VERSION ""

NS_ :

BS_:

BU_: NBICU SBICU NBCMU SBCMU DAPP Vector_XXX

BO_ 2564357898 NBICU10_CellVotlage08: 8 NBICU
 SG_ NBICU10_Cell29Volt : 7|16@0+ (1,0) [0|65535] "mV"  NBCMU
 SG_ NBICU10_Cell30Volt : 23|16@0+ (1,0) [0|65535] "mV"  NBCMU
 SG_ NBICU10_Cell31Volt : 39|16@0+ (1,0) [0|65535] "mV"  NBCMU
 SG_ NBICU10_Cell32Volt : 55|16@0+ (1,0) [0|65535] "mV"  NBCMU

BO_ 2564423434 NBICU10_CellVotlage09: 8 NBICU
 SG_ NBICU10_Cell33Volt : 7|16@0+ (1,0) [0|65535] "mV"  NBCMU
 SG_ NBICU10_Cell34Volt : 23|16@0+ (1,0) [0|65535] "mV"  NBCMU
 SG_ NBICU10_Cell35Volt : 39|16@0+ (1,0) [0|65535] "mV"  NBCMU
 SG_ NBICU10_Cell36Volt : 55|16@0+ (1,0) [0|65535] "mV"  NBCMU

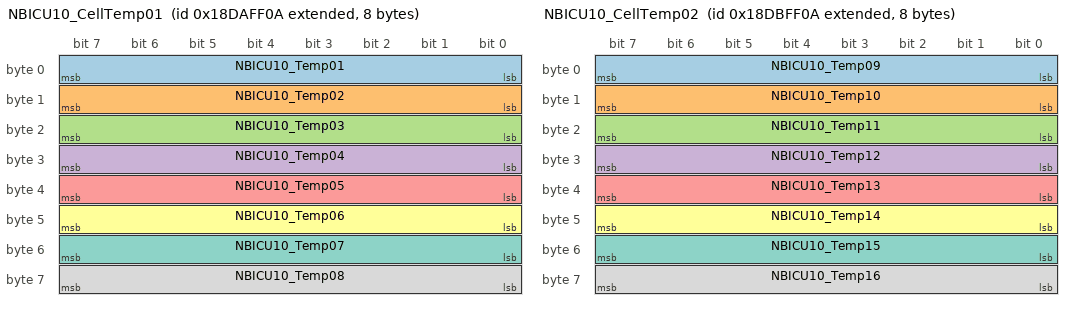
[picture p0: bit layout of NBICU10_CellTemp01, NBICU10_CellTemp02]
BO_ 2564488970 NBICU10_CellTemp01: 8 NBICU
 SG_ NBICU10_Temp01 : 7|8@0+ (1,-40) [-40|215] "℃"  NBCMU
 SG_ NBICU10_Temp02 : 15|8@0+ (1,-40) [-40|215] "℃"  NBCMU
 SG_ NBICU10_Temp03 : 23|8@0+ (1,-40) [-40|215] "℃"  NBCMU
 SG_ NBICU10_Temp04 : 31|8@0+ (1,-40) [-40|215] "℃"  NBCMU
 SG_ NBICU10_Temp05 : 39|8@0+ (1,-40) [-40|215] "℃"  NBCMU
 SG_ NBICU10_Temp06 : 47|8@0+ (1,-40) [-40|215] "℃"  NBCMU
 SG_ NBICU10_Temp07 : 55|8@0+ (1,-40) [-40|215] "℃"  NBCMU
 SG_ NBICU10_Temp08 : 63|8@0+ (1,-40) [-40|215] "℃"  NBCMU

BO_ 2564554506 NBICU10_CellTemp02: 8 NBICU
 SG_ NBICU10_Temp09 : 7|8@0+ (1,-40) [-40|215] "℃"  NBCMU
 SG_ NBICU10_Temp10 : 15|8@0+ (1,-40) [-40|215] "℃"  NBCMU
 SG_ NBICU10_Temp11 : 23|8@0+ (1,-40) [-40|215] "℃"  NBCMU
 SG_ NBICU10_Temp12 : 31|8@0+ (1,-40) [-40|215] "℃"  NBCMU
 SG_ NBICU10_Temp13 : 39|8@0+ (1,-40) [-40|215] "℃"  NBCMU
 SG_ NBICU10_Temp14 : 47|8@0+ (1,-40) [-40|215] "℃"  NBCMU
 SG_ NBICU10_Temp15 : 55|8@0+ (1,-40) [-40|215] "℃"  NBCMU
 SG_ NBICU10_Temp16 : 63|8@0+ (1,-40) [-40|215] "℃"  NBCMU

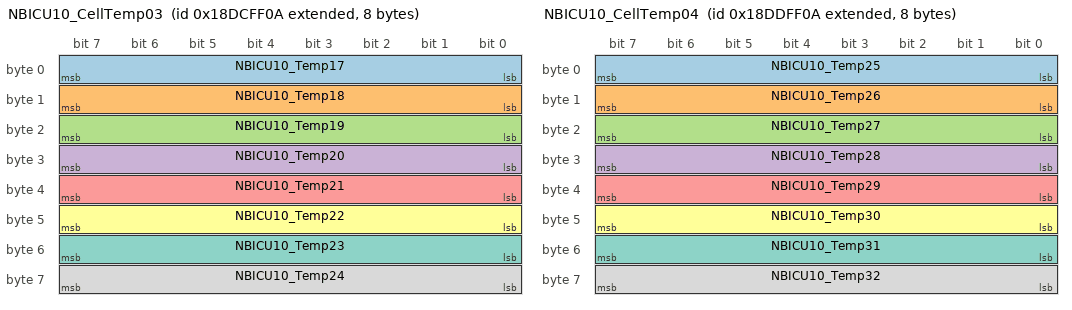
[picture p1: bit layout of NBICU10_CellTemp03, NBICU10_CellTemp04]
BO_ 2564620042 NBICU10_CellTemp03: 8 NBICU
 SG_ NBICU10_Temp17 : 7|8@0+ (1,-40) [-40|215] "℃"  NBCMU
 SG_ NBICU10_Temp18 : 15|8@0+ (1,-40) [-40|215] "℃"  NBCMU
 SG_ NBICU10_Temp19 : 23|8@0+ (1,-40) [-40|215] "℃"  NBCMU
 SG_ NBICU10_Temp20 : 31|8@0+ (1,-40) [-40|215] "℃"  NBCMU
 SG_ NBICU10_Temp21 : 39|8@0+ (1,-40) [-40|215] "℃"  NBCMU
 SG_ NBICU10_Temp22 : 47|8@0+ (1,-40) [-40|215] "℃"  NBCMU
 SG_ NBICU10_Temp23 : 55|8@0+ (1,-40) [-40|215] "℃"  NBCMU
 SG_ NBICU10_Temp24 : 63|8@0+ (1,-40) [-40|215] "℃"  NBCMU

BO_ 2564685578 NBICU10_CellTemp04: 8 NBICU
 SG_ NBICU10_Temp25 : 7|8@0+ (1,-40) [-40|215] "℃"  NBCMU
 SG_ NBICU10_Temp26 : 15|8@0+ (1,-40) [-40|215] "℃"  NBCMU
 SG_ NBICU10_Temp27 : 23|8@0+ (1,-40) [-40|215] "℃"  NBCMU
 SG_ NBICU10_Temp28 : 31|8@0+ (1,-40) [-40|215] "℃"  NBCMU
 SG_ NBICU10_Temp29 : 39|8@0+ (1,-40) [-40|215] "℃"  NBCMU
 SG_ NBICU10_Temp30 : 47|8@0+ (1,-40) [-40|215] "℃"  NBCMU
 SG_ NBICU10_Temp31 : 55|8@0+ (1,-40) [-40|215] "℃"  NBCMU
 SG_ NBICU10_Temp32 : 63|8@0+ (1,-40) [-40|215] "℃"  NBCMU

BO_ 2564751114 NBICU10_CellTemp05: 8 NBICU
 SG_ NBICU10_Temp33 : 7|8@0+ (1,-40) [-40|215] "℃"  NBCMU
 SG_ NBICU10_Temp34 : 15|8@0+ (1,-40) [-40|215] "℃"  NBCMU
 SG_ NBICU10_Temp35 : 23|8@0+ (1,-40) [-40|215] "℃"  NBCMU
 SG_ NBICU10_Temp36 : 31|8@0+ (1,-40) [-40|215] "℃"  NBCMU

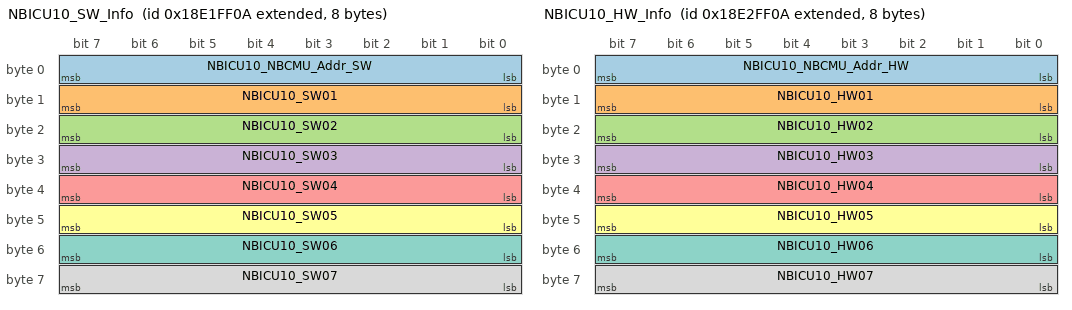
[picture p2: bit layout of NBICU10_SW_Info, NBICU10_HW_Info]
BO_ 2564947722 NBICU10_SW_Info: 8 NBICU
 SG_ NBICU10_NBCMU_Addr_SW : 7|8@0+ (1,0) [0|255] ""  NBCMU
 SG_ NBICU10_SW01 : 15|8@0+ (1,0) [0|255] ""  NBCMU
 SG_ NBICU10_SW02 : 23|8@0+ (1,0) [0|255] ""  NBCMU
 SG_ NBICU10_SW03 : 31|8@0+ (1,0) [0|255] ""  NBCMU
 SG_ NBICU10_SW04 : 39|8@0+ (1,0) [0|255] ""  NBCMU
 SG_ NBICU10_SW05 : 47|8@0+ (1,0) [0|255] ""  NBCMU
 SG_ NBICU10_SW06 : 55|8@0+ (1,0) [0|255] ""  NBCMU
 SG_ NBICU10_SW07 : 63|8@0+ (1,0) [0|255] ""  NBCMU

BO_ 2565013258 NBICU10_HW_Info: 8 NBICU
 SG_ NBICU10_NBCMU_Addr_HW : 7|8@0+ (1,0) [0|255] ""  NBCMU
 SG_ NBICU10_HW01 : 15|8@0+ (1,0) [0|255] ""  NBCMU
 SG_ NBICU10_HW02 : 23|8@0+ (1,0) [0|255] ""  NBCMU
 SG_ NBICU10_HW03 : 31|8@0+ (1,0) [0|255] ""  NBCMU
 SG_ NBICU10_HW04 : 39|8@0+ (1,0) [0|255] ""  NBCMU
 SG_ NBICU10_HW05 : 47|8@0+ (1,0) [0|255] ""  NBCMU
 SG_ NBICU10_HW06 : 55|8@0+ (1,0) [0|255] ""  NBCMU
 SG_ NBICU10_HW07 : 63|8@0+ (1,0) [0|255] ""  NBCMU

BO_ 2564677386 NBICU10_DiaResponse: 8 NBICU
 SG_ NBICU10_RespData : 7|64@0+ (1,0) [0|1.84467440737096E+019] ""  Vector_XXX

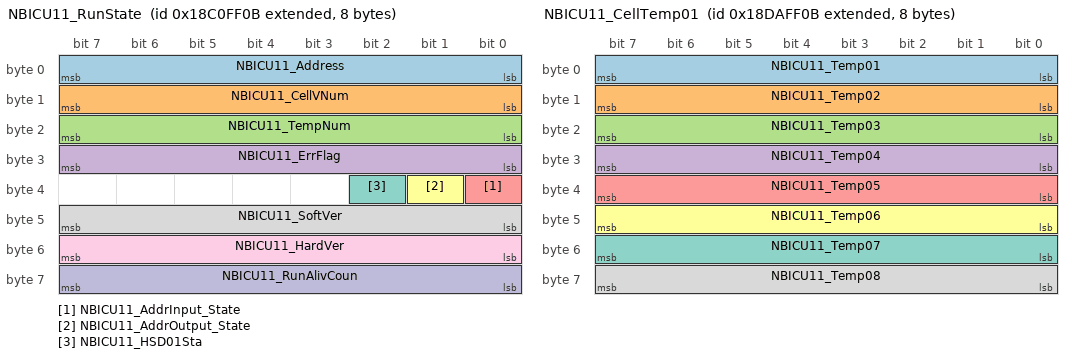
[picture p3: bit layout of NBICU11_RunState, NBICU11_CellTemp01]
BO_ 2562785035 NBICU11_RunState: 8 NBICU
 SG_ NBICU11_Address : 7|8@0+ (1,0) [0|255] ""  NBCMU
 SG_ NBICU11_CellVNum : 15|8@0+ (1,0) [0|255] ""  NBCMU
 SG_ NBICU11_TempNum : 23|8@0+ (1,0) [0|255] ""  NBCMU
 SG_ NBICU11_ErrFlag : 31|8@0+ (1,0) [0|255] ""  NBCMU
 SG_ NBICU11_AddrInput_State : 32|1@0+ (1,0) [0|1] ""  NBCMU
 SG_ NBICU11_AddrOutput_State : 33|1@0+ (1,0) [0|1] ""  NBCMU
 SG_ NBICU11_HSD01Sta : 34|1@0+ (1,0) [0|1] ""  NBCMU
 SG_ NBICU11_SoftVer : 47|8@0+ (1,0) [0|255] ""  NBCMU
 SG_ NBICU11_HardVer : 55|8@0+ (1,0) [0|255] ""  NBCMU
 SG_ NBICU11_RunAlivCoun : 63|8@0+ (1,0) [0|255] ""  NBCMU

BO_ 2562850571 NBICU11_VoltExtremeInfo: 8 NBICU
 SG_ NBICU11_CellVoltMax : 7|16@0+ (1,0) [0|65535] "mV"  NBCMU
 SG_ NBICU11_CellVoltMin : 23|16@0+ (1,0) [0|65535] "mV"  NBCMU
 SG_ NBICU11_CellVoltMaxCode : 39|8@0+ (1,0) [0|255] ""  NBCMU
 SG_ NBICU11_CellVoltMinCode : 47|8@0+ (1,0) [0|255] ""  NBCMU
 SG_ NBICU11_CellSumVolt : 55|16@0+ (0.1,0) [0|6553.5] "V"  NBCMU

BO_ 2562916107 NBICU11_TempExtremeInfo: 8 NBICU
 SG_ NBICU11_CellTempMax : 7|8@0+ (1,-40) [-40|215] "℃"  NBCMU
 SG_ NBICU11_CellTempMin : 15|8@0+ (1,-40) [-40|215] "℃"  NBCMU
 SG_ NBICU11_CellTempAvg : 23|8@0+ (1,-40) [-40|215] "℃"  NBCMU
 SG_ NBICU11_CellTempMaxCode : 31|8@0+ (1,0) [0|255] ""  NBCMU
 SG_ NBICU11_CellTempMinCode : 39|8@0+ (1,0) [0|255] ""  NBCMU
 SG_ NBICU11_SupplyVolt : 40|9@0+ (0.1,0) [0|51.1] "V"  NBCMU
 SG_ NBICU11_PCB_Temp : 63|8@0+ (1,-40) [-40|215] "℃"  NBCMU

BO_ 2562981643 NBICU11_BalState: 8 NBICU
 SG_ NBICU11_Cell0108BalaSta : 7|8@0+ (1,0) [0|255] ""  NBCMU
 SG_ NBICU11_Cell0916BalaSta : 15|8@0+ (1,0) [0|255] ""  NBCMU
 SG_ NBICU11_Cell1724BalaSta : 23|8@0+ (1,0) [0|255] ""  NBCMU
 SG_ NBICU11_Cell2532BalaSta : 31|8@0+ (1,0) [0|255] ""  NBCMU
 SG_ NBICU11_Cell3336BalaSta : 35|4@0+ (1,0) [0|15] ""  NBCMU
 SG_ NBICU11_SysSOH : 47|8@0+ (1,0) [0|100] "%"  NBCMU
 SG_ NBICU11_CycleTime : 55|16@0+ (1,0) [0|65535] ""  NBCMU

BO_ 2563899147 NBICU11_CellVotlage01: 8 NBICU
 SG_ NBICU11_Cell01Volt : 7|16@0+ (1,0) [0|65535] "mV"  NBCMU
 SG_ NBICU11_Cell02Volt : 23|16@0+ (1,0) [0|65535] "mV"  NBCMU
 SG_ NBICU11_Cell03Volt : 39|16@0+ (1,0) [0|65535] "mV"  NBCMU
 SG_ NBICU11_Cell04Volt : 55|16@0+ (1,0) [0|65535] "mV"  NBCMU

BO_ 2563964683 NBICU11_CellVotlage02: 8 NBICU
 SG_ NBICU11_Cell05Volt : 7|16@0+ (1,0) [0|65535] "mV"  NBCMU
 SG_ NBICU11_Cell06Volt : 23|16@0+ (1,0) [0|65535] "mV"  NBCMU
 SG_ NBICU11_Cell07Volt : 39|16@0+ (1,0) [0|65535] "mV"  NBCMU
 SG_ NBICU11_Cell08Volt : 55|16@0+ (1,0) [0|65535] "mV"  NBCMU

BO_ 2564030219 NBICU11_CellVotlage03: 8 NBICU
 SG_ NBICU11_Cell09Volt : 7|16@0+ (1,0) [0|65535] "mV"  NBCMU
 SG_ NBICU11_Cell10Volt : 23|16@0+ (1,0) [0|65535] "mV"  NBCMU
 SG_ NBICU11_Cell11Volt : 39|16@0+ (1,0) [0|65535] "mV"  NBCMU
 SG_ NBICU11_Cell12Volt : 55|16@0+ (1,0) [0|65535] "mV"  NBCMU

BO_ 2564095755 NBICU11_CellVotlage04: 8 NBICU
 SG_ NBICU11_Cell13Volt : 7|16@0+ (1,0) [0|65535] "mV"  NBCMU
 SG_ NBICU11_Cell14Volt : 23|16@0+ (1,0) [0|65535] "mV"  NBCMU
 SG_ NBICU11_Cell15Volt : 39|16@0+ (1,0) [0|65535] "mV"  NBCMU
 SG_ NBICU11_Cell16Volt : 55|16@0+ (1,0) [0|65535] "mV"  NBCMU

BO_ 2564161291 NBICU11_CellVotlage05: 8 NBICU
 SG_ NBICU11_Cell17Volt : 7|16@0+ (1,0) [0|65535] "mV"  NBCMU
 SG_ NBICU11_Cell18Volt : 23|16@0+ (1,0) [0|65535] "mV"  NBCMU
 SG_ NBICU11_Cell19Volt : 39|16@0+ (1,0) [0|65535] "mV"  NBCMU
 SG_ NBICU11_Cell20Volt : 55|16@0+ (1,0) [0|65535] "mV"  NBCMU

BO_ 2564226827 NBICU11_CellVotlage06: 8 NBICU
 SG_ NBICU11_Cell21Volt : 7|16@0+ (1,0) [0|65535] "mV"  NBCMU
 SG_ NBICU11_Cell22Volt : 23|16@0+ (1,0) [0|65535] "mV"  NBCMU
 SG_ NBICU11_Cell23Volt : 39|16@0+ (1,0) [0|65535] "mV"  NBCMU
 SG_ NBICU11_Cell24Volt : 55|16@0+ (1,0) [0|65535] "mV"  NBCMU

BO_ 2564292363 NBICU11_CellVotlage07: 8 NBICU
 SG_ NBICU11_Cell25Volt : 7|16@0+ (1,0) [0|65535] "mV"  NBCMU
 SG_ NBICU11_Cell26Volt : 23|16@0+ (1,0) [0|65535] "mV"  NBCMU
 SG_ NBICU11_Cell27Volt : 39|16@0+ (1,0) [0|65535] "mV"  NBCMU
 SG_ NBICU11_Cell28Volt : 55|16@0+ (1,0) [0|65535] "mV"  NBCMU

BO_ 2564357899 NBICU11_CellVotlage08: 8 NBICU
 SG_ NBICU11_Cell29Volt : 7|16@0+ (1,0) [0|65535] "mV"  NBCMU
 SG_ NBICU11_Cell30Volt : 23|16@0+ (1,0) [0|65535] "mV"  NBCMU
 SG_ NBICU11_Cell31Volt : 39|16@0+ (1,0) [0|65535] "mV"  NBCMU
 SG_ NBICU11_Cell32Volt : 55|16@0+ (1,0) [0|65535] "mV"  NBCMU

BO_ 2564423435 NBICU11_CellVotlage09: 8 NBICU
 SG_ NBICU11_Cell33Volt : 7|16@0+ (1,0) [0|65535] "mV"  NBCMU
 SG_ NBICU11_Cell34Volt : 23|16@0+ (1,0) [0|65535] "mV"  NBCMU
 SG_ NBICU11_Cell35Volt : 39|16@0+ (1,0) [0|65535] "mV"  NBCMU
 SG_ NBICU11_Cell36Volt : 55|16@0+ (1,0) [0|65535] "mV"  NBCMU

BO_ 2564488971 NBICU11_CellTemp01: 8 NBICU
 SG_ NBICU11_Temp01 : 7|8@0+ (1,-40) [-40|215] "℃"  NBCMU
 SG_ NBICU11_Temp02 : 15|8@0+ (1,-40) [-40|215] "℃"  NBCMU
 SG_ NBICU11_Temp03 : 23|8@0+ (1,-40) [-40|215] "℃"  NBCMU
 SG_ NBICU11_Temp04 : 31|8@0+ (1,-40) [-40|215] "℃"  NBCMU
 SG_ NBICU11_Temp05 : 39|8@0+ (1,-40) [-40|215] "℃"  NBCMU
 SG_ NBICU11_Temp06 : 47|8@0+ (1,-40) [-40|215] "℃"  NBCMU
 SG_ NBICU11_Temp07 : 55|8@0+ (1,-40) [-40|215] "℃"  NBCMU
 SG_ NBICU11_Temp08 : 63|8@0+ (1,-40) [-40|215] "℃"  NBCMU

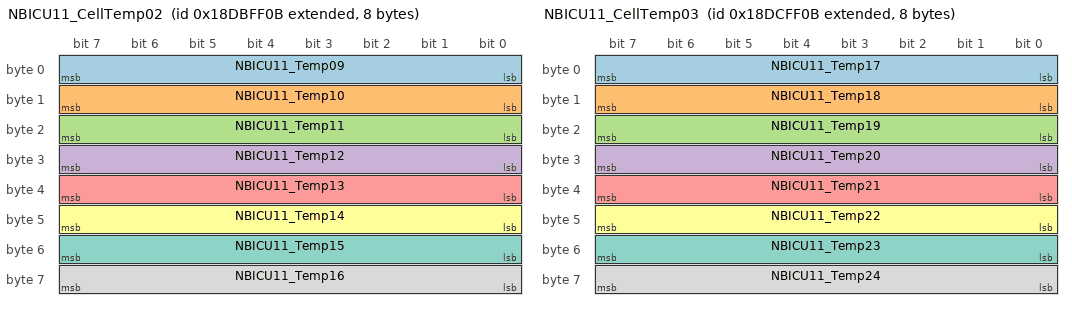
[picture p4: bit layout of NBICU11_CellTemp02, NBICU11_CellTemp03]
BO_ 2564554507 NBICU11_CellTemp02: 8 NBICU
 SG_ NBICU11_Temp09 : 7|8@0+ (1,-40) [-40|215] "℃"  NBCMU
 SG_ NBICU11_Temp10 : 15|8@0+ (1,-40) [-40|215] "℃"  NBCMU
 SG_ NBICU11_Temp11 : 23|8@0+ (1,-40) [-40|215] "℃"  NBCMU
 SG_ NBICU11_Temp12 : 31|8@0+ (1,-40) [-40|215] "℃"  NBCMU
 SG_ NBICU11_Temp13 : 39|8@0+ (1,-40) [-40|215] "℃"  NBCMU
 SG_ NBICU11_Temp14 : 47|8@0+ (1,-40) [-40|215] "℃"  NBCMU
 SG_ NBICU11_Temp15 : 55|8@0+ (1,-40) [-40|215] "℃"  NBCMU
 SG_ NBICU11_Temp16 : 63|8@0+ (1,-40) [-40|215] "℃"  NBCMU

BO_ 2564620043 NBICU11_CellTemp03: 8 NBICU
 SG_ NBICU11_Temp17 : 7|8@0+ (1,-40) [-40|215] "℃"  NBCMU
 SG_ NBICU11_Temp18 : 15|8@0+ (1,-40) [-40|215] "℃"  NBCMU
 SG_ NBICU11_Temp19 : 23|8@0+ (1,-40) [-40|215] "℃"  NBCMU
 SG_ NBICU11_Temp20 : 31|8@0+ (1,-40) [-40|215] "℃"  NBCMU
 SG_ NBICU11_Temp21 : 39|8@0+ (1,-40) [-40|215] "℃"  NBCMU
 SG_ NBICU11_Temp22 : 47|8@0+ (1,-40) [-40|215] "℃"  NBCMU
 SG_ NBICU11_Temp23 : 55|8@0+ (1,-40) [-40|215] "℃"  NBCMU
 SG_ NBICU11_Temp24 : 63|8@0+ (1,-40) [-40|215] "℃"  NBCMU

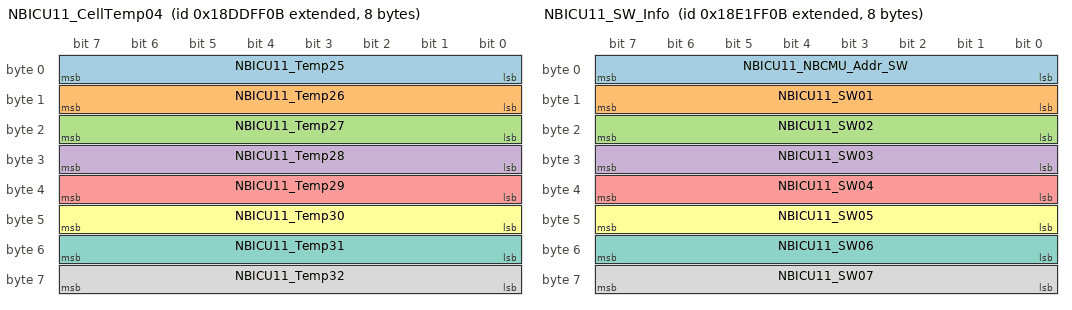
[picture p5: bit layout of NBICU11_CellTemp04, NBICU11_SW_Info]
BO_ 2564685579 NBICU11_CellTemp04: 8 NBICU
 SG_ NBICU11_Temp25 : 7|8@0+ (1,-40) [-40|215] "℃"  NBCMU
 SG_ NBICU11_Temp26 : 15|8@0+ (1,-40) [-40|215] "℃"  NBCMU
 SG_ NBICU11_Temp27 : 23|8@0+ (1,-40) [-40|215] "℃"  NBCMU
 SG_ NBICU11_Temp28 : 31|8@0+ (1,-40) [-40|215] "℃"  NBCMU
 SG_ NBICU11_Temp29 : 39|8@0+ (1,-40) [-40|215] "℃"  NBCMU
 SG_ NBICU11_Temp30 : 47|8@0+ (1,-40) [-40|215] "℃"  NBCMU
 SG_ NBICU11_Temp31 : 55|8@0+ (1,-40) [-40|215] "℃"  NBCMU
 SG_ NBICU11_Temp32 : 63|8@0+ (1,-40) [-40|215] "℃"  NBCMU

BO_ 2564751115 NBICU11_CellTemp05: 8 NBICU
 SG_ NBICU11_Temp33 : 7|8@0+ (1,-40) [-40|215] "℃"  NBCMU
 SG_ NBICU11_Temp34 : 15|8@0+ (1,-40) [-40|215] "℃"  NBCMU
 SG_ NBICU11_Temp35 : 23|8@0+ (1,-40) [-40|215] "℃"  NBCMU
 SG_ NBICU11_Temp36 : 31|8@0+ (1,-40) [-40|215] "℃"  NBCMU

BO_ 2564947723 NBICU11_SW_Info: 8 NBICU
 SG_ NBICU11_NBCMU_Addr_SW : 7|8@0+ (1,0) [0|255] ""  NBCMU
 SG_ NBICU11_SW01 : 15|8@0+ (1,0) [0|255] ""  NBCMU
 SG_ NBICU11_SW02 : 23|8@0+ (1,0) [0|255] ""  NBCMU
 SG_ NBICU11_SW03 : 31|8@0+ (1,0) [0|255] ""  NBCMU
 SG_ NBICU11_SW04 : 39|8@0+ (1,0) [0|255] ""  NBCMU
 SG_ NBICU11_SW05 : 47|8@0+ (1,0) [0|255] ""  NBCMU
 SG_ NBICU11_SW06 : 55|8@0+ (1,0) [0|255] ""  NBCMU
 SG_ NBICU11_SW07 : 63|8@0+ (1,0) [0|255] ""  NBCMU

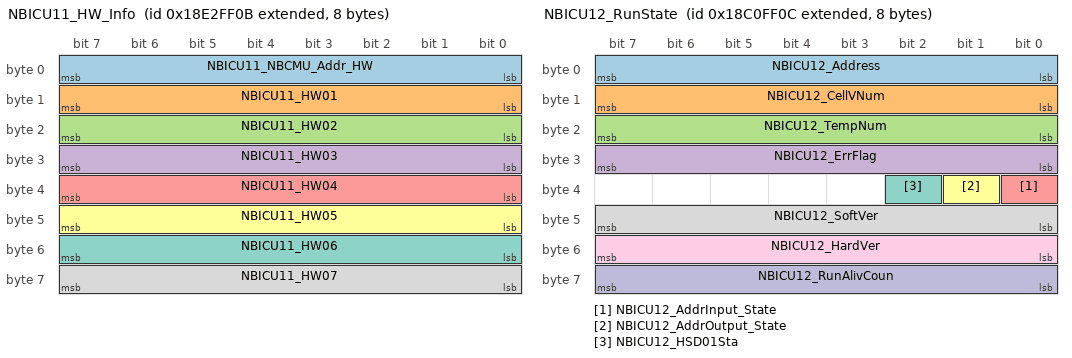
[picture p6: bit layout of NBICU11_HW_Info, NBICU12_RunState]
BO_ 2565013259 NBICU11_HW_Info: 8 NBICU
 SG_ NBICU11_NBCMU_Addr_HW : 7|8@0+ (1,0) [0|255] ""  NBCMU
 SG_ NBICU11_HW01 : 15|8@0+ (1,0) [0|255] ""  NBCMU
 SG_ NBICU11_HW02 : 23|8@0+ (1,0) [0|255] ""  NBCMU
 SG_ NBICU11_HW03 : 31|8@0+ (1,0) [0|255] ""  NBCMU
 SG_ NBICU11_HW04 : 39|8@0+ (1,0) [0|255] ""  NBCMU
 SG_ NBICU11_HW05 : 47|8@0+ (1,0) [0|255] ""  NBCMU
 SG_ NBICU11_HW06 : 55|8@0+ (1,0) [0|255] ""  NBCMU
 SG_ NBICU11_HW07 : 63|8@0+ (1,0) [0|255] ""  NBCMU

BO_ 2564677387 NBICU11_DiaResponse: 8 NBICU
 SG_ NBICU11_RespData : 7|64@0+ (1,0) [0|1.84467440737096E+019] ""  Vector_XXX

BO_ 2562785036 NBICU12_RunState: 8 NBICU
 SG_ NBICU12_Address : 7|8@0+ (1,0) [0|255] ""  NBCMU
 SG_ NBICU12_CellVNum : 15|8@0+ (1,0) [0|255] ""  NBCMU
 SG_ NBICU12_TempNum : 23|8@0+ (1,0) [0|255] ""  NBCMU
 SG_ NBICU12_ErrFlag : 31|8@0+ (1,0) [0|255] ""  NBCMU
 SG_ NBICU12_AddrInput_State : 32|1@0+ (1,0) [0|1] ""  NBCMU
 SG_ NBICU12_AddrOutput_State : 33|1@0+ (1,0) [0|1] ""  NBCMU
 SG_ NBICU12_HSD01Sta : 34|1@0+ (1,0) [0|1] ""  NBCMU
 SG_ NBICU12_SoftVer : 47|8@0+ (1,0) [0|255] ""  NBCMU
 SG_ NBICU12_HardVer : 55|8@0+ (1,0) [0|255] ""  NBCMU
 SG_ NBICU12_RunAlivCoun : 63|8@0+ (1,0) [0|255] ""  NBCMU

BO_ 2562850572 NBICU12_VoltExtremeInfo: 8 NBICU
 SG_ NBICU12_CellVoltMax : 7|16@0+ (1,0) [0|65535] "mV"  NBCMU
 SG_ NBICU12_CellVoltMin : 23|16@0+ (1,0) [0|65535] "mV"  NBCMU
 SG_ NBICU12_CellVoltMaxCode : 39|8@0+ (1,0) [0|255] ""  NBCMU
 SG_ NBICU12_CellVoltMinCode : 47|8@0+ (1,0) [0|255] ""  NBCMU
 SG_ NBICU12_CellSumVolt : 55|16@0+ (0.1,0) [0|6553.5] "V"  NBCMU

BO_ 2562916108 NBICU12_TempExtremeInfo: 8 NBICU
 SG_ NBICU12_CellTempMax : 7|8@0+ (1,-40) [-40|215] "℃"  NBCMU
 SG_ NBICU12_CellTempMin : 15|8@0+ (1,-40) [-40|215] "℃"  NBCMU
 SG_ NBICU12_CellTempAvg : 23|8@0+ (1,-40) [-40|215] "℃"  NBCMU
 SG_ NBICU12_CellTempMaxCode : 31|8@0+ (1,0) [0|255] ""  NBCMU
 SG_ NBICU12_CellTempMinCode : 39|8@0+ (1,0) [0|255] ""  NBCMU
 SG_ NBICU12_SupplyVolt : 40|9@0+ (0.1,0) [0|51.1] "V"  NBCMU
 SG_ NBICU12_PCB_Temp : 63|8@0+ (1,-40) [-40|215] "℃"  NBCMU

BO_ 2562981644 NBICU12_BalState: 8 NBICU
 SG_ NBICU12_Cell0108BalaSta : 7|8@0+ (1,0) [0|255] ""  NBCMU
 SG_ NBICU12_Cell0916BalaSta : 15|8@0+ (1,0) [0|255] ""  NBCMU
 SG_ NBICU12_Cell1724BalaSta : 23|8@0+ (1,0) [0|255] ""  NBCMU
 SG_ NBICU12_Cell2532BalaSta : 31|8@0+ (1,0) [0|255] ""  NBCMU
 SG_ NBICU12_Cell3336BalaSta : 35|4@0+ (1,0) [0|15] ""  NBCMU
 SG_ NBICU12_SysSOH : 47|8@0+ (1,0) [0|100] "%"  NBCMU
 SG_ NBICU12_CycleTime : 55|16@0+ (1,0) [0|65535] ""  NBCMU

BO_ 2563899148 NBICU12_CellVotlage01: 8 NBICU
 SG_ NBICU12_Cell01Volt : 7|16@0+ (1,0) [0|65535] "mV"  NBCMU
 SG_ NBICU12_Cell02Volt : 23|16@0+ (1,0) [0|65535] "mV"  NBCMU
 SG_ NBICU12_Cell03Volt : 39|16@0+ (1,0) [0|65535] "mV"  NBCMU
 SG_ NBICU12_Cell04Volt : 55|16@0+ (1,0) [0|65535] "mV"  NBCMU

BO_ 2563964684 NBICU12_CellVotlage02: 8 NBICU
 SG_ NBICU12_Cell05Volt : 7|16@0+ (1,0) [0|65535] "mV"  NBCMU
 SG_ NBICU12_Cell06Volt : 23|16@0+ (1,0) [0|65535] "mV"  NBCMU
 SG_ NBICU12_Cell07Volt : 39|16@0+ (1,0) [0|65535] "mV"  NBCMU
 SG_ NBICU12_Cell08Volt : 55|16@0+ (1,0) [0|65535] "mV"  NBCMU

BO_ 2564030220 NBICU12_CellVotlage03: 8 NBICU
 SG_ NBICU12_Cell09Volt : 7|16@0+ (1,0) [0|65535] "mV"  NBCMU
 SG_ NBICU12_Cell10Volt : 23|16@0+ (1,0) [0|65535] "mV"  NBCMU
 SG_ NBICU12_Cell11Volt : 39|16@0+ (1,0) [0|65535] "mV"  NBCMU
 SG_ NBICU12_Cell12Volt : 55|16@0+ (1,0) [0|65535] "mV"  NBCMU

BO_ 2564095756 NBICU12_CellVotlage04: 8 NBICU
 SG_ NBICU12_Cell13Volt : 7|16@0+ (1,0) [0|65535] "mV"  NBCMU
 SG_ NBICU12_Cell14Volt : 23|16@0+ (1,0) [0|65535] "mV"  NBCMU
 SG_ NBICU12_Cell15Volt : 39|16@0+ (1,0) [0|65535] "mV"  NBCMU
 SG_ NBICU12_Cell16Volt : 55|16@0+ (1,0) [0|65535] "mV"  NBCMU

BO_ 2564161292 NBICU12_CellVotlage05: 8 NBICU
 SG_ NBICU12_Cell17Volt : 7|16@0+ (1,0) [0|65535] "mV"  NBCMU
 SG_ NBICU12_Cell18Volt : 23|16@0+ (1,0) [0|65535] "mV"  NBCMU
 SG_ NBICU12_Cell19Volt : 39|16@0+ (1,0) [0|65535] "mV"  NBCMU
 SG_ NBICU12_Cell20Volt : 55|16@0+ (1,0) [0|65535] "mV"  NBCMU

BO_ 2564226828 NBICU12_CellVotlage06: 8 NBICU
 SG_ NBICU12_Cell21Volt : 7|16@0+ (1,0) [0|65535] "mV"  NBCMU
 SG_ NBICU12_Cell22Volt : 23|16@0+ (1,0) [0|65535] "mV"  NBCMU
 SG_ NBICU12_Cell23Volt : 39|16@0+ (1,0) [0|65535] "mV"  NBCMU
 SG_ NBICU12_Cell24Volt : 55|16@0+ (1,0) [0|65535] "mV"  NBCMU

BO_ 2564292364 NBICU12_CellVotlage07: 8 NBICU
 SG_ NBICU12_Cell25Volt : 7|16@0+ (1,0) [0|65535] "mV"  NBCMU
 SG_ NBICU12_Cell26Volt : 23|16@0+ (1,0) [0|65535] "mV"  NBCMU
 SG_ NBICU12_Cell27Volt : 39|16@0+ (1,0) [0|65535] "mV"  NBCMU
 SG_ NBICU12_Cell28Volt : 55|16@0+ (1,0) [0|65535] "mV"  NBCMU

BO_ 2564357900 NBICU12_CellVotlage08: 8 NBICU
 SG_ NBICU12_Cell29Volt : 7|16@0+ (1,0) [0|65535] "mV"  NBCMU
 SG_ NBICU12_Cell30Volt : 23|16@0+ (1,0) [0|65535] "mV"  NBCMU
 SG_ NBICU12_Cell31Volt : 39|16@0+ (1,0) [0|65535] "mV"  NBCMU
 SG_ NBICU12_Cell32Volt : 55|16@0+ (1,0) [0|65535] "mV"  NBCMU

BO_ 2564423436 NBICU12_CellVotlage09: 8 NBICU
 SG_ NBICU12_Cell33Volt : 7|16@0+ (1,0) [0|65535] "mV"  NBCMU
 SG_ NBICU12_Cell34Volt : 23|16@0+ (1,0) [0|65535] "mV"  NBCMU
 SG_ NBICU12_Cell35Volt : 39|16@0+ (1,0) [0|65535] "mV"  NBCMU
 SG_ NBICU12_Cell36Volt : 55|16@0+ (1,0) [0|65535] "mV"  NBCMU

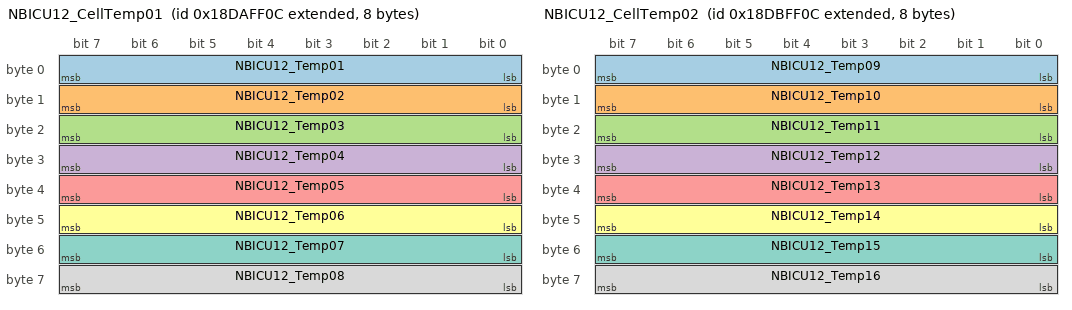
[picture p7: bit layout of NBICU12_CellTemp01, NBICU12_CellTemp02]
BO_ 2564488972 NBICU12_CellTemp01: 8 NBICU
 SG_ NBICU12_Temp01 : 7|8@0+ (1,-40) [-40|215] "℃"  NBCMU
 SG_ NBICU12_Temp02 : 15|8@0+ (1,-40) [-40|215] "℃"  NBCMU
 SG_ NBICU12_Temp03 : 23|8@0+ (1,-40) [-40|215] "℃"  NBCMU
 SG_ NBICU12_Temp04 : 31|8@0+ (1,-40) [-40|215] "℃"  NBCMU
 SG_ NBICU12_Temp05 : 39|8@0+ (1,-40) [-40|215] "℃"  NBCMU
 SG_ NBICU12_Temp06 : 47|8@0+ (1,-40) [-40|215] "℃"  NBCMU
 SG_ NBICU12_Temp07 : 55|8@0+ (1,-40) [-40|215] "℃"  NBCMU
 SG_ NBICU12_Temp08 : 63|8@0+ (1,-40) [-40|215] "℃"  NBCMU

BO_ 2564554508 NBICU12_CellTemp02: 8 NBICU
 SG_ NBICU12_Temp09 : 7|8@0+ (1,-40) [-40|215] "℃"  NBCMU
 SG_ NBICU12_Temp10 : 15|8@0+ (1,-40) [-40|215] "℃"  NBCMU
 SG_ NBICU12_Temp11 : 23|8@0+ (1,-40) [-40|215] "℃"  NBCMU
 SG_ NBICU12_Temp12 : 31|8@0+ (1,-40) [-40|215] "℃"  NBCMU
 SG_ NBICU12_Temp13 : 39|8@0+ (1,-40) [-40|215] "℃"  NBCMU
 SG_ NBICU12_Temp14 : 47|8@0+ (1,-40) [-40|215] "℃"  NBCMU
 SG_ NBICU12_Temp15 : 55|8@0+ (1,-40) [-40|215] "℃"  NBCMU
 SG_ NBICU12_Temp16 : 63|8@0+ (1,-40) [-40|215] "℃"  NBCMU

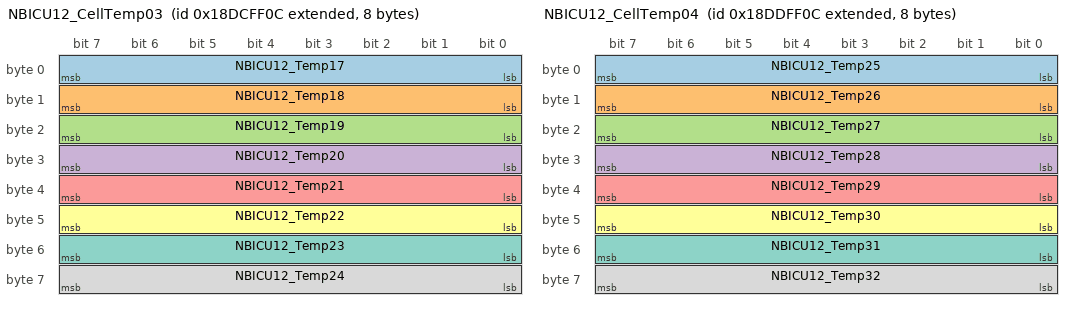
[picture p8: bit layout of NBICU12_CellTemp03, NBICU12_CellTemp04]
BO_ 2564620044 NBICU12_CellTemp03: 8 NBICU
 SG_ NBICU12_Temp17 : 7|8@0+ (1,-40) [-40|215] "℃"  NBCMU
 SG_ NBICU12_Temp18 : 15|8@0+ (1,-40) [-40|215] "℃"  NBCMU
 SG_ NBICU12_Temp19 : 23|8@0+ (1,-40) [-40|215] "℃"  NBCMU
 SG_ NBICU12_Temp20 : 31|8@0+ (1,-40) [-40|215] "℃"  NBCMU
 SG_ NBICU12_Temp21 : 39|8@0+ (1,-40) [-40|215] "℃"  NBCMU
 SG_ NBICU12_Temp22 : 47|8@0+ (1,-40) [-40|215] "℃"  NBCMU
 SG_ NBICU12_Temp23 : 55|8@0+ (1,-40) [-40|215] "℃"  NBCMU
 SG_ NBICU12_Temp24 : 63|8@0+ (1,-40) [-40|215] "℃"  NBCMU

BO_ 2564685580 NBICU12_CellTemp04: 8 NBICU
 SG_ NBICU12_Temp25 : 7|8@0+ (1,-40) [-40|215] "℃"  NBCMU
 SG_ NBICU12_Temp26 : 15|8@0+ (1,-40) [-40|215] "℃"  NBCMU
 SG_ NBICU12_Temp27 : 23|8@0+ (1,-40) [-40|215] "℃"  NBCMU
 SG_ NBICU12_Temp28 : 31|8@0+ (1,-40) [-40|215] "℃"  NBCMU
 SG_ NBICU12_Temp29 : 39|8@0+ (1,-40) [-40|215] "℃"  NBCMU
 SG_ NBICU12_Temp30 : 47|8@0+ (1,-40) [-40|215] "℃"  NBCMU
 SG_ NBICU12_Temp31 : 55|8@0+ (1,-40) [-40|215] "℃"  NBCMU
 SG_ NBICU12_Temp32 : 63|8@0+ (1,-40) [-40|215] "℃"  NBCMU

BO_ 2564751116 NBICU12_CellTemp05: 8 NBICU
 SG_ NBICU12_Temp33 : 7|8@0+ (1,-40) [-40|215] "℃"  NBCMU
 SG_ NBICU12_Temp34 : 15|8@0+ (1,-40) [-40|215] "℃"  NBCMU
 SG_ NBICU12_Temp35 : 23|8@0+ (1,-40) [-40|215] "℃"  NBCMU
 SG_ NBICU12_Temp36 : 31|8@0+ (1,-40) [-40|215] "℃"  NBCMU

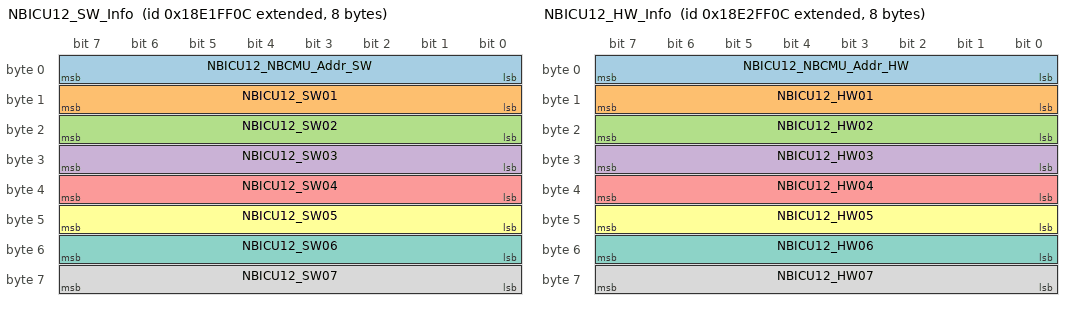
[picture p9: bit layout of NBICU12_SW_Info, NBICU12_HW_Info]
BO_ 2564947724 NBICU12_SW_Info: 8 NBICU
 SG_ NBICU12_NBCMU_Addr_SW : 7|8@0+ (1,0) [0|255] ""  NBCMU
 SG_ NBICU12_SW01 : 15|8@0+ (1,0) [0|255] ""  NBCMU
 SG_ NBICU12_SW02 : 23|8@0+ (1,0) [0|255] ""  NBCMU
 SG_ NBICU12_SW03 : 31|8@0+ (1,0) [0|255] ""  NBCMU
 SG_ NBICU12_SW04 : 39|8@0+ (1,0) [0|255] ""  NBCMU
 SG_ NBICU12_SW05 : 47|8@0+ (1,0) [0|255] ""  NBCMU
 SG_ NBICU12_SW06 : 55|8@0+ (1,0) [0|255] ""  NBCMU
 SG_ NBICU12_SW07 : 63|8@0+ (1,0) [0|255] ""  NBCMU

BO_ 2565013260 NBICU12_HW_Info: 8 NBICU
 SG_ NBICU12_NBCMU_Addr_HW : 7|8@0+ (1,0) [0|255] ""  NBCMU
 SG_ NBICU12_HW01 : 15|8@0+ (1,0) [0|255] ""  NBCMU
 SG_ NBICU12_HW02 : 23|8@0+ (1,0) [0|255] ""  NBCMU
 SG_ NBICU12_HW03 : 31|8@0+ (1,0) [0|255] ""  NBCMU
 SG_ NBICU12_HW04 : 39|8@0+ (1,0) [0|255] ""  NBCMU
 SG_ NBICU12_HW05 : 47|8@0+ (1,0) [0|255] ""  NBCMU
 SG_ NBICU12_HW06 : 55|8@0+ (1,0) [0|255] ""  NBCMU
 SG_ NBICU12_HW07 : 63|8@0+ (1,0) [0|255] ""  NBCMU

BO_ 2564677388 NBICU12_DiaResponse: 8 NBICU
 SG_ NBICU12_RespData : 7|64@0+ (1,0) [0|1.84467440737096E+019] ""  Vector_XXX

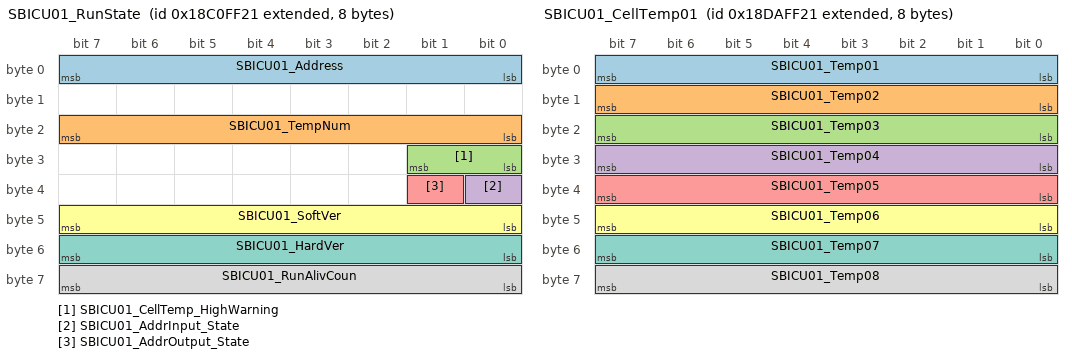
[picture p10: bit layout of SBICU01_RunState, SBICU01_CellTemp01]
BO_ 2562785057 SBICU01_RunState: 8 SBICU
 SG_ SBICU01_Address : 7|8@0+ (1,0) [0|255] ""  NBCMU,SBCMU
 SG_ SBICU01_TempNum : 23|8@0+ (1,0) [0|255] ""  NBCMU,SBCMU
 SG_ SBICU01_CellTemp_HighWarning : 25|2@0+ (1,0) [0|3] ""  NBCMU,SBCMU
 SG_ SBICU01_AddrInput_State : 32|1@0+ (1,0) [0|1] ""  NBCMU,SBCMU
 SG_ SBICU01_AddrOutput_State : 33|1@0+ (1,0) [0|1] ""  NBCMU,SBCMU
 SG_ SBICU01_SoftVer : 47|8@0+ (1,0) [0|255] ""  NBCMU,SBCMU
 SG_ SBICU01_HardVer : 55|8@0+ (1,0) [0|255] ""  NBCMU,SBCMU
 SG_ SBICU01_RunAlivCoun : 63|8@0+ (1,0) [0|255] ""  NBCMU,SBCMU

BO_ 2562916129 SBICU01_TempExtremeInfo: 8 SBICU
 SG_ SBICU01_CellTempMax : 7|8@0+ (1,-40) [-40|215] "℃"  NBCMU,SBCMU
 SG_ SBICU01_CellTempMin : 15|8@0+ (1,-40) [-40|215] "℃"  NBCMU,SBCMU
 SG_ SBICU01_CellTempAvg : 23|8@0+ (1,-40) [-40|215] "℃"  NBCMU,SBCMU
 SG_ SBICU01_CellTempMaxCode : 31|8@0+ (1,0) [0|255] ""  NBCMU,SBCMU
 SG_ SBICU01_CellTempMinCode : 39|8@0+ (1,0) [0|255] ""  NBCMU,SBCMU
 SG_ SBICU01_SupplyVolt : 40|9@0+ (0.1,0) [0|51.1] "V"  NBCMU,SBCMU

BO_ 2564488993 SBICU01_CellTemp01: 8 SBICU
 SG_ SBICU01_Temp01 : 7|8@0+ (1,-40) [-40|215] "℃"  SBCMU
 SG_ SBICU01_Temp02 : 15|8@0+ (1,-40) [-40|215] "℃"  SBCMU
 SG_ SBICU01_Temp03 : 23|8@0+ (1,-40) [-40|215] "℃"  SBCMU
 SG_ SBICU01_Temp04 : 31|8@0+ (1,-40) [-40|215] "℃"  SBCMU
 SG_ SBICU01_Temp05 : 39|8@0+ (1,-40) [-40|215] "℃"  SBCMU
 SG_ SBICU01_Temp06 : 47|8@0+ (1,-40) [-40|215] "℃"  SBCMU
 SG_ SBICU01_Temp07 : 55|8@0+ (1,-40) [-40|215] "℃"  SBCMU
 SG_ SBICU01_Temp08 : 63|8@0+ (1,-40) [-40|215] "℃"  SBCMU

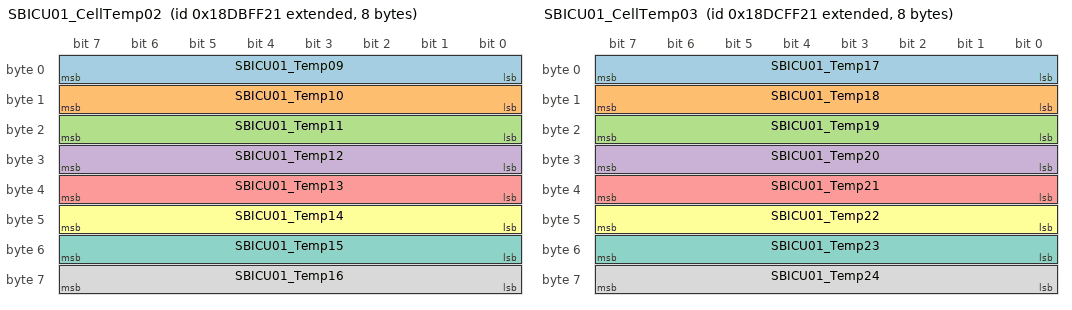
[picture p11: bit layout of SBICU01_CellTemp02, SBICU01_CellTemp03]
BO_ 2564554529 SBICU01_CellTemp02: 8 SBICU
 SG_ SBICU01_Temp09 : 7|8@0+ (1,-40) [-40|215] "℃"  SBCMU
 SG_ SBICU01_Temp10 : 15|8@0+ (1,-40) [-40|215] "℃"  SBCMU
 SG_ SBICU01_Temp11 : 23|8@0+ (1,-40) [-40|215] "℃"  SBCMU
 SG_ SBICU01_Temp12 : 31|8@0+ (1,-40) [-40|215] "℃"  SBCMU
 SG_ SBICU01_Temp13 : 39|8@0+ (1,-40) [-40|215] "℃"  SBCMU
 SG_ SBICU01_Temp14 : 47|8@0+ (1,-40) [-40|215] "℃"  SBCMU
 SG_ SBICU01_Temp15 : 55|8@0+ (1,-40) [-40|215] "℃"  SBCMU
 SG_ SBICU01_Temp16 : 63|8@0+ (1,-40) [-40|215] "℃"  SBCMU

BO_ 2564620065 SBICU01_CellTemp03: 8 SBICU
 SG_ SBICU01_Temp17 : 7|8@0+ (1,-40) [-40|215] "℃"  SBCMU
 SG_ SBICU01_Temp18 : 15|8@0+ (1,-40) [-40|215] "℃"  SBCMU
 SG_ SBICU01_Temp19 : 23|8@0+ (1,-40) [-40|215] "℃"  SBCMU
 SG_ SBICU01_Temp20 : 31|8@0+ (1,-40) [-40|215] "℃"  SBCMU
 SG_ SBICU01_Temp21 : 39|8@0+ (1,-40) [-40|215] "℃"  SBCMU
 SG_ SBICU01_Temp22 : 47|8@0+ (1,-40) [-40|215] "℃"  SBCMU
 SG_ SBICU01_Temp23 : 55|8@0+ (1,-40) [-40|215] "℃"  SBCMU
 SG_ SBICU01_Temp24 : 63|8@0+ (1,-40) [-40|215] "℃"  SBCMU

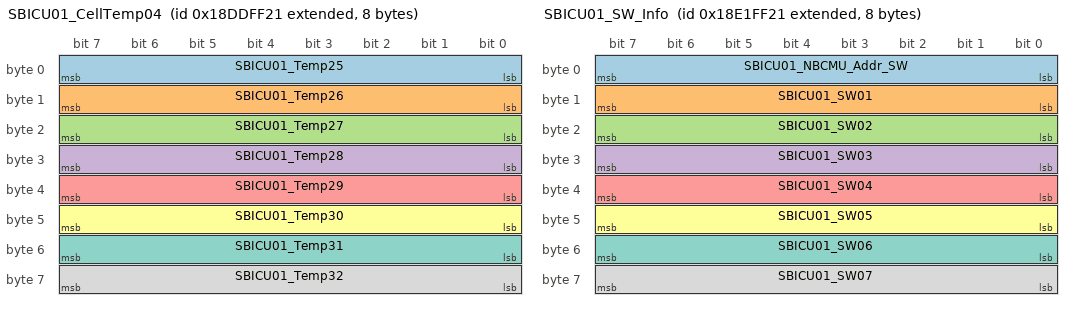
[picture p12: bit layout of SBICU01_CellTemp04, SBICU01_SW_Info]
BO_ 2564685601 SBICU01_CellTemp04: 8 SBICU
 SG_ SBICU01_Temp25 : 7|8@0+ (1,-40) [-40|215] "℃"  SBCMU
 SG_ SBICU01_Temp26 : 15|8@0+ (1,-40) [-40|215] "℃"  SBCMU
 SG_ SBICU01_Temp27 : 23|8@0+ (1,-40) [-40|215] "℃"  SBCMU
 SG_ SBICU01_Temp28 : 31|8@0+ (1,-40) [-40|215] "℃"  SBCMU
 SG_ SBICU01_Temp29 : 39|8@0+ (1,-40) [-40|215] "℃"  SBCMU
 SG_ SBICU01_Temp30 : 47|8@0+ (1,-40) [-40|215] "℃"  SBCMU
 SG_ SBICU01_Temp31 : 55|8@0+ (1,-40) [-40|215] "℃"  SBCMU
 SG_ SBICU01_Temp32 : 63|8@0+ (1,-40) [-40|215] "℃"  SBCMU

BO_ 2564751137 SBICU01_CellTemp05: 8 SBICU
 SG_ SBICU01_Temp33 : 7|8@0+ (1,-40) [-40|215] "℃"  SBCMU
 SG_ SBICU01_Temp34 : 15|8@0+ (1,-40) [-40|215] "℃"  SBCMU
 SG_ SBICU01_Temp35 : 23|8@0+ (1,-40) [-40|215] "℃"  SBCMU
 SG_ SBICU01_Temp36 : 31|8@0+ (1,-40) [-40|215] "℃"  SBCMU

BO_ 2564947745 SBICU01_SW_Info: 8 SBICU
 SG_ SBICU01_NBCMU_Addr_SW : 7|8@0+ (1,0) [0|255] ""  SBCMU
 SG_ SBICU01_SW01 : 15|8@0+ (1,0) [0|255] ""  SBCMU
 SG_ SBICU01_SW02 : 23|8@0+ (1,0) [0|255] ""  SBCMU
 SG_ SBICU01_SW03 : 31|8@0+ (1,0) [0|255] ""  SBCMU
 SG_ SBICU01_SW04 : 39|8@0+ (1,0) [0|255] ""  SBCMU
 SG_ SBICU01_SW05 : 47|8@0+ (1,0) [0|255] ""  SBCMU
 SG_ SBICU01_SW06 : 55|8@0+ (1,0) [0|255] ""  SBCMU
 SG_ SBICU01_SW07 : 63|8@0+ (1,0) [0|255] ""  SBCMU

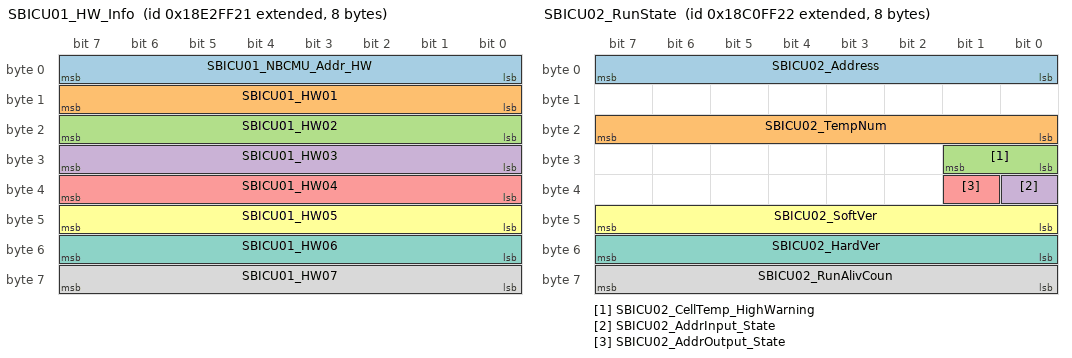
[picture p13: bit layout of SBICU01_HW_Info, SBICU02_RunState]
BO_ 2565013281 SBICU01_HW_Info: 8 SBICU
 SG_ SBICU01_NBCMU_Addr_HW : 7|8@0+ (1,0) [0|255] ""  SBCMU
 SG_ SBICU01_HW01 : 15|8@0+ (1,0) [0|255] ""  SBCMU
 SG_ SBICU01_HW02 : 23|8@0+ (1,0) [0|255] ""  SBCMU
 SG_ SBICU01_HW03 : 31|8@0+ (1,0) [0|255] ""  SBCMU
 SG_ SBICU01_HW04 : 39|8@0+ (1,0) [0|255] ""  SBCMU
 SG_ SBICU01_HW05 : 47|8@0+ (1,0) [0|255] ""  SBCMU
 SG_ SBICU01_HW06 : 55|8@0+ (1,0) [0|255] ""  SBCMU
 SG_ SBICU01_HW07 : 63|8@0+ (1,0) [0|255] ""  SBCMU

BO_ 2564677409 SBICU01_DiaResponse: 8 SBICU
 SG_ SBICU01_RespData : 7|64@0+ (1,0) [0|1.84467440737096E+019] ""  DAPP

BO_ 2562785058 SBICU02_RunState: 8 SBICU
 SG_ SBICU02_Address : 7|8@0+ (1,0) [0|255] ""  NBCMU,SBCMU
 SG_ SBICU02_TempNum : 23|8@0+ (1,0) [0|255] ""  NBCMU,SBCMU
 SG_ SBICU02_CellTemp_HighWarning : 25|2@0+ (1,0) [0|3] ""  NBCMU,SBCMU
 SG_ SBICU02_AddrInput_State : 32|1@0+ (1,0) [0|1] ""  NBCMU,SBCMU
 SG_ SBICU02_AddrOutput_State : 33|1@0+ (1,0) [0|1] ""  NBCMU,SBCMU
 SG_ SBICU02_SoftVer : 47|8@0+ (1,0) [0|255] ""  NBCMU,SBCMU
 SG_ SBICU02_HardVer : 55|8@0+ (1,0) [0|255] ""  NBCMU,SBCMU
 SG_ SBICU02_RunAlivCoun : 63|8@0+ (1,0) [0|255] ""  NBCMU,SBCMU

BO_ 2562916130 SBICU02_TempExtremeInfo: 8 SBICU
 SG_ SBICU02_CellTempMax : 7|8@0+ (1,-40) [-40|215] "℃"  NBCMU,SBCMU
 SG_ SBICU02_CellTempMin : 15|8@0+ (1,-40) [-40|215] "℃"  NBCMU,SBCMU
 SG_ SBICU02_CellTempAvg : 23|8@0+ (1,-40) [-40|215] "℃"  NBCMU,SBCMU
 SG_ SBICU02_CellTempMaxCode : 31|8@0+ (1,0) [0|255] ""  NBCMU,SBCMU
 SG_ SBICU02_CellTempMinCode : 39|8@0+ (1,0) [0|255] ""  NBCMU,SBCMU
 SG_ SBICU02_SupplyVolt : 40|9@0+ (0.1,0) [0|51.1] "V"  NBCMU,SBCMU

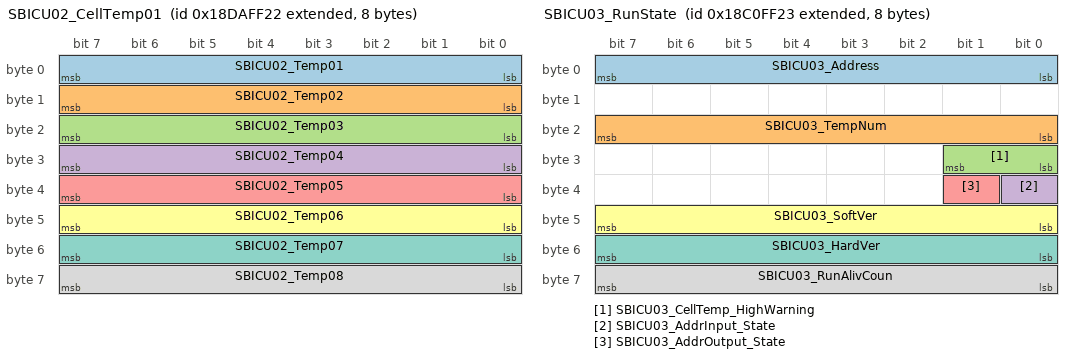
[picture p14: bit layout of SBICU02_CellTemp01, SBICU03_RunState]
BO_ 2564488994 SBICU02_CellTemp01: 8 SBICU
 SG_ SBICU02_Temp01 : 7|8@0+ (1,-40) [-40|215] "℃"  SBCMU
 SG_ SBICU02_Temp02 : 15|8@0+ (1,-40) [-40|215] "℃"  SBCMU
 SG_ SBICU02_Temp03 : 23|8@0+ (1,-40) [-40|215] "℃"  SBCMU
 SG_ SBICU02_Temp04 : 31|8@0+ (1,-40) [-40|215] "℃"  SBCMU
 SG_ SBICU02_Temp05 : 39|8@0+ (1,-40) [-40|215] "℃"  SBCMU
 SG_ SBICU02_Temp06 : 47|8@0+ (1,-40) [-40|215] "℃"  SBCMU
 SG_ SBICU02_Temp07 : 55|8@0+ (1,-40) [-40|215] "℃"  SBCMU
 SG_ SBICU02_Temp08 : 63|8@0+ (1,-40) [-40|215] "℃"  SBCMU

BO_ 2564554530 SBICU02_CellTemp02: 8 SBICU
 SG_ SBICU02_Temp09 : 7|8@0+ (1,-40) [-40|215] "℃"  SBCMU
 SG_ SBICU02_Temp10 : 15|8@0+ (1,-40) [-40|215] "℃"  SBCMU
 SG_ SBICU02_Temp11 : 23|8@0+ (1,-40) [-40|215] "℃"  SBCMU
 SG_ SBICU02_Temp12 : 31|8@0+ (1,-40) [-40|215] "℃"  SBCMU
 SG_ SBICU02_Temp13 : 39|8@0+ (1,-40) [-40|215] "℃"  SBCMU
 SG_ SBICU02_Temp14 : 47|8@0+ (1,-40) [-40|215] "℃"  SBCMU
 SG_ SBICU02_Temp15 : 55|8@0+ (1,-40) [-40|215] "℃"  SBCMU
 SG_ SBICU02_Temp16 : 63|8@0+ (1,-40) [-40|215] "℃"  SBCMU

BO_ 2564620066 SBICU02_CellTemp03: 8 SBICU
 SG_ SBICU02_Temp17 : 7|8@0+ (1,-40) [-40|215] "℃"  SBCMU
 SG_ SBICU02_Temp18 : 15|8@0+ (1,-40) [-40|215] "℃"  SBCMU
 SG_ SBICU02_Temp19 : 23|8@0+ (1,-40) [-40|215] "℃"  SBCMU
 SG_ SBICU02_Temp20 : 31|8@0+ (1,-40) [-40|215] "℃"  SBCMU
 SG_ SBICU02_Temp21 : 39|8@0+ (1,-40) [-40|215] "℃"  SBCMU
 SG_ SBICU02_Temp22 : 47|8@0+ (1,-40) [-40|215] "℃"  SBCMU
 SG_ SBICU02_Temp23 : 55|8@0+ (1,-40) [-40|215] "℃"  SBCMU
 SG_ SBICU02_Temp24 : 63|8@0+ (1,-40) [-40|215] "℃"  SBCMU

BO_ 2564685602 SBICU02_CellTemp04: 8 SBICU
 SG_ SBICU02_Temp25 : 7|8@0+ (1,-40) [-40|215] "℃"  SBCMU
 SG_ SBICU02_Temp26 : 15|8@0+ (1,-40) [-40|215] "℃"  SBCMU
 SG_ SBICU02_Temp27 : 23|8@0+ (1,-40) [-40|215] "℃"  SBCMU
 SG_ SBICU02_Temp28 : 31|8@0+ (1,-40) [-40|215] "℃"  SBCMU
 SG_ SBICU02_Temp29 : 39|8@0+ (1,-40) [-40|215] "℃"  SBCMU
 SG_ SBICU02_Temp30 : 47|8@0+ (1,-40) [-40|215] "℃"  SBCMU
 SG_ SBICU02_Temp31 : 55|8@0+ (1,-40) [-40|215] "℃"  SBCMU
 SG_ SBICU02_Temp32 : 63|8@0+ (1,-40) [-40|215] "℃"  SBCMU

BO_ 2564751138 SBICU02_CellTemp05: 8 SBICU
 SG_ SBICU02_Temp33 : 7|8@0+ (1,-40) [-40|215] "℃"  SBCMU
 SG_ SBICU02_Temp34 : 15|8@0+ (1,-40) [-40|215] "℃"  SBCMU
 SG_ SBICU02_Temp35 : 23|8@0+ (1,-40) [-40|215] "℃"  SBCMU
 SG_ SBICU02_Temp36 : 31|8@0+ (1,-40) [-40|215] "℃"  SBCMU

BO_ 2564947746 SBICU02_SW_Info: 8 SBICU
 SG_ SBICU02_NBCMU_Addr_SW : 7|8@0+ (1,0) [0|255] ""  SBCMU
 SG_ SBICU02_SW01 : 15|8@0+ (1,0) [0|255] ""  SBCMU
 SG_ SBICU02_SW02 : 23|8@0+ (1,0) [0|255] ""  SBCMU
 SG_ SBICU02_SW03 : 31|8@0+ (1,0) [0|255] ""  SBCMU
 SG_ SBICU02_SW04 : 39|8@0+ (1,0) [0|255] ""  SBCMU
 SG_ SBICU02_SW05 : 47|8@0+ (1,0) [0|255] ""  SBCMU
 SG_ SBICU02_SW06 : 55|8@0+ (1,0) [0|255] ""  SBCMU
 SG_ SBICU02_SW07 : 63|8@0+ (1,0) [0|255] ""  SBCMU

BO_ 2565013282 SBICU02_HW_Info: 8 SBICU
 SG_ SBICU02_NBCMU_Addr_HW : 7|8@0+ (1,0) [0|255] ""  SBCMU
 SG_ SBICU02_HW01 : 15|8@0+ (1,0) [0|255] ""  SBCMU
 SG_ SBICU02_HW02 : 23|8@0+ (1,0) [0|255] ""  SBCMU
 SG_ SBICU02_HW03 : 31|8@0+ (1,0) [0|255] ""  SBCMU
 SG_ SBICU02_HW04 : 39|8@0+ (1,0) [0|255] ""  SBCMU
 SG_ SBICU02_HW05 : 47|8@0+ (1,0) [0|255] ""  SBCMU
 SG_ SBICU02_HW06 : 55|8@0+ (1,0) [0|255] ""  SBCMU
 SG_ SBICU02_HW07 : 63|8@0+ (1,0) [0|255] ""  SBCMU

BO_ 2564677410 SBICU02_DiaResponse: 8 SBICU
 SG_ SBICU02_RespData : 7|64@0+ (1,0) [0|1.84467440737096E+019] ""  DAPP

BO_ 2562785059 SBICU03_RunState: 8 SBICU
 SG_ SBICU03_Address : 7|8@0+ (1,0) [0|255] ""  NBCMU,SBCMU
 SG_ SBICU03_TempNum : 23|8@0+ (1,0) [0|255] ""  NBCMU,SBCMU
 SG_ SBICU03_CellTemp_HighWarning : 25|2@0+ (1,0) [0|3] ""  NBCMU,SBCMU
 SG_ SBICU03_AddrInput_State : 32|1@0+ (1,0) [0|1] ""  NBCMU,SBCMU
 SG_ SBICU03_AddrOutput_State : 33|1@0+ (1,0) [0|1] ""  NBCMU,SBCMU
 SG_ SBICU03_SoftVer : 47|8@0+ (1,0) [0|255] ""  NBCMU,SBCMU
 SG_ SBICU03_HardVer : 55|8@0+ (1,0) [0|255] ""  NBCMU,SBCMU
 SG_ SBICU03_RunAlivCoun : 63|8@0+ (1,0) [0|255] ""  NBCMU,SBCMU

BO_ 2562916131 SBICU03_TempExtremeInfo: 8 SBICU
 SG_ SBICU03_CellTempMax : 7|8@0+ (1,-40) [-40|215] "℃"  NBCMU,SBCMU
 SG_ SBICU03_CellTempMin : 15|8@0+ (1,-40) [-40|215] "℃"  NBCMU,SBCMU
 SG_ SBICU03_CellTempAvg : 23|8@0+ (1,-40) [-40|215] "℃"  NBCMU,SBCMU
 SG_ SBICU03_CellTempMaxCode : 31|8@0+ (1,0) [0|255] ""  NBCMU,SBCMU
 SG_ SBICU03_CellTempMinCode : 39|8@0+ (1,0) [0|255] ""  NBCMU,SBCMU
 SG_ SBICU03_SupplyVolt : 40|9@0+ (0.1,0) [0|51.1] "V"  NBCMU,SBCMU

BO_ 2564488995 SBICU03_CellTemp01: 8 SBICU
 SG_ SBICU03_Temp01 : 7|8@0+ (1,-40) [-40|215] "℃"  SBCMU
 SG_ SBICU03_Temp02 : 15|8@0+ (1,-40) [-40|215] "℃"  SBCMU
 SG_ SBICU03_Temp03 : 23|8@0+ (1,-40) [-40|215] "℃"  SBCMU
 SG_ SBICU03_Temp04 : 31|8@0+ (1,-40) [-40|215] "℃"  SBCMU
 SG_ SBICU03_Temp05 : 39|8@0+ (1,-40) [-40|215] "℃"  SBCMU
 SG_ SBICU03_Temp06 : 47|8@0+ (1,-40) [-40|215] "℃"  SBCMU
 SG_ SBICU03_Temp07 : 55|8@0+ (1,-40) [-40|215] "℃"  SBCMU
 SG_ SBICU03_Temp08 : 63|8@0+ (1,-40) [-40|215] "℃"  SBCMU

BO_ 2564554531 SBICU03_CellTemp02: 8 SBICU
 SG_ SBICU03_Temp09 : 7|8@0+ (1,-40) [-40|215] "℃"  SBCMU
 SG_ SBICU03_Temp10 : 15|8@0+ (1,-40) [-40|215] "℃"  SBCMU
 SG_ SBICU03_Temp11 : 23|8@0+ (1,-40) [-40|215] "℃"  SBCMU
 SG_ SBICU03_Temp12 : 31|8@0+ (1,-40) [-40|215] "℃"  SBCMU
 SG_ SBICU03_Temp13 : 39|8@0+ (1,-40) [-40|215] "℃"  SBCMU
 SG_ SBICU03_Temp14 : 47|8@0+ (1,-40) [-40|215] "℃"  SBCMU
 SG_ SBICU03_Temp15 : 55|8@0+ (1,-40) [-40|215] "℃"  SBCMU
 SG_ SBICU03_Temp16 : 63|8@0+ (1,-40) [-40|215] "℃"  SBCMU

BO_ 2564620067 SBICU03_CellTemp03: 8 SBICU
 SG_ SBICU03_Temp17 : 7|8@0+ (1,-40) [-40|215] "℃"  SBCMU
 SG_ SBICU03_Temp18 : 15|8@0+ (1,-40) [-40|215] "℃"  SBCMU
 SG_ SBICU03_Temp19 : 23|8@0+ (1,-40) [-40|215] "℃"  SBCMU
 SG_ SBICU03_Temp20 : 31|8@0+ (1,-40) [-40|215] "℃"  SBCMU
 SG_ SBICU03_Temp21 : 39|8@0+ (1,-40) [-40|215] "℃"  SBCMU
 SG_ SBICU03_Temp22 : 47|8@0+ (1,-40) [-40|215] "℃"  SBCMU
 SG_ SBICU03_Temp23 : 55|8@0+ (1,-40) [-40|215] "℃"  SBCMU
 SG_ SBICU03_Temp24 : 63|8@0+ (1,-40) [-40|215] "℃"  SBCMU

BO_ 2564685603 SBICU03_CellTemp04: 8 SBICU
 SG_ SBICU03_Temp25 : 7|8@0+ (1,-40) [-40|215] "℃"  SBCMU
 SG_ SBICU03_Temp26 : 15|8@0+ (1,-40) [-40|215] "℃"  SBCMU
 SG_ SBICU03_Temp27 : 23|8@0+ (1,-40) [-40|215] "℃"  SBCMU
 SG_ SBICU03_Temp28 : 31|8@0+ (1,-40) [-40|215] "℃"  SBCMU
 SG_ SBICU03_Temp29 : 39|8@0+ (1,-40) [-40|215] "℃"  SBCMU
 SG_ SBICU03_Temp30 : 47|8@0+ (1,-40) [-40|215] "℃"  SBCMU
 SG_ SBICU03_Temp31 : 55|8@0+ (1,-40) [-40|215] "℃"  SBCMU
 SG_ SBICU03_Temp32 : 63|8@0+ (1,-40) [-40|215] "℃"  SBCMU

BO_ 2564751139 SBICU03_CellTemp05: 8 SBICU
 SG_ SBICU03_Temp33 : 7|8@0+ (1,-40) [-40|215] "℃"  SBCMU
 SG_ SBICU03_Temp34 : 15|8@0+ (1,-40) [-40|215] "℃"  SBCMU
 SG_ SBICU03_Temp35 : 23|8@0+ (1,-40) [-40|215] "℃"  SBCMU
 SG_ SBICU03_Temp36 : 31|8@0+ (1,-40) [-40|215] "℃"  SBCMU

BO_ 2564947747 SBICU03_SW_Info: 8 SBICU
 SG_ SBICU03_NBCMU_Addr_SW : 7|8@0+ (1,0) [0|255] ""  SBCMU
 SG_ SBICU03_SW01 : 15|8@0+ (1,0) [0|255] ""  SBCMU
 SG_ SBICU03_SW02 : 23|8@0+ (1,0) [0|255] ""  SBCMU
 SG_ SBICU03_SW03 : 31|8@0+ (1,0) [0|255] ""  SBCMU
 SG_ SBICU03_SW04 : 39|8@0+ (1,0) [0|255] ""  SBCMU
 SG_ SBICU03_SW05 : 47|8@0+ (1,0) [0|255] ""  SBCMU
 SG_ SBICU03_SW06 : 55|8@0+ (1,0) [0|255] ""  SBCMU
 SG_ SBICU03_SW07 : 63|8@0+ (1,0) [0|255] ""  SBCMU

BO_ 2565013283 SBICU03_HW_Info: 8 SBICU
 SG_ SBICU03_NBCMU_Addr_HW : 7|8@0+ (1,0) [0|255] ""  SBCMU
 SG_ SBICU03_HW01 : 15|8@0+ (1,0) [0|255] ""  SBCMU
 SG_ SBICU03_HW02 : 23|8@0+ (1,0) [0|255] ""  SBCMU
 SG_ SBICU03_HW03 : 31|8@0+ (1,0) [0|255] ""  SBCMU
 SG_ SBICU03_HW04 : 39|8@0+ (1,0) [0|255] ""  SBCMU
 SG_ SBICU03_HW05 : 47|8@0+ (1,0) [0|255] ""  SBCMU
 SG_ SBICU03_HW06 : 55|8@0+ (1,0) [0|255] ""  SBCMU
 SG_ SBICU03_HW07 : 63|8@0+ (1,0) [0|255] ""  SBCMU

BO_ 2564677411 SBICU03_DiaResponse: 8 SBICU
 SG_ SBICU03_RespData : 7|64@0+ (1,0) [0|1.84467440737096E+019] ""  DAPP

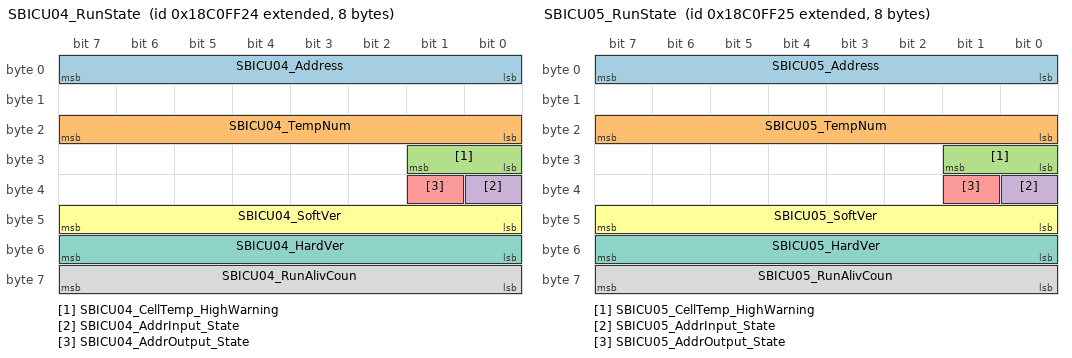
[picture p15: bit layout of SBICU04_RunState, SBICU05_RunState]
BO_ 2562785060 SBICU04_RunState: 8 SBICU
 SG_ SBICU04_Address : 7|8@0+ (1,0) [0|255] ""  NBCMU,SBCMU
 SG_ SBICU04_TempNum : 23|8@0+ (1,0) [0|255] ""  NBCMU,SBCMU
 SG_ SBICU04_CellTemp_HighWarning : 25|2@0+ (1,0) [0|3] ""  NBCMU,SBCMU
 SG_ SBICU04_AddrInput_State : 32|1@0+ (1,0) [0|1] ""  NBCMU,SBCMU
 SG_ SBICU04_AddrOutput_State : 33|1@0+ (1,0) [0|1] ""  NBCMU,SBCMU
 SG_ SBICU04_SoftVer : 47|8@0+ (1,0) [0|255] ""  NBCMU,SBCMU
 SG_ SBICU04_HardVer : 55|8@0+ (1,0) [0|255] ""  NBCMU,SBCMU
 SG_ SBICU04_RunAlivCoun : 63|8@0+ (1,0) [0|255] ""  NBCMU,SBCMU

BO_ 2562916132 SBICU04_TempExtremeInfo: 8 SBICU
 SG_ SBICU04_CellTempMax : 7|8@0+ (1,-40) [-40|215] "℃"  NBCMU,SBCMU
 SG_ SBICU04_CellTempMin : 15|8@0+ (1,-40) [-40|215] "℃"  NBCMU,SBCMU
 SG_ SBICU04_CellTempAvg : 23|8@0+ (1,-40) [-40|215] "℃"  NBCMU,SBCMU
 SG_ SBICU04_CellTempMaxCode : 31|8@0+ (1,0) [0|255] ""  NBCMU,SBCMU
 SG_ SBICU04_CellTempMinCode : 39|8@0+ (1,0) [0|255] ""  NBCMU,SBCMU
 SG_ SBICU04_SupplyVolt : 40|9@0+ (0.1,0) [0|51.1] "V"  NBCMU,SBCMU

BO_ 2564488996 SBICU04_CellTemp01: 8 SBICU
 SG_ SBICU04_Temp01 : 7|8@0+ (1,-40) [-40|215] "℃"  SBCMU
 SG_ SBICU04_Temp02 : 15|8@0+ (1,-40) [-40|215] "℃"  SBCMU
 SG_ SBICU04_Temp03 : 23|8@0+ (1,-40) [-40|215] "℃"  SBCMU
 SG_ SBICU04_Temp04 : 31|8@0+ (1,-40) [-40|215] "℃"  SBCMU
 SG_ SBICU04_Temp05 : 39|8@0+ (1,-40) [-40|215] "℃"  SBCMU
 SG_ SBICU04_Temp06 : 47|8@0+ (1,-40) [-40|215] "℃"  SBCMU
 SG_ SBICU04_Temp07 : 55|8@0+ (1,-40) [-40|215] "℃"  SBCMU
 SG_ SBICU04_Temp08 : 63|8@0+ (1,-40) [-40|215] "℃"  SBCMU

BO_ 2564554532 SBICU04_CellTemp02: 8 SBICU
 SG_ SBICU04_Temp09 : 7|8@0+ (1,-40) [-40|215] "℃"  SBCMU
 SG_ SBICU04_Temp10 : 15|8@0+ (1,-40) [-40|215] "℃"  SBCMU
 SG_ SBICU04_Temp11 : 23|8@0+ (1,-40) [-40|215] "℃"  SBCMU
 SG_ SBICU04_Temp12 : 31|8@0+ (1,-40) [-40|215] "℃"  SBCMU
 SG_ SBICU04_Temp13 : 39|8@0+ (1,-40) [-40|215] "℃"  SBCMU
 SG_ SBICU04_Temp14 : 47|8@0+ (1,-40) [-40|215] "℃"  SBCMU
 SG_ SBICU04_Temp15 : 55|8@0+ (1,-40) [-40|215] "℃"  SBCMU
 SG_ SBICU04_Temp16 : 63|8@0+ (1,-40) [-40|215] "℃"  SBCMU

BO_ 2564620068 SBICU04_CellTemp03: 8 SBICU
 SG_ SBICU04_Temp17 : 7|8@0+ (1,-40) [-40|215] "℃"  SBCMU
 SG_ SBICU04_Temp18 : 15|8@0+ (1,-40) [-40|215] "℃"  SBCMU
 SG_ SBICU04_Temp19 : 23|8@0+ (1,-40) [-40|215] "℃"  SBCMU
 SG_ SBICU04_Temp20 : 31|8@0+ (1,-40) [-40|215] "℃"  SBCMU
 SG_ SBICU04_Temp21 : 39|8@0+ (1,-40) [-40|215] "℃"  SBCMU
 SG_ SBICU04_Temp22 : 47|8@0+ (1,-40) [-40|215] "℃"  SBCMU
 SG_ SBICU04_Temp23 : 55|8@0+ (1,-40) [-40|215] "℃"  SBCMU
 SG_ SBICU04_Temp24 : 63|8@0+ (1,-40) [-40|215] "℃"  SBCMU

BO_ 2564685604 SBICU04_CellTemp04: 8 SBICU
 SG_ SBICU04_Temp25 : 7|8@0+ (1,-40) [-40|215] "℃"  SBCMU
 SG_ SBICU04_Temp26 : 15|8@0+ (1,-40) [-40|215] "℃"  SBCMU
 SG_ SBICU04_Temp27 : 23|8@0+ (1,-40) [-40|215] "℃"  SBCMU
 SG_ SBICU04_Temp28 : 31|8@0+ (1,-40) [-40|215] "℃"  SBCMU
 SG_ SBICU04_Temp29 : 39|8@0+ (1,-40) [-40|215] "℃"  SBCMU
 SG_ SBICU04_Temp30 : 47|8@0+ (1,-40) [-40|215] "℃"  SBCMU
 SG_ SBICU04_Temp31 : 55|8@0+ (1,-40) [-40|215] "℃"  SBCMU
 SG_ SBICU04_Temp32 : 63|8@0+ (1,-40) [-40|215] "℃"  SBCMU

BO_ 2564751140 SBICU04_CellTemp05: 8 SBICU
 SG_ SBICU04_Temp33 : 7|8@0+ (1,-40) [-40|215] "℃"  SBCMU
 SG_ SBICU04_Temp34 : 15|8@0+ (1,-40) [-40|215] "℃"  SBCMU
 SG_ SBICU04_Temp35 : 23|8@0+ (1,-40) [-40|215] "℃"  SBCMU
 SG_ SBICU04_Temp36 : 31|8@0+ (1,-40) [-40|215] "℃"  SBCMU

BO_ 2564947748 SBICU04_SW_Info: 8 SBICU
 SG_ SBICU04_NBCMU_Addr_SW : 7|8@0+ (1,0) [0|255] ""  SBCMU
 SG_ SBICU04_SW01 : 15|8@0+ (1,0) [0|255] ""  SBCMU
 SG_ SBICU04_SW02 : 23|8@0+ (1,0) [0|255] ""  SBCMU
 SG_ SBICU04_SW03 : 31|8@0+ (1,0) [0|255] ""  SBCMU
 SG_ SBICU04_SW04 : 39|8@0+ (1,0) [0|255] ""  SBCMU
 SG_ SBICU04_SW05 : 47|8@0+ (1,0) [0|255] ""  SBCMU
 SG_ SBICU04_SW06 : 55|8@0+ (1,0) [0|255] ""  SBCMU
 SG_ SBICU04_SW07 : 63|8@0+ (1,0) [0|255] ""  SBCMU

BO_ 2565013284 SBICU04_HW_Info: 8 SBICU
 SG_ SBICU04_NBCMU_Addr_HW : 7|8@0+ (1,0) [0|255] ""  SBCMU
 SG_ SBICU04_HW01 : 15|8@0+ (1,0) [0|255] ""  SBCMU
 SG_ SBICU04_HW02 : 23|8@0+ (1,0) [0|255] ""  SBCMU
 SG_ SBICU04_HW03 : 31|8@0+ (1,0) [0|255] ""  SBCMU
 SG_ SBICU04_HW04 : 39|8@0+ (1,0) [0|255] ""  SBCMU
 SG_ SBICU04_HW05 : 47|8@0+ (1,0) [0|255] ""  SBCMU
 SG_ SBICU04_HW06 : 55|8@0+ (1,0) [0|255] ""  SBCMU
 SG_ SBICU04_HW07 : 63|8@0+ (1,0) [0|255] ""  SBCMU

BO_ 2564677412 SBICU04_DiaResponse: 8 SBICU
 SG_ SBICU04_RespData : 7|64@0+ (1,0) [0|1.84467440737096E+019] ""  DAPP

BO_ 2562785061 SBICU05_RunState: 8 SBICU
 SG_ SBICU05_Address : 7|8@0+ (1,0) [0|255] ""  NBCMU,SBCMU
 SG_ SBICU05_TempNum : 23|8@0+ (1,0) [0|255] ""  NBCMU,SBCMU
 SG_ SBICU05_CellTemp_HighWarning : 25|2@0+ (1,0) [0|3] ""  NBCMU,SBCMU
 SG_ SBICU05_AddrInput_State : 32|1@0+ (1,0) [0|1] ""  NBCMU,SBCMU
 SG_ SBICU05_AddrOutput_State : 33|1@0+ (1,0) [0|1] ""  NBCMU,SBCMU
 SG_ SBICU05_SoftVer : 47|8@0+ (1,0) [0|255] ""  NBCMU,SBCMU
 SG_ SBICU05_HardVer : 55|8@0+ (1,0) [0|255] ""  NBCMU,SBCMU
 SG_ SBICU05_RunAlivCoun : 63|8@0+ (1,0) [0|255] ""  NBCMU,SBCMU

BO_ 2562916133 SBICU05_TempExtremeInfo: 8 SBICU
 SG_ SBICU05_CellTempMax : 7|8@0+ (1,-40) [-40|215] "℃"  NBCMU,SBCMU
 SG_ SBICU05_CellTempMin : 15|8@0+ (1,-40) [-40|215] "℃"  NBCMU,SBCMU
 SG_ SBICU05_CellTempAvg : 23|8@0+ (1,-40) [-40|215] "℃"  NBCMU,SBCMU
 SG_ SBICU05_CellTempMaxCode : 31|8@0+ (1,0) [0|255] ""  NBCMU,SBCMU
 SG_ SBICU05_CellTempMinCode : 39|8@0+ (1,0) [0|255] ""  NBCMU,SBCMU
 SG_ SBICU05_SupplyVolt : 40|9@0+ (0.1,0) [0|51.1] "V"  NBCMU,SBCMU

BO_ 2564488997 SBICU05_CellTemp01: 8 SBICU
 SG_ SBICU05_Temp01 : 7|8@0+ (1,-40) [-40|215] "℃"  SBCMU
 SG_ SBICU05_Temp02 : 15|8@0+ (1,-40) [-40|215] "℃"  SBCMU
 SG_ SBICU05_Temp03 : 23|8@0+ (1,-40) [-40|215] "℃"  SBCMU
 SG_ SBICU05_Temp04 : 31|8@0+ (1,-40) [-40|215] "℃"  SBCMU
 SG_ SBICU05_Temp05 : 39|8@0+ (1,-40) [-40|215] "℃"  SBCMU
 SG_ SBICU05_Temp06 : 47|8@0+ (1,-40) [-40|215] "℃"  SBCMU
 SG_ SBICU05_Temp07 : 55|8@0+ (1,-40) [-40|215] "℃"  SBCMU
 SG_ SBICU05_Temp08 : 63|8@0+ (1,-40) [-40|215] "℃"  SBCMU

BO_ 2564554533 SBICU05_CellTemp02: 8 SBICU
 SG_ SBICU05_Temp09 : 7|8@0+ (1,-40) [-40|215] "℃"  SBCMU
 SG_ SBICU05_Temp10 : 15|8@0+ (1,-40) [-40|215] "℃"  SBCMU
 SG_ SBICU05_Temp11 : 23|8@0+ (1,-40) [-40|215] "℃"  SBCMU
 SG_ SBICU05_Temp12 : 31|8@0+ (1,-40) [-40|215] "℃"  SBCMU
 SG_ SBICU05_Temp13 : 39|8@0+ (1,-40) [-40|215] "℃"  SBCMU
 SG_ SBICU05_Temp14 : 47|8@0+ (1,-40) [-40|215] "℃"  SBCMU
 SG_ SBICU05_Temp15 : 55|8@0+ (1,-40) [-40|215] "℃"  SBCMU
 SG_ SBICU05_Temp16 : 63|8@0+ (1,-40) [-40|215] "℃"  SBCMU

BO_ 2564620069 SBICU05_CellTemp03: 8 SBICU
 SG_ SBICU05_Temp17 : 7|8@0+ (1,-40) [-40|215] "℃"  SBCMU
 SG_ SBICU05_Temp18 : 15|8@0+ (1,-40) [-40|215] "℃"  SBCMU
 SG_ SBICU05_Temp19 : 23|8@0+ (1,-40) [-40|215] "℃"  SBCMU
 SG_ SBICU05_Temp20 : 31|8@0+ (1,-40) [-40|215] "℃"  SBCMU
 SG_ SBICU05_Temp21 : 39|8@0+ (1,-40) [-40|215] "℃"  SBCMU
 SG_ SBICU05_Temp22 : 47|8@0+ (1,-40) [-40|215] "℃"  SBCMU
 SG_ SBICU05_Temp23 : 55|8@0+ (1,-40) [-40|215] "℃"  SBCMU
 SG_ SBICU05_Temp24 : 63|8@0+ (1,-40) [-40|215] "℃"  SBCMU

BO_ 2564685605 SBICU05_CellTemp04: 8 SBICU
 SG_ SBICU05_Temp25 : 7|8@0+ (1,-40) [-40|215] "℃"  SBCMU
 SG_ SBICU05_Temp26 : 15|8@0+ (1,-40) [-40|215] "℃"  SBCMU
 SG_ SBICU05_Temp27 : 23|8@0+ (1,-40) [-40|215] "℃"  SBCMU
 SG_ SBICU05_Temp28 : 31|8@0+ (1,-40) [-40|215] "℃"  SBCMU
 SG_ SBICU05_Temp29 : 39|8@0+ (1,-40) [-40|215] "℃"  SBCMU
 SG_ SBICU05_Temp30 : 47|8@0+ (1,-40) [-40|215] "℃"  SBCMU
 SG_ SBICU05_Temp31 : 55|8@0+ (1,-40) [-40|215] "℃"  SBCMU
 SG_ SBICU05_Temp32 : 63|8@0+ (1,-40) [-40|215] "℃"  SBCMU

BO_ 2564751141 SBICU05_CellTemp05: 8 SBICU
 SG_ SBICU05_Temp33 : 7|8@0+ (1,-40) [-40|215] "℃"  SBCMU
 SG_ SBICU05_Temp34 : 15|8@0+ (1,-40) [-40|215] "℃"  SBCMU
 SG_ SBICU05_Temp35 : 23|8@0+ (1,-40) [-40|215] "℃"  SBCMU
 SG_ SBICU05_Temp36 : 31|8@0+ (1,-40) [-40|215] "℃"  SBCMU

BO_ 2564947749 SBICU05_SW_Info: 8 SBICU
 SG_ SBICU05_NBCMU_Addr_SW : 7|8@0+ (1,0) [0|255] ""  SBCMU
 SG_ SBICU05_SW01 : 15|8@0+ (1,0) [0|255] ""  SBCMU
 SG_ SBICU05_SW02 : 23|8@0+ (1,0) [0|255] ""  SBCMU
 SG_ SBICU05_SW03 : 31|8@0+ (1,0) [0|255] ""  SBCMU
 SG_ SBICU05_SW04 : 39|8@0+ (1,0) [0|255] ""  SBCMU
 SG_ SBICU05_SW05 : 47|8@0+ (1,0) [0|255] ""  SBCMU
 SG_ SBICU05_SW06 : 55|8@0+ (1,0) [0|255] ""  SBCMU
 SG_ SBICU05_SW07 : 63|8@0+ (1,0) [0|255] ""  SBCMU

BO_ 2565013285 SBICU05_HW_Info: 8 SBICU
 SG_ SBICU05_NBCMU_Addr_HW : 7|8@0+ (1,0) [0|255] ""  SBCMU
 SG_ SBICU05_HW01 : 15|8@0+ (1,0) [0|255] ""  SBCMU
 SG_ SBICU05_HW02 : 23|8@0+ (1,0) [0|255] ""  SBCMU
 SG_ SBICU05_HW03 : 31|8@0+ (1,0) [0|255] ""  SBCMU
 SG_ SBICU05_HW04 : 39|8@0+ (1,0) [0|255] ""  SBCMU
 SG_ SBICU05_HW05 : 47|8@0+ (1,0) [0|255] ""  SBCMU
 SG_ SBICU05_HW06 : 55|8@0+ (1,0) [0|255] ""  SBCMU
 SG_ SBICU05_HW07 : 63|8@0+ (1,0) [0|255] ""  SBCMU

BO_ 2564677413 SBICU05_DiaResponse: 8 SBICU
 SG_ SBICU05_RespData : 7|64@0+ (1,0) [0|1.84467440737096E+019] ""  DAPP

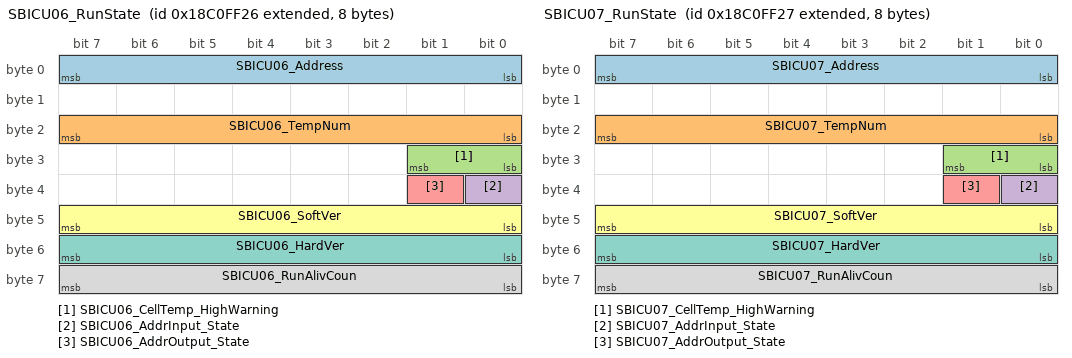
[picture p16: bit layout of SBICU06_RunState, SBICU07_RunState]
BO_ 2562785062 SBICU06_RunState: 8 SBICU
 SG_ SBICU06_Address : 7|8@0+ (1,0) [0|255] ""  NBCMU,SBCMU
 SG_ SBICU06_TempNum : 23|8@0+ (1,0) [0|255] ""  NBCMU,SBCMU
 SG_ SBICU06_CellTemp_HighWarning : 25|2@0+ (1,0) [0|3] ""  NBCMU,SBCMU
 SG_ SBICU06_AddrInput_State : 32|1@0+ (1,0) [0|1] ""  NBCMU,SBCMU
 SG_ SBICU06_AddrOutput_State : 33|1@0+ (1,0) [0|1] ""  NBCMU,SBCMU
 SG_ SBICU06_SoftVer : 47|8@0+ (1,0) [0|255] ""  NBCMU,SBCMU
 SG_ SBICU06_HardVer : 55|8@0+ (1,0) [0|255] ""  NBCMU,SBCMU
 SG_ SBICU06_RunAlivCoun : 63|8@0+ (1,0) [0|255] ""  NBCMU,SBCMU

BO_ 2562916134 SBICU06_TempExtremeInfo: 8 SBICU
 SG_ SBICU06_CellTempMax : 7|8@0+ (1,-40) [-40|215] "℃"  NBCMU,SBCMU
 SG_ SBICU06_CellTempMin : 15|8@0+ (1,-40) [-40|215] "℃"  NBCMU,SBCMU
 SG_ SBICU06_CellTempAvg : 23|8@0+ (1,-40) [-40|215] "℃"  NBCMU,SBCMU
 SG_ SBICU06_CellTempMaxCode : 31|8@0+ (1,0) [0|255] ""  NBCMU,SBCMU
 SG_ SBICU06_CellTempMinCode : 39|8@0+ (1,0) [0|255] ""  NBCMU,SBCMU
 SG_ SBICU06_SupplyVolt : 40|9@0+ (0.1,0) [0|51.1] "V"  NBCMU,SBCMU

BO_ 2564488998 SBICU06_CellTemp01: 8 SBICU
 SG_ SBICU06_Temp01 : 7|8@0+ (1,-40) [-40|215] "℃"  SBCMU
 SG_ SBICU06_Temp02 : 15|8@0+ (1,-40) [-40|215] "℃"  SBCMU
 SG_ SBICU06_Temp03 : 23|8@0+ (1,-40) [-40|215] "℃"  SBCMU
 SG_ SBICU06_Temp04 : 31|8@0+ (1,-40) [-40|215] "℃"  SBCMU
 SG_ SBICU06_Temp05 : 39|8@0+ (1,-40) [-40|215] "℃"  SBCMU
 SG_ SBICU06_Temp06 : 47|8@0+ (1,-40) [-40|215] "℃"  SBCMU
 SG_ SBICU06_Temp07 : 55|8@0+ (1,-40) [-40|215] "℃"  SBCMU
 SG_ SBICU06_Temp08 : 63|8@0+ (1,-40) [-40|215] "℃"  SBCMU

BO_ 2564554534 SBICU06_CellTemp02: 8 SBICU
 SG_ SBICU06_Temp09 : 7|8@0+ (1,-40) [-40|215] "℃"  SBCMU
 SG_ SBICU06_Temp10 : 15|8@0+ (1,-40) [-40|215] "℃"  SBCMU
 SG_ SBICU06_Temp11 : 23|8@0+ (1,-40) [-40|215] "℃"  SBCMU
 SG_ SBICU06_Temp12 : 31|8@0+ (1,-40) [-40|215] "℃"  SBCMU
 SG_ SBICU06_Temp13 : 39|8@0+ (1,-40) [-40|215] "℃"  SBCMU
 SG_ SBICU06_Temp14 : 47|8@0+ (1,-40) [-40|215] "℃"  SBCMU
 SG_ SBICU06_Temp15 : 55|8@0+ (1,-40) [-40|215] "℃"  SBCMU
 SG_ SBICU06_Temp16 : 63|8@0+ (1,-40) [-40|215] "℃"  SBCMU

BO_ 2564620070 SBICU06_CellTemp03: 8 SBICU
 SG_ SBICU06_Temp17 : 7|8@0+ (1,-40) [-40|215] "℃"  SBCMU
 SG_ SBICU06_Temp18 : 15|8@0+ (1,-40) [-40|215] "℃"  SBCMU
 SG_ SBICU06_Temp19 : 23|8@0+ (1,-40) [-40|215] "℃"  SBCMU
 SG_ SBICU06_Temp20 : 31|8@0+ (1,-40) [-40|215] "℃"  SBCMU
 SG_ SBICU06_Temp21 : 39|8@0+ (1,-40) [-40|215] "℃"  SBCMU
 SG_ SBICU06_Temp22 : 47|8@0+ (1,-40) [-40|215] "℃"  SBCMU
 SG_ SBICU06_Temp23 : 55|8@0+ (1,-40) [-40|215] "℃"  SBCMU
 SG_ SBICU06_Temp24 : 63|8@0+ (1,-40) [-40|215] "℃"  SBCMU

BO_ 2564685606 SBICU06_CellTemp04: 8 SBICU
 SG_ SBICU06_Temp25 : 7|8@0+ (1,-40) [-40|215] "℃"  SBCMU
 SG_ SBICU06_Temp26 : 15|8@0+ (1,-40) [-40|215] "℃"  SBCMU
 SG_ SBICU06_Temp27 : 23|8@0+ (1,-40) [-40|215] "℃"  SBCMU
 SG_ SBICU06_Temp28 : 31|8@0+ (1,-40) [-40|215] "℃"  SBCMU
 SG_ SBICU06_Temp29 : 39|8@0+ (1,-40) [-40|215] "℃"  SBCMU
 SG_ SBICU06_Temp30 : 47|8@0+ (1,-40) [-40|215] "℃"  SBCMU
 SG_ SBICU06_Temp31 : 55|8@0+ (1,-40) [-40|215] "℃"  SBCMU
 SG_ SBICU06_Temp32 : 63|8@0+ (1,-40) [-40|215] "℃"  SBCMU

BO_ 2564751142 SBICU06_CellTemp05: 8 SBICU
 SG_ SBICU06_Temp33 : 7|8@0+ (1,-40) [-40|215] "℃"  SBCMU
 SG_ SBICU06_Temp34 : 15|8@0+ (1,-40) [-40|215] "℃"  SBCMU
 SG_ SBICU06_Temp35 : 23|8@0+ (1,-40) [-40|215] "℃"  SBCMU
 SG_ SBICU06_Temp36 : 31|8@0+ (1,-40) [-40|215] "℃"  SBCMU

BO_ 2564947750 SBICU06_SW_Info: 8 SBICU
 SG_ SBICU06_NBCMU_Addr_SW : 7|8@0+ (1,0) [0|255] ""  SBCMU
 SG_ SBICU06_SW01 : 15|8@0+ (1,0) [0|255] ""  SBCMU
 SG_ SBICU06_SW02 : 23|8@0+ (1,0) [0|255] ""  SBCMU
 SG_ SBICU06_SW03 : 31|8@0+ (1,0) [0|255] ""  SBCMU
 SG_ SBICU06_SW04 : 39|8@0+ (1,0) [0|255] ""  SBCMU
 SG_ SBICU06_SW05 : 47|8@0+ (1,0) [0|255] ""  SBCMU
 SG_ SBICU06_SW06 : 55|8@0+ (1,0) [0|255] ""  SBCMU
 SG_ SBICU06_SW07 : 63|8@0+ (1,0) [0|255] ""  SBCMU

BO_ 2565013286 SBICU06_HW_Info: 8 SBICU
 SG_ SBICU06_NBCMU_Addr_HW : 7|8@0+ (1,0) [0|255] ""  SBCMU
 SG_ SBICU06_HW01 : 15|8@0+ (1,0) [0|255] ""  SBCMU
 SG_ SBICU06_HW02 : 23|8@0+ (1,0) [0|255] ""  SBCMU
 SG_ SBICU06_HW03 : 31|8@0+ (1,0) [0|255] ""  SBCMU
 SG_ SBICU06_HW04 : 39|8@0+ (1,0) [0|255] ""  SBCMU
 SG_ SBICU06_HW05 : 47|8@0+ (1,0) [0|255] ""  SBCMU
 SG_ SBICU06_HW06 : 55|8@0+ (1,0) [0|255] ""  SBCMU
 SG_ SBICU06_HW07 : 63|8@0+ (1,0) [0|255] ""  SBCMU

BO_ 2564677414 SBICU06_DiaResponse: 8 SBICU
 SG_ SBICU06_RespData : 7|64@0+ (1,0) [0|1.84467440737096E+019] ""  DAPP

BO_ 2562785063 SBICU07_RunState: 8 SBICU
 SG_ SBICU07_Address : 7|8@0+ (1,0) [0|255] ""  NBCMU,SBCMU
 SG_ SBICU07_TempNum : 23|8@0+ (1,0) [0|255] ""  NBCMU,SBCMU
 SG_ SBICU07_CellTemp_HighWarning : 25|2@0+ (1,0) [0|3] ""  NBCMU,SBCMU
 SG_ SBICU07_AddrInput_State : 32|1@0+ (1,0) [0|1] ""  NBCMU,SBCMU
 SG_ SBICU07_AddrOutput_State : 33|1@0+ (1,0) [0|1] ""  NBCMU,SBCMU
 SG_ SBICU07_SoftVer : 47|8@0+ (1,0) [0|255] ""  NBCMU,SBCMU
 SG_ SBICU07_HardVer : 55|8@0+ (1,0) [0|255] ""  NBCMU,SBCMU
 SG_ SBICU07_RunAlivCoun : 63|8@0+ (1,0) [0|255] ""  NBCMU,SBCMU

BO_ 2562916135 SBICU07_TempExtremeInfo: 8 SBICU
 SG_ SBICU07_CellTempMax : 7|8@0+ (1,-40) [-40|215] "℃"  NBCMU,SBCMU
 SG_ SBICU07_CellTempMin : 15|8@0+ (1,-40) [-40|215] "℃"  NBCMU,SBCMU
 SG_ SBICU07_CellTempAvg : 23|8@0+ (1,-40) [-40|215] "℃"  NBCMU,SBCMU
 SG_ SBICU07_CellTempMaxCode : 31|8@0+ (1,0) [0|255] ""  NBCMU,SBCMU
 SG_ SBICU07_CellTempMinCode : 39|8@0+ (1,0) [0|255] ""  NBCMU,SBCMU
 SG_ SBICU07_SupplyVolt : 40|9@0+ (0.1,0) [0|51.1] "V"  NBCMU,SBCMU

BO_ 2564488999 SBICU07_CellTemp01: 8 SBICU
 SG_ SBICU07_Temp01 : 7|8@0+ (1,-40) [-40|215] "℃"  SBCMU
 SG_ SBICU07_Temp02 : 15|8@0+ (1,-40) [-40|215] "℃"  SBCMU
 SG_ SBICU07_Temp03 : 23|8@0+ (1,-40) [-40|215] "℃"  SBCMU
 SG_ SBICU07_Temp04 : 31|8@0+ (1,-40) [-40|215] "℃"  SBCMU
 SG_ SBICU07_Temp05 : 39|8@0+ (1,-40) [-40|215] "℃"  SBCMU
 SG_ SBICU07_Temp06 : 47|8@0+ (1,-40) [-40|215] "℃"  SBCMU
 SG_ SBICU07_Temp07 : 55|8@0+ (1,-40) [-40|215] "℃"  SBCMU
 SG_ SBICU07_Temp08 : 63|8@0+ (1,-40) [-40|215] "℃"  SBCMU

BO_ 2564554535 SBICU07_CellTemp02: 8 SBICU
 SG_ SBICU07_Temp09 : 7|8@0+ (1,-40) [-40|215] "℃"  SBCMU
 SG_ SBICU07_Temp10 : 15|8@0+ (1,-40) [-40|215] "℃"  SBCMU
 SG_ SBICU07_Temp11 : 23|8@0+ (1,-40) [-40|215] "℃"  SBCMU
 SG_ SBICU07_Temp12 : 31|8@0+ (1,-40) [-40|215] "℃"  SBCMU
 SG_ SBICU07_Temp13 : 39|8@0+ (1,-40) [-40|215] "℃"  SBCMU
 SG_ SBICU07_Temp14 : 47|8@0+ (1,-40) [-40|215] "℃"  SBCMU
 SG_ SBICU07_Temp15 : 55|8@0+ (1,-40) [-40|215] "℃"  SBCMU
 SG_ SBICU07_Temp16 : 63|8@0+ (1,-40) [-40|215] "℃"  SBCMU

BO_ 2564620071 SBICU07_CellTemp03: 8 SBICU
 SG_ SBICU07_Temp17 : 7|8@0+ (1,-40) [-40|215] "℃"  SBCMU
 SG_ SBICU07_Temp18 : 15|8@0+ (1,-40) [-40|215] "℃"  SBCMU
 SG_ SBICU07_Temp19 : 23|8@0+ (1,-40) [-40|215] "℃"  SBCMU
 SG_ SBICU07_Temp20 : 31|8@0+ (1,-40) [-40|215] "℃"  SBCMU
 SG_ SBICU07_Temp21 : 39|8@0+ (1,-40) [-40|215] "℃"  SBCMU
 SG_ SBICU07_Temp22 : 47|8@0+ (1,-40) [-40|215] "℃"  SBCMU
 SG_ SBICU07_Temp23 : 55|8@0+ (1,-40) [-40|215] "℃"  SBCMU
 SG_ SBICU07_Temp24 : 63|8@0+ (1,-40) [-40|215] "℃"  SBCMU

BO_ 2564685607 SBICU07_CellTemp04: 8 SBICU
 SG_ SBICU07_Temp25 : 7|8@0+ (1,-40) [-40|215] "℃"  SBCMU
 SG_ SBICU07_Temp26 : 15|8@0+ (1,-40) [-40|215] "℃"  SBCMU
 SG_ SBICU07_Temp27 : 23|8@0+ (1,-40) [-40|215] "℃"  SBCMU
 SG_ SBICU07_Temp28 : 31|8@0+ (1,-40) [-40|215] "℃"  SBCMU
 SG_ SBICU07_Temp29 : 39|8@0+ (1,-40) [-40|215] "℃"  SBCMU
 SG_ SBICU07_Temp30 : 47|8@0+ (1,-40) [-40|215] "℃"  SBCMU
 SG_ SBICU07_Temp31 : 55|8@0+ (1,-40) [-40|215] "℃"  SBCMU
 SG_ SBICU07_Temp32 : 63|8@0+ (1,-40) [-40|215] "℃"  SBCMU

BO_ 2564751143 SBICU07_CellTemp05: 8 SBICU
 SG_ SBICU07_Temp33 : 7|8@0+ (1,-40) [-40|215] "℃"  SBCMU
 SG_ SBICU07_Temp34 : 15|8@0+ (1,-40) [-40|215] "℃"  SBCMU
 SG_ SBICU07_Temp35 : 23|8@0+ (1,-40) [-40|215] "℃"  SBCMU
 SG_ SBICU07_Temp36 : 31|8@0+ (1,-40) [-40|215] "℃"  SBCMU

BO_ 2564947751 SBICU07_SW_Info: 8 SBICU
 SG_ SBICU07_NBCMU_Addr_SW : 7|8@0+ (1,0) [0|255] ""  SBCMU
 SG_ SBICU07_SW01 : 15|8@0+ (1,0) [0|255] ""  SBCMU
 SG_ SBICU07_SW02 : 23|8@0+ (1,0) [0|255] ""  SBCMU
 SG_ SBICU07_SW03 : 31|8@0+ (1,0) [0|255] ""  SBCMU
 SG_ SBICU07_SW04 : 39|8@0+ (1,0) [0|255] ""  SBCMU
 SG_ SBICU07_SW05 : 47|8@0+ (1,0) [0|255] ""  SBCMU
 SG_ SBICU07_SW06 : 55|8@0+ (1,0) [0|255] ""  SBCMU
 SG_ SBICU07_SW07 : 63|8@0+ (1,0) [0|255] ""  SBCMU

BO_ 2565013287 SBICU07_HW_Info: 8 SBICU
 SG_ SBICU07_NBCMU_Addr_HW : 7|8@0+ (1,0) [0|255] ""  SBCMU
 SG_ SBICU07_HW01 : 15|8@0+ (1,0) [0|255] ""  SBCMU
 SG_ SBICU07_HW02 : 23|8@0+ (1,0) [0|255] ""  SBCMU
 SG_ SBICU07_HW03 : 31|8@0+ (1,0) [0|255] ""  SBCMU
 SG_ SBICU07_HW04 : 39|8@0+ (1,0) [0|255] ""  SBCMU
 SG_ SBICU07_HW05 : 47|8@0+ (1,0) [0|255] ""  SBCMU
 SG_ SBICU07_HW06 : 55|8@0+ (1,0) [0|255] ""  SBCMU
 SG_ SBICU07_HW07 : 63|8@0+ (1,0) [0|255] ""  SBCMU

BO_ 2564677415 SBICU07_DiaResponse: 8 SBICU
 SG_ SBICU07_RespData : 7|64@0+ (1,0) [0|1.84467440737096E+019] ""  DAPP

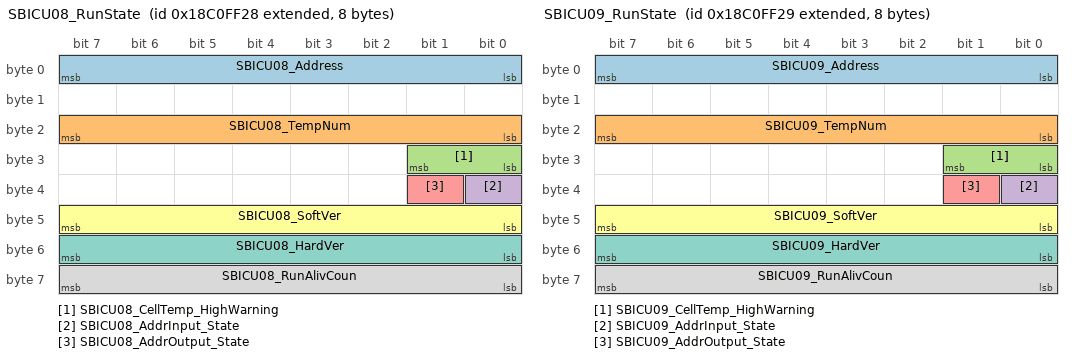
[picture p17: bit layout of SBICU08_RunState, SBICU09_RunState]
BO_ 2562785064 SBICU08_RunState: 8 SBICU
 SG_ SBICU08_Address : 7|8@0+ (1,0) [0|255] ""  NBCMU,SBCMU
 SG_ SBICU08_TempNum : 23|8@0+ (1,0) [0|255] ""  NBCMU,SBCMU
 SG_ SBICU08_CellTemp_HighWarning : 25|2@0+ (1,0) [0|3] ""  NBCMU,SBCMU
 SG_ SBICU08_AddrInput_State : 32|1@0+ (1,0) [0|1] ""  NBCMU,SBCMU
 SG_ SBICU08_AddrOutput_State : 33|1@0+ (1,0) [0|1] ""  NBCMU,SBCMU
 SG_ SBICU08_SoftVer : 47|8@0+ (1,0) [0|255] ""  NBCMU,SBCMU
 SG_ SBICU08_HardVer : 55|8@0+ (1,0) [0|255] ""  NBCMU,SBCMU
 SG_ SBICU08_RunAlivCoun : 63|8@0+ (1,0) [0|255] ""  NBCMU,SBCMU

BO_ 2562916136 SBICU08_TempExtremeInfo: 8 SBICU
 SG_ SBICU08_CellTempMax : 7|8@0+ (1,-40) [-40|215] "℃"  NBCMU,SBCMU
 SG_ SBICU08_CellTempMin : 15|8@0+ (1,-40) [-40|215] "℃"  NBCMU,SBCMU
 SG_ SBICU08_CellTempAvg : 23|8@0+ (1,-40) [-40|215] "℃"  NBCMU,SBCMU
 SG_ SBICU08_CellTempMaxCode : 31|8@0+ (1,0) [0|255] ""  NBCMU,SBCMU
 SG_ SBICU08_CellTempMinCode : 39|8@0+ (1,0) [0|255] ""  NBCMU,SBCMU
 SG_ SBICU08_SupplyVolt : 40|9@0+ (0.1,0) [0|51.1] "V"  NBCMU,SBCMU

BO_ 2564489000 SBICU08_CellTemp01: 8 SBICU
 SG_ SBICU08_Temp01 : 7|8@0+ (1,-40) [-40|215] "℃"  SBCMU
 SG_ SBICU08_Temp02 : 15|8@0+ (1,-40) [-40|215] "℃"  SBCMU
 SG_ SBICU08_Temp03 : 23|8@0+ (1,-40) [-40|215] "℃"  SBCMU
 SG_ SBICU08_Temp04 : 31|8@0+ (1,-40) [-40|215] "℃"  SBCMU
 SG_ SBICU08_Temp05 : 39|8@0+ (1,-40) [-40|215] "℃"  SBCMU
 SG_ SBICU08_Temp06 : 47|8@0+ (1,-40) [-40|215] "℃"  SBCMU
 SG_ SBICU08_Temp07 : 55|8@0+ (1,-40) [-40|215] "℃"  SBCMU
 SG_ SBICU08_Temp08 : 63|8@0+ (1,-40) [-40|215] "℃"  SBCMU

BO_ 2564554536 SBICU08_CellTemp02: 8 SBICU
 SG_ SBICU08_Temp09 : 7|8@0+ (1,-40) [-40|215] "℃"  SBCMU
 SG_ SBICU08_Temp10 : 15|8@0+ (1,-40) [-40|215] "℃"  SBCMU
 SG_ SBICU08_Temp11 : 23|8@0+ (1,-40) [-40|215] "℃"  SBCMU
 SG_ SBICU08_Temp12 : 31|8@0+ (1,-40) [-40|215] "℃"  SBCMU
 SG_ SBICU08_Temp13 : 39|8@0+ (1,-40) [-40|215] "℃"  SBCMU
 SG_ SBICU08_Temp14 : 47|8@0+ (1,-40) [-40|215] "℃"  SBCMU
 SG_ SBICU08_Temp15 : 55|8@0+ (1,-40) [-40|215] "℃"  SBCMU
 SG_ SBICU08_Temp16 : 63|8@0+ (1,-40) [-40|215] "℃"  SBCMU

BO_ 2564620072 SBICU08_CellTemp03: 8 SBICU
 SG_ SBICU08_Temp17 : 7|8@0+ (1,-40) [-40|215] "℃"  SBCMU
 SG_ SBICU08_Temp18 : 15|8@0+ (1,-40) [-40|215] "℃"  SBCMU
 SG_ SBICU08_Temp19 : 23|8@0+ (1,-40) [-40|215] "℃"  SBCMU
 SG_ SBICU08_Temp20 : 31|8@0+ (1,-40) [-40|215] "℃"  SBCMU
 SG_ SBICU08_Temp21 : 39|8@0+ (1,-40) [-40|215] "℃"  SBCMU
 SG_ SBICU08_Temp22 : 47|8@0+ (1,-40) [-40|215] "℃"  SBCMU
 SG_ SBICU08_Temp23 : 55|8@0+ (1,-40) [-40|215] "℃"  SBCMU
 SG_ SBICU08_Temp24 : 63|8@0+ (1,-40) [-40|215] "℃"  SBCMU

BO_ 2564685608 SBICU08_CellTemp04: 8 SBICU
 SG_ SBICU08_Temp25 : 7|8@0+ (1,-40) [-40|215] "℃"  SBCMU
 SG_ SBICU08_Temp26 : 15|8@0+ (1,-40) [-40|215] "℃"  SBCMU
 SG_ SBICU08_Temp27 : 23|8@0+ (1,-40) [-40|215] "℃"  SBCMU
 SG_ SBICU08_Temp28 : 31|8@0+ (1,-40) [-40|215] "℃"  SBCMU
 SG_ SBICU08_Temp29 : 39|8@0+ (1,-40) [-40|215] "℃"  SBCMU
 SG_ SBICU08_Temp30 : 47|8@0+ (1,-40) [-40|215] "℃"  SBCMU
 SG_ SBICU08_Temp31 : 55|8@0+ (1,-40) [-40|215] "℃"  SBCMU
 SG_ SBICU08_Temp32 : 63|8@0+ (1,-40) [-40|215] "℃"  SBCMU

BO_ 2564751144 SBICU08_CellTemp05: 8 SBICU
 SG_ SBICU08_Temp33 : 7|8@0+ (1,-40) [-40|215] "℃"  SBCMU
 SG_ SBICU08_Temp34 : 15|8@0+ (1,-40) [-40|215] "℃"  SBCMU
 SG_ SBICU08_Temp35 : 23|8@0+ (1,-40) [-40|215] "℃"  SBCMU
 SG_ SBICU08_Temp36 : 31|8@0+ (1,-40) [-40|215] "℃"  SBCMU

BO_ 2564947752 SBICU08_SW_Info: 8 SBICU
 SG_ SBICU08_NBCMU_Addr_SW : 7|8@0+ (1,0) [0|255] ""  SBCMU
 SG_ SBICU08_SW01 : 15|8@0+ (1,0) [0|255] ""  SBCMU
 SG_ SBICU08_SW02 : 23|8@0+ (1,0) [0|255] ""  SBCMU
 SG_ SBICU08_SW03 : 31|8@0+ (1,0) [0|255] ""  SBCMU
 SG_ SBICU08_SW04 : 39|8@0+ (1,0) [0|255] ""  SBCMU
 SG_ SBICU08_SW05 : 47|8@0+ (1,0) [0|255] ""  SBCMU
 SG_ SBICU08_SW06 : 55|8@0+ (1,0) [0|255] ""  SBCMU
 SG_ SBICU08_SW07 : 63|8@0+ (1,0) [0|255] ""  SBCMU

BO_ 2565013288 SBICU08_HW_Info: 8 SBICU
 SG_ SBICU08_NBCMU_Addr_HW : 7|8@0+ (1,0) [0|255] ""  SBCMU
 SG_ SBICU08_HW01 : 15|8@0+ (1,0) [0|255] ""  SBCMU
 SG_ SBICU08_HW02 : 23|8@0+ (1,0) [0|255] ""  SBCMU
 SG_ SBICU08_HW03 : 31|8@0+ (1,0) [0|255] ""  SBCMU
 SG_ SBICU08_HW04 : 39|8@0+ (1,0) [0|255] ""  SBCMU
 SG_ SBICU08_HW05 : 47|8@0+ (1,0) [0|255] ""  SBCMU
 SG_ SBICU08_HW06 : 55|8@0+ (1,0) [0|255] ""  SBCMU
 SG_ SBICU08_HW07 : 63|8@0+ (1,0) [0|255] ""  SBCMU

BO_ 2564677416 SBICU08_DiaResponse: 8 SBICU
 SG_ SBICU08_RespData : 7|64@0+ (1,0) [0|1.84467440737096E+019] ""  DAPP

BO_ 2562785065 SBICU09_RunState: 8 SBICU
 SG_ SBICU09_Address : 7|8@0+ (1,0) [0|255] ""  NBCMU,SBCMU
 SG_ SBICU09_TempNum : 23|8@0+ (1,0) [0|255] ""  NBCMU,SBCMU
 SG_ SBICU09_CellTemp_HighWarning : 25|2@0+ (1,0) [0|3] ""  NBCMU,SBCMU
 SG_ SBICU09_AddrInput_State : 32|1@0+ (1,0) [0|1] ""  NBCMU,SBCMU
 SG_ SBICU09_AddrOutput_State : 33|1@0+ (1,0) [0|1] ""  NBCMU,SBCMU
 SG_ SBICU09_SoftVer : 47|8@0+ (1,0) [0|255] ""  NBCMU,SBCMU
 SG_ SBICU09_HardVer : 55|8@0+ (1,0) [0|255] ""  NBCMU,SBCMU
 SG_ SBICU09_RunAlivCoun : 63|8@0+ (1,0) [0|255] ""  NBCMU,SBCMU

BO_ 2562916137 SBICU09_TempExtremeInfo: 8 SBICU
 SG_ SBICU09_CellTempMax : 7|8@0+ (1,-40) [-40|215] "℃"  NBCMU,SBCMU
 SG_ SBICU09_CellTempMin : 15|8@0+ (1,-40) [-40|215] "℃"  NBCMU,SBCMU
 SG_ SBICU09_CellTempAvg : 23|8@0+ (1,-40) [-40|215] "℃"  NBCMU,SBCMU
 SG_ SBICU09_CellTempMaxCode : 31|8@0+ (1,0) [0|255] ""  NBCMU,SBCMU
 SG_ SBICU09_CellTempMinCode : 39|8@0+ (1,0) [0|255] ""  NBCMU,SBCMU
 SG_ SBICU09_SupplyVolt : 40|9@0+ (0.1,0) [0|51.1] "V"  NBCMU,SBCMU

BO_ 2564489001 SBICU09_CellTemp01: 8 SBICU
 SG_ SBICU09_Temp01 : 7|8@0+ (1,-40) [-40|215] "℃"  SBCMU
 SG_ SBICU09_Temp02 : 15|8@0+ (1,-40) [-40|215] "℃"  SBCMU
 SG_ SBICU09_Temp03 : 23|8@0+ (1,-40) [-40|215] "℃"  SBCMU
 SG_ SBICU09_Temp04 : 31|8@0+ (1,-40) [-40|215] "℃"  SBCMU
 SG_ SBICU09_Temp05 : 39|8@0+ (1,-40) [-40|215] "℃"  SBCMU
 SG_ SBICU09_Temp06 : 47|8@0+ (1,-40) [-40|215] "℃"  SBCMU
 SG_ SBICU09_Temp07 : 55|8@0+ (1,-40) [-40|215] "℃"  SBCMU
 SG_ SBICU09_Temp08 : 63|8@0+ (1,-40) [-40|215] "℃"  SBCMU

BO_ 2564554537 SBICU09_CellTemp02: 8 SBICU
 SG_ SBICU09_Temp09 : 7|8@0+ (1,-40) [-40|215] "℃"  SBCMU
 SG_ SBICU09_Temp10 : 15|8@0+ (1,-40) [-40|215] "℃"  SBCMU
 SG_ SBICU09_Temp11 : 23|8@0+ (1,-40) [-40|215] "℃"  SBCMU
 SG_ SBICU09_Temp12 : 31|8@0+ (1,-40) [-40|215] "℃"  SBCMU
 SG_ SBICU09_Temp13 : 39|8@0+ (1,-40) [-40|215] "℃"  SBCMU
 SG_ SBICU09_Temp14 : 47|8@0+ (1,-40) [-40|215] "℃"  SBCMU
 SG_ SBICU09_Temp15 : 55|8@0+ (1,-40) [-40|215] "℃"  SBCMU
 SG_ SBICU09_Temp16 : 63|8@0+ (1,-40) [-40|215] "℃"  SBCMU

BO_ 2564620073 SBICU09_CellTemp03: 8 SBICU
 SG_ SBICU09_Temp17 : 7|8@0+ (1,-40) [-40|215] "℃"  SBCMU
 SG_ SBICU09_Temp18 : 15|8@0+ (1,-40) [-40|215] "℃"  SBCMU
 SG_ SBICU09_Temp19 : 23|8@0+ (1,-40) [-40|215] "℃"  SBCMU
 SG_ SBICU09_Temp20 : 31|8@0+ (1,-40) [-40|215] "℃"  SBCMU
 SG_ SBICU09_Temp21 : 39|8@0+ (1,-40) [-40|215] "℃"  SBCMU
 SG_ SBICU09_Temp22 : 47|8@0+ (1,-40) [-40|215] "℃"  SBCMU
 SG_ SBICU09_Temp23 : 55|8@0+ (1,-40) [-40|215] "℃"  SBCMU
 SG_ SBICU09_Temp24 : 63|8@0+ (1,-40) [-40|215] "℃"  SBCMU

BO_ 2564685609 SBICU09_CellTemp04: 8 SBICU
 SG_ SBICU09_Temp25 : 7|8@0+ (1,-40) [-40|215] "℃"  SBCMU
 SG_ SBICU09_Temp26 : 15|8@0+ (1,-40) [-40|215] "℃"  SBCMU
 SG_ SBICU09_Temp27 : 23|8@0+ (1,-40) [-40|215] "℃"  SBCMU
 SG_ SBICU09_Temp28 : 31|8@0+ (1,-40) [-40|215] "℃"  SBCMU
 SG_ SBICU09_Temp29 : 39|8@0+ (1,-40) [-40|215] "℃"  SBCMU
 SG_ SBICU09_Temp30 : 47|8@0+ (1,-40) [-40|215] "℃"  SBCMU
 SG_ SBICU09_Temp31 : 55|8@0+ (1,-40) [-40|215] "℃"  SBCMU
 SG_ SBICU09_Temp32 : 63|8@0+ (1,-40) [-40|215] "℃"  SBCMU

BO_ 2564751145 SBICU09_CellTemp05: 8 SBICU
 SG_ SBICU09_Temp33 : 7|8@0+ (1,-40) [-40|215] "℃"  SBCMU
 SG_ SBICU09_Temp34 : 15|8@0+ (1,-40) [-40|215] "℃"  SBCMU
 SG_ SBICU09_Temp35 : 23|8@0+ (1,-40) [-40|215] "℃"  SBCMU
 SG_ SBICU09_Temp36 : 31|8@0+ (1,-40) [-40|215] "℃"  SBCMU

BO_ 2564947753 SBICU09_SW_Info: 8 SBICU
 SG_ SBICU09_NBCMU_Addr_SW : 7|8@0+ (1,0) [0|255] ""  SBCMU
 SG_ SBICU09_SW01 : 15|8@0+ (1,0) [0|255] ""  SBCMU
 SG_ SBICU09_SW02 : 23|8@0+ (1,0) [0|255] ""  SBCMU
 SG_ SBICU09_SW03 : 31|8@0+ (1,0) [0|255] ""  SBCMU
 SG_ SBICU09_SW04 : 39|8@0+ (1,0) [0|255] ""  SBCMU
 SG_ SBICU09_SW05 : 47|8@0+ (1,0) [0|255] ""  SBCMU
 SG_ SBICU09_SW06 : 55|8@0+ (1,0) [0|255] ""  SBCMU
 SG_ SBICU09_SW07 : 63|8@0+ (1,0) [0|255] ""  SBCMU

BO_ 2565013289 SBICU09_HW_Info: 8 SBICU
 SG_ SBICU09_NBCMU_Addr_HW : 7|8@0+ (1,0) [0|255] ""  SBCMU
 SG_ SBICU09_HW01 : 15|8@0+ (1,0) [0|255] ""  SBCMU
 SG_ SBICU09_HW02 : 23|8@0+ (1,0) [0|255] ""  SBCMU
 SG_ SBICU09_HW03 : 31|8@0+ (1,0) [0|255] ""  SBCMU
 SG_ SBICU09_HW04 : 39|8@0+ (1,0) [0|255] ""  SBCMU
 SG_ SBICU09_HW05 : 47|8@0+ (1,0) [0|255] ""  SBCMU
 SG_ SBICU09_HW06 : 55|8@0+ (1,0) [0|255] ""  SBCMU
 SG_ SBICU09_HW07 : 63|8@0+ (1,0) [0|255] ""  SBCMU

BO_ 2564677417 SBICU09_DiaResponse: 8 SBICU
 SG_ SBICU09_RespData : 7|64@0+ (1,0) [0|1.84467440737096E+019] ""  DAPP

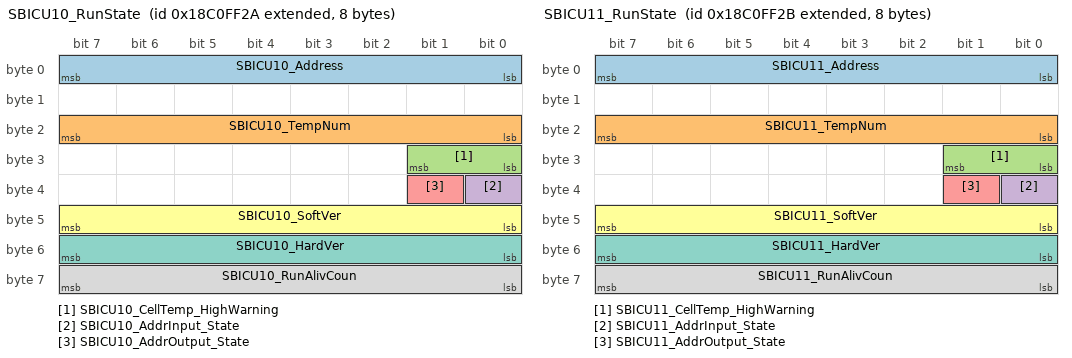
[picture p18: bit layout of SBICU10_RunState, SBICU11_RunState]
BO_ 2562785066 SBICU10_RunState: 8 SBICU
 SG_ SBICU10_Address : 7|8@0+ (1,0) [0|255] ""  NBCMU
 SG_ SBICU10_TempNum : 23|8@0+ (1,0) [0|255] ""  NBCMU
 SG_ SBICU10_CellTemp_HighWarning : 25|2@0+ (1,0) [0|3] ""  NBCMU
 SG_ SBICU10_AddrInput_State : 32|1@0+ (1,0) [0|1] ""  NBCMU
 SG_ SBICU10_AddrOutput_State : 33|1@0+ (1,0) [0|1] ""  NBCMU
 SG_ SBICU10_SoftVer : 47|8@0+ (1,0) [0|255] ""  NBCMU
 SG_ SBICU10_HardVer : 55|8@0+ (1,0) [0|255] ""  NBCMU
 SG_ SBICU10_RunAlivCoun : 63|8@0+ (1,0) [0|255] ""  NBCMU

BO_ 2562916138 SBICU10_TempExtremeInfo: 8 SBICU
 SG_ SBICU10_CellTempMax : 7|8@0+ (1,-40) [-40|215] "℃"  NBCMU
 SG_ SBICU10_CellTempMin : 15|8@0+ (1,-40) [-40|215] "℃"  NBCMU
 SG_ SBICU10_CellTempAvg : 23|8@0+ (1,-40) [-40|215] "℃"  NBCMU
 SG_ SBICU10_CellTempMaxCode : 31|8@0+ (1,0) [0|255] ""  NBCMU
 SG_ SBICU10_CellTempMinCode : 39|8@0+ (1,0) [0|255] ""  NBCMU
 SG_ SBICU10_SupplyVolt : 40|9@0+ (0.1,0) [0|51.1] "V"  NBCMU

BO_ 2564489002 SBICU10_CellTemp01: 8 SBICU
 SG_ SBICU10_Temp01 : 7|8@0+ (1,-40) [-40|215] "℃"  NBCMU
 SG_ SBICU10_Temp02 : 15|8@0+ (1,-40) [-40|215] "℃"  NBCMU
 SG_ SBICU10_Temp03 : 23|8@0+ (1,-40) [-40|215] "℃"  NBCMU
 SG_ SBICU10_Temp04 : 31|8@0+ (1,-40) [-40|215] "℃"  NBCMU
 SG_ SBICU10_Temp05 : 39|8@0+ (1,-40) [-40|215] "℃"  NBCMU
 SG_ SBICU10_Temp06 : 47|8@0+ (1,-40) [-40|215] "℃"  NBCMU
 SG_ SBICU10_Temp07 : 55|8@0+ (1,-40) [-40|215] "℃"  NBCMU
 SG_ SBICU10_Temp08 : 63|8@0+ (1,-40) [-40|215] "℃"  NBCMU

BO_ 2564554538 SBICU10_CellTemp02: 8 SBICU
 SG_ SBICU10_Temp09 : 7|8@0+ (1,-40) [-40|215] "℃"  NBCMU
 SG_ SBICU10_Temp10 : 15|8@0+ (1,-40) [-40|215] "℃"  NBCMU
 SG_ SBICU10_Temp11 : 23|8@0+ (1,-40) [-40|215] "℃"  NBCMU
 SG_ SBICU10_Temp12 : 31|8@0+ (1,-40) [-40|215] "℃"  NBCMU
 SG_ SBICU10_Temp13 : 39|8@0+ (1,-40) [-40|215] "℃"  NBCMU
 SG_ SBICU10_Temp14 : 47|8@0+ (1,-40) [-40|215] "℃"  NBCMU
 SG_ SBICU10_Temp15 : 55|8@0+ (1,-40) [-40|215] "℃"  NBCMU
 SG_ SBICU10_Temp16 : 63|8@0+ (1,-40) [-40|215] "℃"  NBCMU

BO_ 2564620074 SBICU10_CellTemp03: 8 SBICU
 SG_ SBICU10_Temp17 : 7|8@0+ (1,-40) [-40|215] "℃"  NBCMU
 SG_ SBICU10_Temp18 : 15|8@0+ (1,-40) [-40|215] "℃"  NBCMU
 SG_ SBICU10_Temp19 : 23|8@0+ (1,-40) [-40|215] "℃"  NBCMU
 SG_ SBICU10_Temp20 : 31|8@0+ (1,-40) [-40|215] "℃"  NBCMU
 SG_ SBICU10_Temp21 : 39|8@0+ (1,-40) [-40|215] "℃"  NBCMU
 SG_ SBICU10_Temp22 : 47|8@0+ (1,-40) [-40|215] "℃"  NBCMU
 SG_ SBICU10_Temp23 : 55|8@0+ (1,-40) [-40|215] "℃"  NBCMU
 SG_ SBICU10_Temp24 : 63|8@0+ (1,-40) [-40|215] "℃"  NBCMU

BO_ 2564685610 SBICU10_CellTemp04: 8 SBICU
 SG_ SBICU10_Temp25 : 7|8@0+ (1,-40) [-40|215] "℃"  NBCMU
 SG_ SBICU10_Temp26 : 15|8@0+ (1,-40) [-40|215] "℃"  NBCMU
 SG_ SBICU10_Temp27 : 23|8@0+ (1,-40) [-40|215] "℃"  NBCMU
 SG_ SBICU10_Temp28 : 31|8@0+ (1,-40) [-40|215] "℃"  NBCMU
 SG_ SBICU10_Temp29 : 39|8@0+ (1,-40) [-40|215] "℃"  NBCMU
 SG_ SBICU10_Temp30 : 47|8@0+ (1,-40) [-40|215] "℃"  NBCMU
 SG_ SBICU10_Temp31 : 55|8@0+ (1,-40) [-40|215] "℃"  NBCMU
 SG_ SBICU10_Temp32 : 63|8@0+ (1,-40) [-40|215] "℃"  NBCMU

BO_ 2564751146 SBICU10_CellTemp05: 8 SBICU
 SG_ SBICU10_Temp33 : 7|8@0+ (1,-40) [-40|215] "℃"  NBCMU
 SG_ SBICU10_Temp34 : 15|8@0+ (1,-40) [-40|215] "℃"  NBCMU
 SG_ SBICU10_Temp35 : 23|8@0+ (1,-40) [-40|215] "℃"  NBCMU
 SG_ SBICU10_Temp36 : 31|8@0+ (1,-40) [-40|215] "℃"  NBCMU

BO_ 2564947754 SBICU10_SW_Info: 8 SBICU
 SG_ SBICU10_NBCMU_Addr_SW : 7|8@0+ (1,0) [0|255] ""  SBCMU
 SG_ SBICU10_SW01 : 15|8@0+ (1,0) [0|255] ""  SBCMU
 SG_ SBICU10_SW02 : 23|8@0+ (1,0) [0|255] ""  SBCMU
 SG_ SBICU10_SW03 : 31|8@0+ (1,0) [0|255] ""  SBCMU
 SG_ SBICU10_SW04 : 39|8@0+ (1,0) [0|255] ""  SBCMU
 SG_ SBICU10_SW05 : 47|8@0+ (1,0) [0|255] ""  SBCMU
 SG_ SBICU10_SW06 : 55|8@0+ (1,0) [0|255] ""  SBCMU
 SG_ SBICU10_SW07 : 63|8@0+ (1,0) [0|255] ""  SBCMU

BO_ 2565013290 SBICU10_HW_Info: 8 SBICU
 SG_ SBICU10_NBCMU_Addr_HW : 7|8@0+ (1,0) [0|255] ""  SBCMU
 SG_ SBICU10_HW01 : 15|8@0+ (1,0) [0|255] ""  SBCMU
 SG_ SBICU10_HW02 : 23|8@0+ (1,0) [0|255] ""  SBCMU
 SG_ SBICU10_HW03 : 31|8@0+ (1,0) [0|255] ""  SBCMU
 SG_ SBICU10_HW04 : 39|8@0+ (1,0) [0|255] ""  SBCMU
 SG_ SBICU10_HW05 : 47|8@0+ (1,0) [0|255] ""  SBCMU
 SG_ SBICU10_HW06 : 55|8@0+ (1,0) [0|255] ""  SBCMU
 SG_ SBICU10_HW07 : 63|8@0+ (1,0) [0|255] ""  SBCMU

BO_ 2564677418 SBICU10_DiaResponse: 8 SBICU
 SG_ SBICU10_RespData : 7|64@0+ (1,0) [0|1.84467440737096E+019] ""  Vector_XXX

BO_ 2562785067 SBICU11_RunState: 8 SBICU
 SG_ SBICU11_Address : 7|8@0+ (1,0) [0|255] ""  NBCMU
 SG_ SBICU11_TempNum : 23|8@0+ (1,0) [0|255] ""  NBCMU
 SG_ SBICU11_CellTemp_HighWarning : 25|2@0+ (1,0) [0|3] ""  NBCMU
 SG_ SBICU11_AddrInput_State : 32|1@0+ (1,0) [0|1] ""  NBCMU
 SG_ SBICU11_AddrOutput_State : 33|1@0+ (1,0) [0|1] ""  NBCMU
 SG_ SBICU11_SoftVer : 47|8@0+ (1,0) [0|255] ""  NBCMU
 SG_ SBICU11_HardVer : 55|8@0+ (1,0) [0|255] ""  NBCMU
 SG_ SBICU11_RunAlivCoun : 63|8@0+ (1,0) [0|255] ""  NBCMU

BO_ 2562916139 SBICU11_TempExtremeInfo: 8 SBICU
 SG_ SBICU11_CellTempMax : 7|8@0+ (1,-40) [-40|215] "℃"  NBCMU
 SG_ SBICU11_CellTempMin : 15|8@0+ (1,-40) [-40|215] "℃"  NBCMU
 SG_ SBICU11_CellTempAvg : 23|8@0+ (1,-40) [-40|215] "℃"  NBCMU
 SG_ SBICU11_CellTempMaxCode : 31|8@0+ (1,0) [0|255] ""  NBCMU
 SG_ SBICU11_CellTempMinCode : 39|8@0+ (1,0) [0|255] ""  NBCMU
 SG_ SBICU11_SupplyVolt : 40|9@0+ (0.1,0) [0|51.1] "V"  NBCMU

BO_ 2564489003 SBICU11_CellTemp01: 8 SBICU
 SG_ SBICU11_Temp01 : 7|8@0+ (1,-40) [-40|215] "℃"  NBCMU
 SG_ SBICU11_Temp02 : 15|8@0+ (1,-40) [-40|215] "℃"  NBCMU
 SG_ SBICU11_Temp03 : 23|8@0+ (1,-40) [-40|215] "℃"  NBCMU
 SG_ SBICU11_Temp04 : 31|8@0+ (1,-40) [-40|215] "℃"  NBCMU
 SG_ SBICU11_Temp05 : 39|8@0+ (1,-40) [-40|215] "℃"  NBCMU
 SG_ SBICU11_Temp06 : 47|8@0+ (1,-40) [-40|215] "℃"  NBCMU
 SG_ SBICU11_Temp07 : 55|8@0+ (1,-40) [-40|215] "℃"  NBCMU
 SG_ SBICU11_Temp08 : 63|8@0+ (1,-40) [-40|215] "℃"  NBCMU

BO_ 2564554539 SBICU11_CellTemp02: 8 SBICU
 SG_ SBICU11_Temp09 : 7|8@0+ (1,-40) [-40|215] "℃"  NBCMU
 SG_ SBICU11_Temp10 : 15|8@0+ (1,-40) [-40|215] "℃"  NBCMU
 SG_ SBICU11_Temp11 : 23|8@0+ (1,-40) [-40|215] "℃"  NBCMU
 SG_ SBICU11_Temp12 : 31|8@0+ (1,-40) [-40|215] "℃"  NBCMU
 SG_ SBICU11_Temp13 : 39|8@0+ (1,-40) [-40|215] "℃"  NBCMU
 SG_ SBICU11_Temp14 : 47|8@0+ (1,-40) [-40|215] "℃"  NBCMU
 SG_ SBICU11_Temp15 : 55|8@0+ (1,-40) [-40|215] "℃"  NBCMU
 SG_ SBICU11_Temp16 : 63|8@0+ (1,-40) [-40|215] "℃"  NBCMU

BO_ 2564620075 SBICU11_CellTemp03: 8 SBICU
 SG_ SBICU11_Temp17 : 7|8@0+ (1,-40) [-40|215] "℃"  NBCMU
 SG_ SBICU11_Temp18 : 15|8@0+ (1,-40) [-40|215] "℃"  NBCMU
 SG_ SBICU11_Temp19 : 23|8@0+ (1,-40) [-40|215] "℃"  NBCMU
 SG_ SBICU11_Temp20 : 31|8@0+ (1,-40) [-40|215] "℃"  NBCMU
 SG_ SBICU11_Temp21 : 39|8@0+ (1,-40) [-40|215] "℃"  NBCMU
 SG_ SBICU11_Temp22 : 47|8@0+ (1,-40) [-40|215] "℃"  NBCMU
 SG_ SBICU11_Temp23 : 55|8@0+ (1,-40) [-40|215] "℃"  NBCMU
 SG_ SBICU11_Temp24 : 63|8@0+ (1,-40) [-40|215] "℃"  NBCMU

BO_ 2564685611 SBICU11_CellTemp04: 8 SBICU
 SG_ SBICU11_Temp25 : 7|8@0+ (1,-40) [-40|215] "℃"  NBCMU
 SG_ SBICU11_Temp26 : 15|8@0+ (1,-40) [-40|215] "℃"  NBCMU
 SG_ SBICU11_Temp27 : 23|8@0+ (1,-40) [-40|215] "℃"  NBCMU
 SG_ SBICU11_Temp28 : 31|8@0+ (1,-40) [-40|215] "℃"  NBCMU
 SG_ SBICU11_Temp29 : 39|8@0+ (1,-40) [-40|215] "℃"  NBCMU
 SG_ SBICU11_Temp30 : 47|8@0+ (1,-40) [-40|215] "℃"  NBCMU
 SG_ SBICU11_Temp31 : 55|8@0+ (1,-40) [-40|215] "℃"  NBCMU
 SG_ SBICU11_Temp32 : 63|8@0+ (1,-40) [-40|215] "℃"  NBCMU

BO_ 2564751147 SBICU11_CellTemp05: 8 SBICU
 SG_ SBICU11_Temp33 : 7|8@0+ (1,-40) [-40|215] "℃"  NBCMU
 SG_ SBICU11_Temp34 : 15|8@0+ (1,-40) [-40|215] "℃"  NBCMU
 SG_ SBICU11_Temp35 : 23|8@0+ (1,-40) [-40|215] "℃"  NBCMU
 SG_ SBICU11_Temp36 : 31|8@0+ (1,-40) [-40|215] "℃"  NBCMU

BO_ 2564947755 SBICU11_SW_Info: 8 SBICU
 SG_ SBICU11_NBCMU_Addr_SW : 7|8@0+ (1,0) [0|255] ""  SBCMU
 SG_ SBICU11_SW01 : 15|8@0+ (1,0) [0|255] ""  SBCMU
 SG_ SBICU11_SW02 : 23|8@0+ (1,0) [0|255] ""  SBCMU
 SG_ SBICU11_SW03 : 31|8@0+ (1,0) [0|255] ""  SBCMU
 SG_ SBICU11_SW04 : 39|8@0+ (1,0) [0|255] ""  SBCMU
 SG_ SBICU11_SW05 : 47|8@0+ (1,0) [0|255] ""  SBCMU
 SG_ SBICU11_SW06 : 55|8@0+ (1,0) [0|255] ""  SBCMU
 SG_ SBICU11_SW07 : 63|8@0+ (1,0) [0|255] ""  SBCMU

BO_ 2565013291 SBICU11_HW_Info: 8 SBICU
 SG_ SBICU11_NBCMU_Addr_HW : 7|8@0+ (1,0) [0|255] ""  SBCMU
 SG_ SBICU11_HW01 : 15|8@0+ (1,0) [0|255] ""  SBCMU
 SG_ SBICU11_HW02 : 23|8@0+ (1,0) [0|255] ""  SBCMU
 SG_ SBICU11_HW03 : 31|8@0+ (1,0) [0|255] ""  SBCMU
 SG_ SBICU11_HW04 : 39|8@0+ (1,0) [0|255] ""  SBCMU
 SG_ SBICU11_HW05 : 47|8@0+ (1,0) [0|255] ""  SBCMU
 SG_ SBICU11_HW06 : 55|8@0+ (1,0) [0|255] ""  SBCMU
 SG_ SBICU11_HW07 : 63|8@0+ (1,0) [0|255] ""  SBCMU

BO_ 2564677419 SBICU11_DiaResponse: 8 SBICU
 SG_ SBICU11_RespData : 7|64@0+ (1,0) [0|1.84467440737096E+019] ""  Vector_XXX

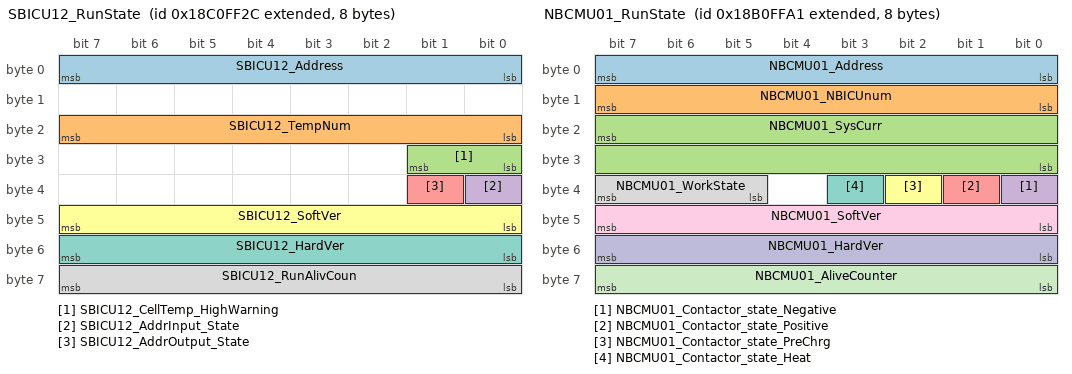
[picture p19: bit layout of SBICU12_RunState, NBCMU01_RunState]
BO_ 2562785068 SBICU12_RunState: 8 SBICU
 SG_ SBICU12_Address : 7|8@0+ (1,0) [0|255] ""  NBCMU
 SG_ SBICU12_TempNum : 23|8@0+ (1,0) [0|255] ""  NBCMU
 SG_ SBICU12_CellTemp_HighWarning : 25|2@0+ (1,0) [0|3] ""  NBCMU
 SG_ SBICU12_AddrInput_State : 32|1@0+ (1,0) [0|1] ""  NBCMU
 SG_ SBICU12_AddrOutput_State : 33|1@0+ (1,0) [0|1] ""  NBCMU
 SG_ SBICU12_SoftVer : 47|8@0+ (1,0) [0|255] ""  NBCMU
 SG_ SBICU12_HardVer : 55|8@0+ (1,0) [0|255] ""  NBCMU
 SG_ SBICU12_RunAlivCoun : 63|8@0+ (1,0) [0|255] ""  NBCMU

BO_ 2562916140 SBICU12_TempExtremeInfo: 8 SBICU
 SG_ SBICU12_CellTempMax : 7|8@0+ (1,-40) [-40|215] "℃"  NBCMU
 SG_ SBICU12_CellTempMin : 15|8@0+ (1,-40) [-40|215] "℃"  NBCMU
 SG_ SBICU12_CellTempAvg : 23|8@0+ (1,-40) [-40|215] "℃"  NBCMU
 SG_ SBICU12_CellTempMaxCode : 31|8@0+ (1,0) [0|255] ""  NBCMU
 SG_ SBICU12_CellTempMinCode : 39|8@0+ (1,0) [0|255] ""  NBCMU
 SG_ SBICU12_SupplyVolt : 40|9@0+ (0.1,0) [0|51.1] "V"  NBCMU

BO_ 2564489004 SBICU12_CellTemp01: 8 SBICU
 SG_ SBICU12_Temp01 : 7|8@0+ (1,-40) [-40|215] "℃"  NBCMU
 SG_ SBICU12_Temp02 : 15|8@0+ (1,-40) [-40|215] "℃"  NBCMU
 SG_ SBICU12_Temp03 : 23|8@0+ (1,-40) [-40|215] "℃"  NBCMU
 SG_ SBICU12_Temp04 : 31|8@0+ (1,-40) [-40|215] "℃"  NBCMU
 SG_ SBICU12_Temp05 : 39|8@0+ (1,-40) [-40|215] "℃"  NBCMU
 SG_ SBICU12_Temp06 : 47|8@0+ (1,-40) [-40|215] "℃"  NBCMU
 SG_ SBICU12_Temp07 : 55|8@0+ (1,-40) [-40|215] "℃"  NBCMU
 SG_ SBICU12_Temp08 : 63|8@0+ (1,-40) [-40|215] "℃"  NBCMU

BO_ 2564554540 SBICU12_CellTemp02: 8 SBICU
 SG_ SBICU12_Temp09 : 7|8@0+ (1,-40) [-40|215] "℃"  NBCMU
 SG_ SBICU12_Temp10 : 15|8@0+ (1,-40) [-40|215] "℃"  NBCMU
 SG_ SBICU12_Temp11 : 23|8@0+ (1,-40) [-40|215] "℃"  NBCMU
 SG_ SBICU12_Temp12 : 31|8@0+ (1,-40) [-40|215] "℃"  NBCMU
 SG_ SBICU12_Temp13 : 39|8@0+ (1,-40) [-40|215] "℃"  NBCMU
 SG_ SBICU12_Temp14 : 47|8@0+ (1,-40) [-40|215] "℃"  NBCMU
 SG_ SBICU12_Temp15 : 55|8@0+ (1,-40) [-40|215] "℃"  NBCMU
 SG_ SBICU12_Temp16 : 63|8@0+ (1,-40) [-40|215] "℃"  NBCMU

BO_ 2564620076 SBICU12_CellTemp03: 8 SBICU
 SG_ SBICU12_Temp17 : 7|8@0+ (1,-40) [-40|215] "℃"  NBCMU
 SG_ SBICU12_Temp18 : 15|8@0+ (1,-40) [-40|215] "℃"  NBCMU
 SG_ SBICU12_Temp19 : 23|8@0+ (1,-40) [-40|215] "℃"  NBCMU
 SG_ SBICU12_Temp20 : 31|8@0+ (1,-40) [-40|215] "℃"  NBCMU
 SG_ SBICU12_Temp21 : 39|8@0+ (1,-40) [-40|215] "℃"  NBCMU
 SG_ SBICU12_Temp22 : 47|8@0+ (1,-40) [-40|215] "℃"  NBCMU
 SG_ SBICU12_Temp23 : 55|8@0+ (1,-40) [-40|215] "℃"  NBCMU
 SG_ SBICU12_Temp24 : 63|8@0+ (1,-40) [-40|215] "℃"  NBCMU

BO_ 2564685612 SBICU12_CellTemp04: 8 SBICU
 SG_ SBICU12_Temp25 : 7|8@0+ (1,-40) [-40|215] "℃"  NBCMU
 SG_ SBICU12_Temp26 : 15|8@0+ (1,-40) [-40|215] "℃"  NBCMU
 SG_ SBICU12_Temp27 : 23|8@0+ (1,-40) [-40|215] "℃"  NBCMU
 SG_ SBICU12_Temp28 : 31|8@0+ (1,-40) [-40|215] "℃"  NBCMU
 SG_ SBICU12_Temp29 : 39|8@0+ (1,-40) [-40|215] "℃"  NBCMU
 SG_ SBICU12_Temp30 : 47|8@0+ (1,-40) [-40|215] "℃"  NBCMU
 SG_ SBICU12_Temp31 : 55|8@0+ (1,-40) [-40|215] "℃"  NBCMU
 SG_ SBICU12_Temp32 : 63|8@0+ (1,-40) [-40|215] "℃"  NBCMU

BO_ 2564751148 SBICU12_CellTemp05: 8 SBICU
 SG_ SBICU12_Temp33 : 7|8@0+ (1,-40) [-40|215] "℃"  NBCMU
 SG_ SBICU12_Temp34 : 15|8@0+ (1,-40) [-40|215] "℃"  NBCMU
 SG_ SBICU12_Temp35 : 23|8@0+ (1,-40) [-40|215] "℃"  NBCMU
 SG_ SBICU12_Temp36 : 31|8@0+ (1,-40) [-40|215] "℃"  NBCMU

BO_ 2564947756 SBICU12_SW_Info: 8 SBICU
 SG_ SBICU12_NBCMU_Addr_SW : 7|8@0+ (1,0) [0|255] ""  SBCMU
 SG_ SBICU12_SW01 : 15|8@0+ (1,0) [0|255] ""  SBCMU
 SG_ SBICU12_SW02 : 23|8@0+ (1,0) [0|255] ""  SBCMU
 SG_ SBICU12_SW03 : 31|8@0+ (1,0) [0|255] ""  SBCMU
 SG_ SBICU12_SW04 : 39|8@0+ (1,0) [0|255] ""  SBCMU
 SG_ SBICU12_SW05 : 47|8@0+ (1,0) [0|255] ""  SBCMU
 SG_ SBICU12_SW06 : 55|8@0+ (1,0) [0|255] ""  SBCMU
 SG_ SBICU12_SW07 : 63|8@0+ (1,0) [0|255] ""  SBCMU

BO_ 2565013292 SBICU12_HW_Info: 8 SBICU
 SG_ SBICU12_NBCMU_Addr_HW : 7|8@0+ (1,0) [0|255] ""  SBCMU
 SG_ SBICU12_HW01 : 15|8@0+ (1,0) [0|255] ""  SBCMU
 SG_ SBICU12_HW02 : 23|8@0+ (1,0) [0|255] ""  SBCMU
 SG_ SBICU12_HW03 : 31|8@0+ (1,0) [0|255] ""  SBCMU
 SG_ SBICU12_HW04 : 39|8@0+ (1,0) [0|255] ""  SBCMU
 SG_ SBICU12_HW05 : 47|8@0+ (1,0) [0|255] ""  SBCMU
 SG_ SBICU12_HW06 : 55|8@0+ (1,0) [0|255] ""  SBCMU
 SG_ SBICU12_HW07 : 63|8@0+ (1,0) [0|255] ""  SBCMU

BO_ 2564677420 SBICU12_DiaResponse: 8 SBICU
 SG_ SBICU12_RespData : 7|64@0+ (1,0) [0|1.84467440737096E+019] ""  Vector_XXX

BO_ 2562129824 NBCMU_NBICU_Control: 8 NBCMU
 SG_ NBCMU_NBICUSysCurr : 7|16@0+ (0.1,-3000) [-3000|3000] "A"  NBICU
 SG_ NBCMU_SysCellVoltMin : 23|16@0+ (1,0) [0|65535] "mV"  NBICU
 SG_ NBCMU_OnlineNBICUnum : 39|8@0+ (1,0) [0|255] ""  NBICU
 SG_ NBCMU_NBICU_Address : 63|8@0+ (1,0) [0|255] ""  NBICU

BO_ 2561736609 NBCMU01_RunState: 8 NBCMU
 SG_ NBCMU01_Address : 7|8@0+ (1,0) [0|255] ""  DAPP
 SG_ NBCMU01_NBICUnum : 15|8@0+ (1,0) [0|255] ""  DAPP
 SG_ NBCMU01_SysCurr : 23|16@0+ (0.1,-3000) [-3000|3000] "A"  DAPP
 SG_ NBCMU01_Contactor_state_Negative : 32|1@0+ (1,0) [0|1] ""  DAPP
 SG_ NBCMU01_Contactor_state_Positive : 33|1@0+ (1,0) [0|1] ""  DAPP
 SG_ NBCMU01_Contactor_state_PreChrg : 34|1@0+ (1,0) [0|1] ""  DAPP
 SG_ NBCMU01_Contactor_state_Heat : 35|1@0+ (1,0) [0|1] ""  DAPP
 SG_ NBCMU01_WorkState : 39|3@0+ (1,0) [0|7] ""  DAPP
 SG_ NBCMU01_SoftVer : 47|8@0+ (1,0) [0|255] ""  DAPP
 SG_ NBCMU01_HardVer : 55|8@0+ (1,0) [0|255] ""  DAPP
 SG_ NBCMU01_AliveCounter : 63|8@0+ (1,0) [0|255] ""  DAPP

CM_ BO_ 2564357898 "NBICU10 Tx and Cell Voltage08";
CM_ SG_ 2564357898 NBICU10_Cell29Volt "Cell29Volt单体29电压值";
CM_ SG_ 2564357898 NBICU10_Cell30Volt "Cell30Volt单体30电压值";
CM_ SG_ 2564357898 NBICU10_Cell31Volt "Cell31Volt单体31电压值";
CM_ SG_ 2564357898 NBICU10_Cell32Volt "Cell32Volt单体32电压值";
CM_ BO_ 2564423434 "NBICU10 Tx and Cell Voltage09";
CM_ SG_ 2564423434 NBICU10_Cell33Volt "Cell33Volt单体33电压值";
CM_ SG_ 2564423434 NBICU10_Cell34Volt "Cell34Volt单体34电压值";
CM_ SG_ 2564423434 NBICU10_Cell35Volt "Cell35Volt单体35电压值";
CM_ SG_ 2564423434 NBICU10_Cell36Volt "Cell36Volt单体36电压值";
CM_ BO_ 2564488970 "NBICU10 Tx and Cell Temp01";
CM_ SG_ 2564488970 NBICU10_Temp01 "NTC01-温度值";
CM_ SG_ 2564488970 NBICU10_Temp02 "NTC02-温度值";
CM_ SG_ 2564488970 NBICU10_Temp03 "NTC03-温度值";
CM_ SG_ 2564488970 NBICU10_Temp04 "NTC04-温度值";
CM_ SG_ 2564488970 NBICU10_Temp05 "NTC05-温度值";
CM_ SG_ 2564488970 NBICU10_Temp06 "NTC06-温度值";
CM_ SG_ 2564488970 NBICU10_Temp07 "NTC07-温度值";
CM_ SG_ 2564488970 NBICU10_Temp08 "NTC08-温度值";
CM_ BO_ 2564554506 "NBICU10 Tx and Cell Temp02";
CM_ SG_ 2564554506 NBICU10_Temp09 "NTC09-温度值";
CM_ SG_ 2564554506 NBICU10_Temp10 "NTC10-温度值";
CM_ SG_ 2564554506 NBICU10_Temp11 "NTC11-温度值";
CM_ SG_ 2564554506 NBICU10_Temp12 "NTC12-温度值";
CM_ SG_ 2564554506 NBICU10_Temp13 "NTC13-温度值";
CM_ SG_ 2564554506 NBICU10_Temp14 "NTC14-温度值";
CM_ SG_ 2564554506 NBICU10_Temp15 "NTC15-温度值";
CM_ SG_ 2564554506 NBICU10_Temp16 "NTC16-温度值";
CM_ BO_ 2564620042 "NBICU10 Tx and Cell Temp03";
CM_ SG_ 2564620042 NBICU10_Temp17 "NTC17-温度值";
CM_ SG_ 2564620042 NBICU10_Temp18 "NTC18-温度值";
CM_ SG_ 2564620042 NBICU10_Temp19 "NTC19-温度值";
CM_ SG_ 2564620042 NBICU10_Temp20 "NTC20-温度值";
CM_ SG_ 2564620042 NBICU10_Temp21 "NTC21-温度值";
CM_ SG_ 2564620042 NBICU10_Temp22 "NTC22-温度值";
CM_ SG_ 2564620042 NBICU10_Temp23 "NTC23-温度值";
CM_ SG_ 2564620042 NBICU10_Temp24 "NTC24-温度值";
CM_ BO_ 2564685578 "NBICU10 Tx and Cell Temp04";
CM_ SG_ 2564685578 NBICU10_Temp25 "NTC25-温度值";
CM_ SG_ 2564685578 NBICU10_Temp26 "NTC26-温度值";
CM_ SG_ 2564685578 NBICU10_Temp27 "NTC27-温度值";
CM_ SG_ 2564685578 NBICU10_Temp28 "NTC28-温度值";
CM_ SG_ 2564685578 NBICU10_Temp29 "NTC29-温度值";
CM_ SG_ 2564685578 NBICU10_Temp30 "NTC30-温度值";
CM_ SG_ 2564685578 NBICU10_Temp31 "NTC31-温度值";
CM_ SG_ 2564685578 NBICU10_Temp32 "NTC32-温度值";
CM_ BO_ 2564751114 "NBICU10 Tx and Cell Temp05";
CM_ SG_ 2564751114 NBICU10_Temp33 "NTC33-温度值";
CM_ SG_ 2564751114 NBICU10_Temp34 "NTC34-温度值";
CM_ SG_ 2564751114 NBICU10_Temp35 "NTC35-温度值";
CM_ SG_ 2564751114 NBICU10_Temp36 "NTC36-温度值";
CM_ BO_ 2564947722 "NBICU10 Tx and Software";
CM_ SG_ 2564947722 NBICU10_NBCMU_Addr_SW "NBICU10 NBCMU Address
NBICU10接收NBCMU地址";
CM_ SG_ 2564947722 NBICU10_SW01 "NBICU10 Software Byte 01
NBICU10软件版本第01字节";
CM_ SG_ 2564947722 NBICU10_SW02 "NBICU10 Software Byte 02
NBICU10软件版本第02字节";
CM_ SG_ 2564947722 NBICU10_SW03 "NBICU10 Software Byte 03
NBICU10软件版本第03字节";
CM_ SG_ 2564947722 NBICU10_SW04 "NBICU10 Software Byte 04
NBICU10软件版本第04字节";
CM_ SG_ 2564947722 NBICU10_SW05 "NBICU10 Software Byte 05
NBICU10软件版本第05字节";
CM_ SG_ 2564947722 NBICU10_SW06 "NBICU10 Software Byte 06
NBICU10软件版本第06字节";
CM_ SG_ 2564947722 NBICU10_SW07 "NBICU10 Software Byte 07
NBICU10软件版本第07字节";
CM_ BO_ 2565013258 "NBICU10 Tx and Hardware";
CM_ SG_ 2565013258 NBICU10_NBCMU_Addr_HW "NBICU10 NBCMU Address
NBICU10接收NBCMU地址";
CM_ SG_ 2565013258 NBICU10_HW01 "NBICU10 Hardware Byte 01
NBICU10硬件版本第01字节";
CM_ SG_ 2565013258 NBICU10_HW02 "NBICU10 Hardware Byte 02
NBICU10硬件版本第02字节";
CM_ SG_ 2565013258 NBICU10_HW03 "NBICU10 Hardware Byte 03
NBICU10硬件版本第03字节";
CM_ SG_ 2565013258 NBICU10_HW04 "NBICU10 Hardware Byte 04
NBICU10硬件版本第04字节";
CM_ SG_ 2565013258 NBICU10_HW05 "NBICU10 Hardware Byte 05
NBICU10硬件版本第05字节";
CM_ SG_ 2565013258 NBICU10_HW06 "NBICU10 Hardware Byte 06
NBICU10硬件版本第06字节";
CM_ SG_ 2565013258 NBICU10_HW07 "NBICU10 Hardware Byte 07
NBICU10硬件版本第07字节";
CM_ BO_ 2564677386 "NBICU10 Tx and DiaResponse";
CM_ BO_ 2562785035 "NBICU11 Tx and Run State";
CM_ SG_ 2562785035 NBICU11_Address "Address
从机地址";
CM_ SG_ 2562785035 NBICU11_CellVNum "CellVNum
配置电压采集串数";
CM_ SG_ 2562785035 NBICU11_TempNum "TempNum
配置温度采集个数";
CM_ SG_ 2562785035 NBICU11_ErrFlag "ErrFlag
故障标志(预留)";
CM_ SG_ 2562785035 NBICU11_AddrInput_State "Addr Input_State
检测地址状态";
CM_ SG_ 2562785035 NBICU11_AddrOutput_State "Addr Output_State
输出地址状态";
CM_ SG_ 2562785035 NBICU11_HSD01Sta "HSD01
高边1控制状态(预留)";
CM_ SG_ 2562785035 NBICU11_SoftVer "SoftVer
软件版本";
CM_ SG_ 2562785035 NBICU11_HardVer "HardVer
硬件版本";
CM_ SG_ 2562785035 NBICU11_RunAlivCoun "AliveCounter
心跳指数";
CM_ BO_ 2562850571 "NBICU11 Tx and VoltExtremeInfo";
CM_ SG_ 2562850571 NBICU11_CellVoltMax "最高单体电压";
CM_ SG_ 2562850571 NBICU11_CellVoltMin "最低单体电压";
CM_ SG_ 2562850571 NBICU11_CellVoltMaxCode "最高单体电压序号";
CM_ SG_ 2562850571 NBICU11_CellVoltMinCode "最低单体电压序号";
CM_ SG_ 2562850571 NBICU11_CellSumVolt "电池包累计总压";
CM_ BO_ 2562916107 "NBICU11 Tx and TempExtremeInfo";
CM_ SG_ 2562916107 NBICU11_CellTempMax "最高温度";
CM_ SG_ 2562916107 NBICU11_CellTempMin "最低温度";
CM_ SG_ 2562916107 NBICU11_CellTempAvg "平均温度";
CM_ SG_ 2562916107 NBICU11_CellTempMaxCode "最高温度序号";
CM_ SG_ 2562916107 NBICU11_CellTempMinCode "最低温度序号";
CM_ SG_ 2562916107 NBICU11_SupplyVolt "供电电压";
CM_ SG_ 2562916107 NBICU11_PCB_Temp "板载温度";
CM_ BO_ 2562981643 "NBICU11 Tx and Balance State";
CM_ SG_ 2562981643 NBICU11_Cell0108BalaSta "Cell0108BalaSta
单体1至8通道均衡状态";
CM_ SG_ 2562981643 NBICU11_Cell0916BalaSta "Cell0916BalaSta
单体9至16通道均衡标志";
CM_ SG_ 2562981643 NBICU11_Cell1724BalaSta "Cell1724BalaSta
单体17至24通道均衡状态";
CM_ SG_ 2562981643 NBICU11_Cell2532BalaSta "Cell2532BalaSta
单体25至32通道均衡状态";
CM_ SG_ 2562981643 NBICU11_Cell3336BalaSta "Cell3336BalaSta
单体33至36通道均衡状态";
CM_ SG_ 2562981643 NBICU11_SysSOH "Sys SOH
电池包SOH";
CM_ SG_ 2562981643 NBICU11_CycleTime "CycleTime
循环次数";
CM_ BO_ 2563899147 "NBICU11 Tx and Cell Voltage01";
CM_ SG_ 2563899147 NBICU11_Cell01Volt "Cell01Volt单体01电压值";
CM_ SG_ 2563899147 NBICU11_Cell02Volt "Cell02Volt单体02电压值";
CM_ SG_ 2563899147 NBICU11_Cell03Volt "Cell03Volt单体03电压值";
CM_ SG_ 2563899147 NBICU11_Cell04Volt "Cell04Volt单体04电压值";
CM_ BO_ 2563964683 "NBICU11 Tx and Cell Voltage02";
CM_ SG_ 2563964683 NBICU11_Cell05Volt "Cell05Volt单体05电压值";
CM_ SG_ 2563964683 NBICU11_Cell06Volt "Cell06Volt单体06电压值";
CM_ SG_ 2563964683 NBICU11_Cell07Volt "Cell07Volt单体07电压值";
CM_ SG_ 2563964683 NBICU11_Cell08Volt "Cell08Volt单体08电压值";
CM_ BO_ 2564030219 "NBICU11 Tx and Cell Voltage03";
CM_ SG_ 2564030219 NBICU11_Cell09Volt "Cell09Volt单体09电压值";
CM_ SG_ 2564030219 NBICU11_Cell10Volt "Cell10Volt单体10电压值";
CM_ SG_ 2564030219 NBICU11_Cell11Volt "Cell11Volt单体11电压值";
CM_ SG_ 2564030219 NBICU11_Cell12Volt "Cell12Volt单体12电压值";
CM_ BO_ 2564095755 "NBICU11 Tx and Cell Voltage04";
CM_ SG_ 2564095755 NBICU11_Cell13Volt "Cell13Volt单体13电压值";
CM_ SG_ 2564095755 NBICU11_Cell14Volt "Cell14Volt单体14电压值";
CM_ SG_ 2564095755 NBICU11_Cell15Volt "Cell15Volt单体15电压值";
CM_ SG_ 2564095755 NBICU11_Cell16Volt "Cell16Volt单体16电压值";
CM_ BO_ 2564161291 "NBICU11 Tx and Cell Voltage05";
CM_ SG_ 2564161291 NBICU11_Cell17Volt "Cell17Volt单体17电压值";
CM_ SG_ 2564161291 NBICU11_Cell18Volt "Cell18Volt单体18电压值";
CM_ SG_ 2564161291 NBICU11_Cell19Volt "Cell19Volt单体19电压值";
CM_ SG_ 2564161291 NBICU11_Cell20Volt "Cell20Volt单体20电压值";
CM_ BO_ 2564226827 "NBICU11 Tx and Cell Voltage06";
CM_ SG_ 2564226827 NBICU11_Cell21Volt "Cell21Volt单体21电压值";
CM_ SG_ 2564226827 NBICU11_Cell22Volt "Cell22Volt单体22电压值";
CM_ SG_ 2564226827 NBICU11_Cell23Volt "Cell23Volt单体23电压值";
CM_ SG_ 2564226827 NBICU11_Cell24Volt "Cell24Volt单体24电压值";
CM_ BO_ 2564292363 "NBICU11 Tx and Cell Voltage07";
CM_ SG_ 2564292363 NBICU11_Cell25Volt "Cell25Volt单体25电压值";
CM_ SG_ 2564292363 NBICU11_Cell26Volt "Cell26Volt单体26电压值";
CM_ SG_ 2564292363 NBICU11_Cell27Volt "Cell27Volt单体27电压值";
CM_ SG_ 2564292363 NBICU11_Cell28Volt "Cell28Volt单体28电压值";
CM_ BO_ 2564357899 "NBICU11 Tx and Cell Voltage08";
CM_ SG_ 2564357899 NBICU11_Cell29Volt "Cell29Volt单体29电压值";
CM_ SG_ 2564357899 NBICU11_Cell30Volt "Cell30Volt单体30电压值";
CM_ SG_ 2564357899 NBICU11_Cell31Volt "Cell31Volt单体31电压值";
CM_ SG_ 2564357899 NBICU11_Cell32Volt "Cell32Volt单体32电压值";
CM_ BO_ 2564423435 "NBICU11 Tx and Cell Voltage09";
CM_ SG_ 2564423435 NBICU11_Cell33Volt "Cell33Volt单体33电压值";
CM_ SG_ 2564423435 NBICU11_Cell34Volt "Cell34Volt单体34电压值";
CM_ SG_ 2564423435 NBICU11_Cell35Volt "Cell35Volt单体35电压值";
CM_ SG_ 2564423435 NBICU11_Cell36Volt "Cell36Volt单体36电压值";
CM_ BO_ 2564488971 "NBICU11 Tx and Cell Temp01";
CM_ SG_ 2564488971 NBICU11_Temp01 "NTC01-温度值";
CM_ SG_ 2564488971 NBICU11_Temp02 "NTC02-温度值";
CM_ SG_ 2564488971 NBICU11_Temp03 "NTC03-温度值";
CM_ SG_ 2564488971 NBICU11_Temp04 "NTC04-温度值";
CM_ SG_ 2564488971 NBICU11_Temp05 "NTC05-温度值";
CM_ SG_ 2564488971 NBICU11_Temp06 "NTC06-温度值";
CM_ SG_ 2564488971 NBICU11_Temp07 "NTC07-温度值";
CM_ SG_ 2564488971 NBICU11_Temp08 "NTC08-温度值";
CM_ BO_ 2564554507 "NBICU11 Tx and Cell Temp02";
CM_ SG_ 2564554507 NBICU11_Temp09 "NTC09-温度值";
CM_ SG_ 2564554507 NBICU11_Temp10 "NTC10-温度值";
CM_ SG_ 2564554507 NBICU11_Temp11 "NTC11-温度值";
CM_ SG_ 2564554507 NBICU11_Temp12 "NTC12-温度值";
CM_ SG_ 2564554507 NBICU11_Temp13 "NTC13-温度值";
CM_ SG_ 2564554507 NBICU11_Temp14 "NTC14-温度值";
CM_ SG_ 2564554507 NBICU11_Temp15 "NTC15-温度值";
CM_ SG_ 2564554507 NBICU11_Temp16 "NTC16-温度值";
CM_ BO_ 2564620043 "NBICU11 Tx and Cell Temp03";
CM_ SG_ 2564620043 NBICU11_Temp17 "NTC17-温度值";
CM_ SG_ 2564620043 NBICU11_Temp18 "NTC18-温度值";
CM_ SG_ 2564620043 NBICU11_Temp19 "NTC19-温度值";
CM_ SG_ 2564620043 NBICU11_Temp20 "NTC20-温度值";
CM_ SG_ 2564620043 NBICU11_Temp21 "NTC21-温度值";
CM_ SG_ 2564620043 NBICU11_Temp22 "NTC22-温度值";
CM_ SG_ 2564620043 NBICU11_Temp23 "NTC23-温度值";
CM_ SG_ 2564620043 NBICU11_Temp24 "NTC24-温度值";
CM_ BO_ 2564685579 "NBICU11 Tx and Cell Temp04";
CM_ SG_ 2564685579 NBICU11_Temp25 "NTC25-温度值";
CM_ SG_ 2564685579 NBICU11_Temp26 "NTC26-温度值";
CM_ SG_ 2564685579 NBICU11_Temp27 "NTC27-温度值";
CM_ SG_ 2564685579 NBICU11_Temp28 "NTC28-温度值";
CM_ SG_ 2564685579 NBICU11_Temp29 "NTC29-温度值";
CM_ SG_ 2564685579 NBICU11_Temp30 "NTC30-温度值";
CM_ SG_ 2564685579 NBICU11_Temp31 "NTC31-温度值";
CM_ SG_ 2564685579 NBICU11_Temp32 "NTC32-温度值";
CM_ BO_ 2564751115 "NBICU11 Tx and Cell Temp05";
CM_ SG_ 2564751115 NBICU11_Temp33 "NTC33-温度值";
CM_ SG_ 2564751115 NBICU11_Temp34 "NTC34-温度值";
CM_ SG_ 2564751115 NBICU11_Temp35 "NTC35-温度值";
CM_ SG_ 2564751115 NBICU11_Temp36 "NTC36-温度值";
CM_ BO_ 2564947723 "NBICU11 Tx and Software";
CM_ SG_ 2564947723 NBICU11_NBCMU_Addr_SW "NBICU11 NBCMU Address
NBICU11接收NBCMU地址";
CM_ SG_ 2564947723 NBICU11_SW01 "NBICU11 Software Byte 01
NBICU11软件版本第01字节";
CM_ SG_ 2564947723 NBICU11_SW02 "NBICU11 Software Byte 02
NBICU11软件版本第02字节";
CM_ SG_ 2564947723 NBICU11_SW03 "NBICU11 Software Byte 03
NBICU11软件版本第03字节";
CM_ SG_ 2564947723 NBICU11_SW04 "NBICU11 Software Byte 04
NBICU11软件版本第04字节";
CM_ SG_ 2564947723 NBICU11_SW05 "NBICU11 Software Byte 05
NBICU11软件版本第05字节";
CM_ SG_ 2564947723 NBICU11_SW06 "NBICU11 Software Byte 06
NBICU11软件版本第06字节";
CM_ SG_ 2564947723 NBICU11_SW07 "NBICU11 Software Byte 07
NBICU11软件版本第07字节";
CM_ BO_ 2565013259 "NBICU11 Tx and Hardware";
CM_ SG_ 2565013259 NBICU11_NBCMU_Addr_HW "NBICU11 NBCMU Address
NBICU11接收NBCMU地址";
CM_ SG_ 2565013259 NBICU11_HW01 "NBICU11 Hardware Byte 01
NBICU11硬件版本第01字节";
CM_ SG_ 2565013259 NBICU11_HW02 "NBICU11 Hardware Byte 02
NBICU11硬件版本第02字节";
CM_ SG_ 2565013259 NBICU11_HW03 "NBICU11 Hardware Byte 03
NBICU11硬件版本第03字节";
CM_ SG_ 2565013259 NBICU11_HW04 "NBICU11 Hardware Byte 04
NBICU11硬件版本第04字节";
CM_ SG_ 2565013259 NBICU11_HW05 "NBICU11 Hardware Byte 05
NBICU11硬件版本第05字节";
CM_ SG_ 2565013259 NBICU11_HW06 "NBICU11 Hardware Byte 06
NBICU11硬件版本第06字节";
CM_ SG_ 2565013259 NBICU11_HW07 "NBICU11 Hardware Byte 07
NBICU11硬件版本第07字节";
CM_ BO_ 2564677387 "NBICU11 Tx and DiaResponse";
CM_ BO_ 2562785036 "NBICU12 Tx and Run State";
CM_ SG_ 2562785036 NBICU12_Address "Address
从机地址";
CM_ SG_ 2562785036 NBICU12_CellVNum "CellVNum
配置电压采集串数";
CM_ SG_ 2562785036 NBICU12_TempNum "TempNum
配置温度采集个数";
CM_ SG_ 2562785036 NBICU12_ErrFlag "ErrFlag
故障标志(预留)";
CM_ SG_ 2562785036 NBICU12_AddrInput_State "Addr Input_State
检测地址状态";
CM_ SG_ 2562785036 NBICU12_AddrOutput_State "Addr Output_State
输出地址状态";
CM_ SG_ 2562785036 NBICU12_HSD01Sta "HSD01
高边1控制状态(预留)";
CM_ SG_ 2562785036 NBICU12_SoftVer "SoftVer
软件版本";
CM_ SG_ 2562785036 NBICU12_HardVer "HardVer
硬件版本";
CM_ SG_ 2562785036 NBICU12_RunAlivCoun "AliveCounter
心跳指数";
CM_ BO_ 2562850572 "NBICU12 Tx and VoltExtremeInfo";
CM_ SG_ 2562850572 NBICU12_CellVoltMax "最高单体电压";
CM_ SG_ 2562850572 NBICU12_CellVoltMin "最低单体电压";
CM_ SG_ 2562850572 NBICU12_CellVoltMaxCode "最高单体电压序号";
CM_ SG_ 2562850572 NBICU12_CellVoltMinCode "最低单体电压序号";
CM_ SG_ 2562850572 NBICU12_CellSumVolt "电池包累计总压";
CM_ BO_ 2562916108 "NBICU12 Tx and TempExtremeInfo";
CM_ SG_ 2562916108 NBICU12_CellTempMax "最高温度";
CM_ SG_ 2562916108 NBICU12_CellTempMin "最低温度";
CM_ SG_ 2562916108 NBICU12_CellTempAvg "平均温度";
CM_ SG_ 2562916108 NBICU12_CellTempMaxCode "最高温度序号";
CM_ SG_ 2562916108 NBICU12_CellTempMinCode "最低温度序号";
CM_ SG_ 2562916108 NBICU12_SupplyVolt "供电电压";
CM_ SG_ 2562916108 NBICU12_PCB_Temp "板载温度";
CM_ BO_ 2562981644 "NBICU12 Tx and Balance State";
CM_ SG_ 2562981644 NBICU12_Cell0108BalaSta "Cell0108BalaSta
单体1至8通道均衡状态";
CM_ SG_ 2562981644 NBICU12_Cell0916BalaSta "Cell0916BalaSta
单体9至16通道均衡标志";
CM_ SG_ 2562981644 NBICU12_Cell1724BalaSta "Cell1724BalaSta
单体17至24通道均衡状态";
CM_ SG_ 2562981644 NBICU12_Cell2532BalaSta "Cell2532BalaSta
单体25至32通道均衡状态";
CM_ SG_ 2562981644 NBICU12_Cell3336BalaSta "Cell3336BalaSta
单体33至36通道均衡状态";
CM_ SG_ 2562981644 NBICU12_SysSOH "Sys SOH
电池包SOH";
CM_ SG_ 2562981644 NBICU12_CycleTime "CycleTime
循环次数";
CM_ BO_ 2563899148 "NBICU12 Tx and Cell Voltage01";
CM_ SG_ 2563899148 NBICU12_Cell01Volt "Cell01Volt单体01电压值";
CM_ SG_ 2563899148 NBICU12_Cell02Volt "Cell02Volt单体02电压值";
CM_ SG_ 2563899148 NBICU12_Cell03Volt "Cell03Volt单体03电压值";
CM_ SG_ 2563899148 NBICU12_Cell04Volt "Cell04Volt单体04电压值";
CM_ BO_ 2563964684 "NBICU12 Tx and Cell Voltage02";
CM_ SG_ 2563964684 NBICU12_Cell05Volt "Cell05Volt单体05电压值";
CM_ SG_ 2563964684 NBICU12_Cell06Volt "Cell06Volt单体06电压值";
CM_ SG_ 2563964684 NBICU12_Cell07Volt "Cell07Volt单体07电压值";
CM_ SG_ 2563964684 NBICU12_Cell08Volt "Cell08Volt单体08电压值";
CM_ BO_ 2564030220 "NBICU12 Tx and Cell Voltage03";
CM_ SG_ 2564030220 NBICU12_Cell09Volt "Cell09Volt单体09电压值";
CM_ SG_ 2564030220 NBICU12_Cell10Volt "Cell10Volt单体10电压值";
CM_ SG_ 2564030220 NBICU12_Cell11Volt "Cell11Volt单体11电压值";
CM_ SG_ 2564030220 NBICU12_Cell12Volt "Cell12Volt单体12电压值";
CM_ BO_ 2564095756 "NBICU12 Tx and Cell Voltage04";
CM_ SG_ 2564095756 NBICU12_Cell13Volt "Cell13Volt单体13电压值";
CM_ SG_ 2564095756 NBICU12_Cell14Volt "Cell14Volt单体14电压值";
CM_ SG_ 2564095756 NBICU12_Cell15Volt "Cell15Volt单体15电压值";
CM_ SG_ 2564095756 NBICU12_Cell16Volt "Cell16Volt单体16电压值";
CM_ BO_ 2564161292 "NBICU12 Tx and Cell Voltage05";
CM_ SG_ 2564161292 NBICU12_Cell17Volt "Cell17Volt单体17电压值";
CM_ SG_ 2564161292 NBICU12_Cell18Volt "Cell18Volt单体18电压值";
CM_ SG_ 2564161292 NBICU12_Cell19Volt "Cell19Volt单体19电压值";
CM_ SG_ 2564161292 NBICU12_Cell20Volt "Cell20Volt单体20电压值";
CM_ BO_ 2564226828 "NBICU12 Tx and Cell Voltage06";
CM_ SG_ 2564226828 NBICU12_Cell21Volt "Cell21Volt单体21电压值";
CM_ SG_ 2564226828 NBICU12_Cell22Volt "Cell22Volt单体22电压值";
CM_ SG_ 2564226828 NBICU12_Cell23Volt "Cell23Volt单体23电压值";
CM_ SG_ 2564226828 NBICU12_Cell24Volt "Cell24Volt单体24电压值";
CM_ BO_ 2564292364 "NBICU12 Tx and Cell Voltage07";
CM_ SG_ 2564292364 NBICU12_Cell25Volt "Cell25Volt单体25电压值";
CM_ SG_ 2564292364 NBICU12_Cell26Volt "Cell26Volt单体26电压值";
CM_ SG_ 2564292364 NBICU12_Cell27Volt "Cell27Volt单体27电压值";
CM_ SG_ 2564292364 NBICU12_Cell28Volt "Cell28Volt单体28电压值";
CM_ BO_ 2564357900 "NBICU12 Tx and Cell Voltage08";
CM_ SG_ 2564357900 NBICU12_Cell29Volt "Cell29Volt单体29电压值";
CM_ SG_ 2564357900 NBICU12_Cell30Volt "Cell30Volt单体30电压值";
CM_ SG_ 2564357900 NBICU12_Cell31Volt "Cell31Volt单体31电压值";
CM_ SG_ 2564357900 NBICU12_Cell32Volt "Cell32Volt单体32电压值";
CM_ BO_ 2564423436 "NBICU12 Tx and Cell Voltage09";
CM_ SG_ 2564423436 NBICU12_Cell33Volt "Cell33Volt单体33电压值";
CM_ SG_ 2564423436 NBICU12_Cell34Volt "Cell34Volt单体34电压值";
CM_ SG_ 2564423436 NBICU12_Cell35Volt "Cell35Volt单体35电压值";
CM_ SG_ 2564423436 NBICU12_Cell36Volt "Cell36Volt单体36电压值";
CM_ BO_ 2564488972 "NBICU12 Tx and Cell Temp01";
CM_ SG_ 2564488972 NBICU12_Temp01 "NTC01-温度值";
CM_ SG_ 2564488972 NBICU12_Temp02 "NTC02-温度值";
CM_ SG_ 2564488972 NBICU12_Temp03 "NTC03-温度值";
CM_ SG_ 2564488972 NBICU12_Temp04 "NTC04-温度值";
CM_ SG_ 2564488972 NBICU12_Temp05 "NTC05-温度值";
CM_ SG_ 2564488972 NBICU12_Temp06 "NTC06-温度值";
CM_ SG_ 2564488972 NBICU12_Temp07 "NTC07-温度值";
CM_ SG_ 2564488972 NBICU12_Temp08 "NTC08-温度值";
CM_ BO_ 2564554508 "NBICU12 Tx and Cell Temp02";
CM_ SG_ 2564554508 NBICU12_Temp09 "NTC09-温度值";
CM_ SG_ 2564554508 NBICU12_Temp10 "NTC10-温度值";
CM_ SG_ 2564554508 NBICU12_Temp11 "NTC11-温度值";
CM_ SG_ 2564554508 NBICU12_Temp12 "NTC12-温度值";
CM_ SG_ 2564554508 NBICU12_Temp13 "NTC13-温度值";
CM_ SG_ 2564554508 NBICU12_Temp14 "NTC14-温度值";
CM_ SG_ 2564554508 NBICU12_Temp15 "NTC15-温度值";
CM_ SG_ 2564554508 NBICU12_Temp16 "NTC16-温度值";
CM_ BO_ 2564620044 "NBICU12 Tx and Cell Temp03";
CM_ SG_ 2564620044 NBICU12_Temp17 "NTC17-温度值";
CM_ SG_ 2564620044 NBICU12_Temp18 "NTC18-温度值";
CM_ SG_ 2564620044 NBICU12_Temp19 "NTC19-温度值";
CM_ SG_ 2564620044 NBICU12_Temp20 "NTC20-温度值";
CM_ SG_ 2564620044 NBICU12_Temp21 "NTC21-温度值";
CM_ SG_ 2564620044 NBICU12_Temp22 "NTC22-温度值";
CM_ SG_ 2564620044 NBICU12_Temp23 "NTC23-温度值";
CM_ SG_ 2564620044 NBICU12_Temp24 "NTC24-温度值";
CM_ BO_ 2564685580 "NBICU12 Tx and Cell Temp04";
CM_ SG_ 2564685580 NBICU12_Temp25 "NTC25-温度值";
CM_ SG_ 2564685580 NBICU12_Temp26 "NTC26-温度值";
CM_ SG_ 2564685580 NBICU12_Temp27 "NTC27-温度值";
CM_ SG_ 2564685580 NBICU12_Temp28 "NTC28-温度值";
CM_ SG_ 2564685580 NBICU12_Temp29 "NTC29-温度值";
CM_ SG_ 2564685580 NBICU12_Temp30 "NTC30-温度值";
CM_ SG_ 2564685580 NBICU12_Temp31 "NTC31-温度值";
CM_ SG_ 2564685580 NBICU12_Temp32 "NTC32-温度值";
CM_ BO_ 2564751116 "NBICU12 Tx and Cell Temp05";
CM_ SG_ 2564751116 NBICU12_Temp33 "NTC33-温度值";
CM_ SG_ 2564751116 NBICU12_Temp34 "NTC34-温度值";
CM_ SG_ 2564751116 NBICU12_Temp35 "NTC35-温度值";
CM_ SG_ 2564751116 NBICU12_Temp36 "NTC36-温度值";
CM_ BO_ 2564947724 "NBICU12 Tx and Software";
CM_ SG_ 2564947724 NBICU12_NBCMU_Addr_SW "NBICU12 NBCMU Address
NBICU12接收NBCMU地址";
CM_ SG_ 2564947724 NBICU12_SW01 "NBICU12 Software Byte 01
NBICU12软件版本第01字节";
CM_ SG_ 2564947724 NBICU12_SW02 "NBICU12 Software Byte 02
NBICU12软件版本第02字节";
CM_ SG_ 2564947724 NBICU12_SW03 "NBICU12 Software Byte 03
NBICU12软件版本第03字节";
CM_ SG_ 2564947724 NBICU12_SW04 "NBICU12 Software Byte 04
NBICU12软件版本第04字节";
CM_ SG_ 2564947724 NBICU12_SW05 "NBICU12 Software Byte 05
NBICU12软件版本第05字节";
CM_ SG_ 2564947724 NBICU12_SW06 "NBICU12 Software Byte 06
NBICU12软件版本第06字节";
CM_ SG_ 2564947724 NBICU12_SW07 "NBICU12 Software Byte 07
NBICU12软件版本第07字节";
CM_ BO_ 2565013260 "NBICU12 Tx and Hardware";
CM_ SG_ 2565013260 NBICU12_NBCMU_Addr_HW "NBICU12 NBCMU Address
NBICU12接收NBCMU地址";
CM_ SG_ 2565013260 NBICU12_HW01 "NBICU12 Hardware Byte 01
NBICU12硬件版本第01字节";
CM_ SG_ 2565013260 NBICU12_HW02 "NBICU12 Hardware Byte 02
NBICU12硬件版本第02字节";
CM_ SG_ 2565013260 NBICU12_HW03 "NBICU12 Hardware Byte 03
NBICU12硬件版本第03字节";
CM_ SG_ 2565013260 NBICU12_HW04 "NBICU12 Hardware Byte 04
NBICU12硬件版本第04字节";
CM_ SG_ 2565013260 NBICU12_HW05 "NBICU12 Hardware Byte 05
NBICU12硬件版本第05字节";
CM_ SG_ 2565013260 NBICU12_HW06 "NBICU12 Hardware Byte 06
NBICU12硬件版本第06字节";
CM_ SG_ 2565013260 NBICU12_HW07 "NBICU12 Hardware Byte 07
NBICU12硬件版本第07字节";
CM_ BO_ 2564677388 "NBICU12 Tx and DiaResponse";
CM_ BO_ 2562785057 "SBICU01 Tx and Run State";
CM_ SG_ 2562785057 SBICU01_Address "Address
SBICU01地址";
CM_ SG_ 2562785057 SBICU01_TempNum "TempNum
配置温度采集个数";
CM_ SG_ 2562785057 SBICU01_CellTemp_HighWarning "SBICU01高温报警";
CM_ SG_ 2562785057 SBICU01_AddrInput_State "Addr Input_State
检测地址状态";
CM_ SG_ 2562785057 SBICU01_AddrOutput_State "PWM Duty Input
输出地址状态";
CM_ SG_ 2562785057 SBICU01_SoftVer "SoftVer
软件版本";
CM_ SG_ 2562785057 SBICU01_HardVer "HardVer
硬件版本";
CM_ SG_ 2562785057 SBICU01_RunAlivCoun "AliveCounter
心跳指数";
CM_ BO_ 2562916129 "SBICU01 Tx and TempExtremeInfo";
CM_ SG_ 2562916129 SBICU01_CellTempMax "最高温度";
CM_ SG_ 2562916129 SBICU01_CellTempMin "最低温度";
CM_ SG_ 2562916129 SBICU01_CellTempAvg "平均温度";
CM_ SG_ 2562916129 SBICU01_CellTempMaxCode "最高温度序号";
CM_ SG_ 2562916129 SBICU01_CellTempMinCode "最低温度序号";
CM_ SG_ 2562916129 SBICU01_SupplyVolt "供电电压";
CM_ BO_ 2564488993 "SBICU01 Tx and Cell Temp01";
CM_ SG_ 2564488993 SBICU01_Temp01 "NTC01-温度值";
CM_ SG_ 2564488993 SBICU01_Temp02 "NTC02-温度值";
CM_ SG_ 2564488993 SBICU01_Temp03 "NTC03-温度值";
CM_ SG_ 2564488993 SBICU01_Temp04 "NTC04-温度值";
CM_ SG_ 2564488993 SBICU01_Temp05 "NTC05-温度值";
CM_ SG_ 2564488993 SBICU01_Temp06 "NTC06-温度值";
CM_ SG_ 2564488993 SBICU01_Temp07 "NTC07-温度值";
CM_ SG_ 2564488993 SBICU01_Temp08 "NTC08-温度值";
CM_ BO_ 2564554529 "SBICU01 Tx and Cell Temp02";
CM_ SG_ 2564554529 SBICU01_Temp09 "NTC09-温度值";
CM_ SG_ 2564554529 SBICU01_Temp10 "NTC10-温度值";
CM_ SG_ 2564554529 SBICU01_Temp11 "NTC11-温度值";
CM_ SG_ 2564554529 SBICU01_Temp12 "NTC12-温度值";
CM_ SG_ 2564554529 SBICU01_Temp13 "NTC13-温度值";
CM_ SG_ 2564554529 SBICU01_Temp14 "NTC14-温度值";
CM_ SG_ 2564554529 SBICU01_Temp15 "NTC15-温度值";
CM_ SG_ 2564554529 SBICU01_Temp16 "NTC16-温度值";
CM_ BO_ 2564620065 "SBICU01 Tx and Cell Temp03";
CM_ SG_ 2564620065 SBICU01_Temp17 "NTC17-温度值";
CM_ SG_ 2564620065 SBICU01_Temp18 "NTC18-温度值";
CM_ SG_ 2564620065 SBICU01_Temp19 "NTC19-温度值";
CM_ SG_ 2564620065 SBICU01_Temp20 "NTC20-温度值";
CM_ SG_ 2564620065 SBICU01_Temp21 "NTC21-温度值";
CM_ SG_ 2564620065 SBICU01_Temp22 "NTC22-温度值";
CM_ SG_ 2564620065 SBICU01_Temp23 "NTC23-温度值";
CM_ SG_ 2564620065 SBICU01_Temp24 "NTC24-温度值";
CM_ BO_ 2564685601 "SBICU01 Tx and Cell Temp04";
CM_ SG_ 2564685601 SBICU01_Temp25 "NTC25-温度值";
CM_ SG_ 2564685601 SBICU01_Temp26 "NTC26-温度值";
CM_ SG_ 2564685601 SBICU01_Temp27 "NTC27-温度值";
CM_ SG_ 2564685601 SBICU01_Temp28 "NTC28-温度值";
CM_ SG_ 2564685601 SBICU01_Temp29 "NTC29-温度值";
CM_ SG_ 2564685601 SBICU01_Temp30 "NTC30-温度值";
CM_ SG_ 2564685601 SBICU01_Temp31 "NTC31-温度值";
CM_ SG_ 2564685601 SBICU01_Temp32 "NTC32-温度值";
CM_ BO_ 2564751137 "SBICU01 Tx and Cell Temp05";
CM_ SG_ 2564751137 SBICU01_Temp33 "NTC33-温度值";
CM_ SG_ 2564751137 SBICU01_Temp34 "NTC34-温度值";
CM_ SG_ 2564751137 SBICU01_Temp35 "NTC35-温度值";
CM_ SG_ 2564751137 SBICU01_Temp36 "NTC36-温度值";
CM_ BO_ 2564947745 "SBICU01 Tx and Software";
CM_ SG_ 2564947745 SBICU01_NBCMU_Addr_SW "SBICU01 SBCMU Address
SBICU01接收SBCMU地址";
CM_ SG_ 2564947745 SBICU01_SW01 "SBICU01 Software Byte 01
SBICU01软件版本第01字节";
CM_ SG_ 2564947745 SBICU01_SW02 "SBICU01 Software Byte 02
SBICU01软件版本第02字节";
CM_ SG_ 2564947745 SBICU01_SW03 "SBICU01 Software Byte 03
SBICU01软件版本第03字节";
CM_ SG_ 2564947745 SBICU01_SW04 "SBICU01 Software Byte 04
SBICU01软件版本第04字节";
CM_ SG_ 2564947745 SBICU01_SW05 "SBICU01 Software Byte 05
SBICU01软件版本第05字节";
CM_ SG_ 2564947745 SBICU01_SW06 "SBICU01 Software Byte 06
SBICU01软件版本第06字节";
CM_ SG_ 2564947745 SBICU01_SW07 "SBICU01 Software Byte 07
SBICU01软件版本第07字节";
CM_ BO_ 2565013281 "SBICU01 Tx and Hardware";
CM_ SG_ 2565013281 SBICU01_NBCMU_Addr_HW "SBICU01 SBCMU Address
SBICU01接收SBCMU地址";
CM_ SG_ 2565013281 SBICU01_HW01 "SBICU01 Hardware Byte 01
SBICU01硬件版本第01字节";
CM_ SG_ 2565013281 SBICU01_HW02 "SBICU01 Hardware Byte 02
SBICU01硬件版本第02字节";
CM_ SG_ 2565013281 SBICU01_HW03 "SBICU01 Hardware Byte 03
SBICU01硬件版本第03字节";
CM_ SG_ 2565013281 SBICU01_HW04 "SBICU01 Hardware Byte 04
SBICU01硬件版本第04字节";
CM_ SG_ 2565013281 SBICU01_HW05 "SBICU01 Hardware Byte 05
SBICU01硬件版本第05字节";
CM_ SG_ 2565013281 SBICU01_HW06 "SBICU01 Hardware Byte 06
SBICU01硬件版本第06字节";
CM_ SG_ 2565013281 SBICU01_HW07 "SBICU01 Hardware Byte 07
SBICU01硬件版本第07字节";
CM_ BO_ 2564677409 "SBICU01 Tx and DiaResponse";
CM_ BO_ 2562785058 "SBICU02 Tx and Run State";
CM_ SG_ 2562785058 SBICU02_Address "Address
SBICU02地址";
CM_ SG_ 2562785058 SBICU02_TempNum "TempNum
配置温度采集个数";
CM_ SG_ 2562785058 SBICU02_CellTemp_HighWarning "SBICU02高温报警";
CM_ SG_ 2562785058 SBICU02_AddrInput_State "Addr Input_State
检测地址状态";
CM_ SG_ 2562785058 SBICU02_AddrOutput_State "PWM Duty Input
输出地址状态";
CM_ SG_ 2562785058 SBICU02_SoftVer "SoftVer
软件版本";
CM_ SG_ 2562785058 SBICU02_HardVer "HardVer
硬件版本";
CM_ SG_ 2562785058 SBICU02_RunAlivCoun "AliveCounter
心跳指数";
CM_ BO_ 2562916130 "SBICU02 Tx and TempExtremeInfo";
CM_ SG_ 2562916130 SBICU02_CellTempMax "最高温度";
CM_ SG_ 2562916130 SBICU02_CellTempMin "最低温度";
CM_ SG_ 2562916130 SBICU02_CellTempAvg "平均温度";
CM_ SG_ 2562916130 SBICU02_CellTempMaxCode "最高温度序号";
CM_ SG_ 2562916130 SBICU02_CellTempMinCode "最低温度序号";
CM_ SG_ 2562916130 SBICU02_SupplyVolt "供电电压";
CM_ BO_ 2564488994 "SBICU02 Tx and Cell Temp01";
CM_ SG_ 2564488994 SBICU02_Temp01 "NTC01-温度值";
CM_ SG_ 2564488994 SBICU02_Temp02 "NTC02-温度值";
CM_ SG_ 2564488994 SBICU02_Temp03 "NTC03-温度值";
CM_ SG_ 2564488994 SBICU02_Temp04 "NTC04-温度值";
CM_ SG_ 2564488994 SBICU02_Temp05 "NTC05-温度值";
CM_ SG_ 2564488994 SBICU02_Temp06 "NTC06-温度值";
CM_ SG_ 2564488994 SBICU02_Temp07 "NTC07-温度值";
CM_ SG_ 2564488994 SBICU02_Temp08 "NTC08-温度值";
CM_ BO_ 2564554530 "SBICU02 Tx and Cell Temp02";
CM_ SG_ 2564554530 SBICU02_Temp09 "NTC09-温度值";
CM_ SG_ 2564554530 SBICU02_Temp10 "NTC10-温度值";
CM_ SG_ 2564554530 SBICU02_Temp11 "NTC11-温度值";
CM_ SG_ 2564554530 SBICU02_Temp12 "NTC12-温度值";
CM_ SG_ 2564554530 SBICU02_Temp13 "NTC13-温度值";
CM_ SG_ 2564554530 SBICU02_Temp14 "NTC14-温度值";
CM_ SG_ 2564554530 SBICU02_Temp15 "NTC15-温度值";
CM_ SG_ 2564554530 SBICU02_Temp16 "NTC16-温度值";
CM_ BO_ 2564620066 "SBICU02 Tx and Cell Temp03";
CM_ SG_ 2564620066 SBICU02_Temp17 "NTC17-温度值";
CM_ SG_ 2564620066 SBICU02_Temp18 "NTC18-温度值";
CM_ SG_ 2564620066 SBICU02_Temp19 "NTC19-温度值";
CM_ SG_ 2564620066 SBICU02_Temp20 "NTC20-温度值";
CM_ SG_ 2564620066 SBICU02_Temp21 "NTC21-温度值";
CM_ SG_ 2564620066 SBICU02_Temp22 "NTC22-温度值";
CM_ SG_ 2564620066 SBICU02_Temp23 "NTC23-温度值";
CM_ SG_ 2564620066 SBICU02_Temp24 "NTC24-温度值";
CM_ BO_ 2564685602 "SBICU02 Tx and Cell Temp04";
CM_ SG_ 2564685602 SBICU02_Temp25 "NTC25-温度值";
CM_ SG_ 2564685602 SBICU02_Temp26 "NTC26-温度值";
CM_ SG_ 2564685602 SBICU02_Temp27 "NTC27-温度值";
CM_ SG_ 2564685602 SBICU02_Temp28 "NTC28-温度值";
CM_ SG_ 2564685602 SBICU02_Temp29 "NTC29-温度值";
CM_ SG_ 2564685602 SBICU02_Temp30 "NTC30-温度值";
CM_ SG_ 2564685602 SBICU02_Temp31 "NTC31-温度值";
CM_ SG_ 2564685602 SBICU02_Temp32 "NTC32-温度值";
CM_ BO_ 2564751138 "SBICU02 Tx and Cell Temp05";
CM_ SG_ 2564751138 SBICU02_Temp33 "NTC33-温度值";
CM_ SG_ 2564751138 SBICU02_Temp34 "NTC34-温度值";
CM_ SG_ 2564751138 SBICU02_Temp35 "NTC35-温度值";
CM_ SG_ 2564751138 SBICU02_Temp36 "NTC36-温度值";
CM_ BO_ 2564947746 "SBICU02 Tx and Software";
CM_ SG_ 2564947746 SBICU02_NBCMU_Addr_SW "SBICU02 SBCMU Address
SBICU02接收SBCMU地址";
CM_ SG_ 2564947746 SBICU02_SW01 "SBICU02 Software Byte 01
SBICU02软件版本第01字节";
CM_ SG_ 2564947746 SBICU02_SW02 "SBICU02 Software Byte 02
SBICU02软件版本第02字节";
CM_ SG_ 2564947746 SBICU02_SW03 "SBICU02 Software Byte 03
SBICU02软件版本第03字节";
CM_ SG_ 2564947746 SBICU02_SW04 "SBICU02 Software Byte 04
SBICU02软件版本第04字节";
CM_ SG_ 2564947746 SBICU02_SW05 "SBICU02 Software Byte 05
SBICU02软件版本第05字节";
CM_ SG_ 2564947746 SBICU02_SW06 "SBICU02 Software Byte 06
SBICU02软件版本第06字节";
CM_ SG_ 2564947746 SBICU02_SW07 "SBICU02 Software Byte 07
SBICU02软件版本第07字节";
CM_ BO_ 2565013282 "SBICU02 Tx and Hardware";
CM_ SG_ 2565013282 SBICU02_NBCMU_Addr_HW "SBICU02 SBCMU Address
SBICU02接收SBCMU地址";
CM_ SG_ 2565013282 SBICU02_HW01 "SBICU02 Hardware Byte 01
SBICU02硬件版本第01字节";
CM_ SG_ 2565013282 SBICU02_HW02 "SBICU02 Hardware Byte 02
SBICU02硬件版本第02字节";
CM_ SG_ 2565013282 SBICU02_HW03 "SBICU02 Hardware Byte 03
SBICU02硬件版本第03字节";
CM_ SG_ 2565013282 SBICU02_HW04 "SBICU02 Hardware Byte 04
SBICU02硬件版本第04字节";
CM_ SG_ 2565013282 SBICU02_HW05 "SBICU02 Hardware Byte 05
SBICU02硬件版本第05字节";
CM_ SG_ 2565013282 SBICU02_HW06 "SBICU02 Hardware Byte 06
SBICU02硬件版本第06字节";
CM_ SG_ 2565013282 SBICU02_HW07 "SBICU02 Hardware Byte 07
SBICU02硬件版本第07字节";
CM_ BO_ 2564677410 "SBICU02 Tx and DiaResponse";
CM_ BO_ 2562785059 "SBICU03 Tx and Run State";
CM_ SG_ 2562785059 SBICU03_Address "Address
SBICU03地址";
CM_ SG_ 2562785059 SBICU03_TempNum "TempNum
配置温度采集个数";
CM_ SG_ 2562785059 SBICU03_CellTemp_HighWarning "SBICU03高温报警";
CM_ SG_ 2562785059 SBICU03_AddrInput_State "Addr Input_State
检测地址状态";
CM_ SG_ 2562785059 SBICU03_AddrOutput_State "PWM Duty Input
输出地址状态";
CM_ SG_ 2562785059 SBICU03_SoftVer "SoftVer
软件版本";
CM_ SG_ 2562785059 SBICU03_HardVer "HardVer
硬件版本";
CM_ SG_ 2562785059 SBICU03_RunAlivCoun "AliveCounter
心跳指数";
CM_ BO_ 2562916131 "SBICU03 Tx and TempExtremeInfo";
CM_ SG_ 2562916131 SBICU03_CellTempMax "最高温度";
CM_ SG_ 2562916131 SBICU03_CellTempMin "最低温度";
CM_ SG_ 2562916131 SBICU03_CellTempAvg "平均温度";
CM_ SG_ 2562916131 SBICU03_CellTempMaxCode "最高温度序号";
CM_ SG_ 2562916131 SBICU03_CellTempMinCode "最低温度序号";
CM_ SG_ 2562916131 SBICU03_SupplyVolt "供电电压";
CM_ BO_ 2564488995 "SBICU03 Tx and Cell Temp01";
CM_ SG_ 2564488995 SBICU03_Temp01 "NTC01-温度值";
CM_ SG_ 2564488995 SBICU03_Temp02 "NTC02-温度值";
CM_ SG_ 2564488995 SBICU03_Temp03 "NTC03-温度值";
CM_ SG_ 2564488995 SBICU03_Temp04 "NTC04-温度值";
CM_ SG_ 2564488995 SBICU03_Temp05 "NTC05-温度值";
CM_ SG_ 2564488995 SBICU03_Temp06 "NTC06-温度值";
CM_ SG_ 2564488995 SBICU03_Temp07 "NTC07-温度值";
CM_ SG_ 2564488995 SBICU03_Temp08 "NTC08-温度值";
CM_ BO_ 2564554531 "SBICU03 Tx and Cell Temp02";
CM_ SG_ 2564554531 SBICU03_Temp09 "NTC09-温度值";
CM_ SG_ 2564554531 SBICU03_Temp10 "NTC10-温度值";
CM_ SG_ 2564554531 SBICU03_Temp11 "NTC11-温度值";
CM_ SG_ 2564554531 SBICU03_Temp12 "NTC12-温度值";
CM_ SG_ 2564554531 SBICU03_Temp13 "NTC13-温度值";
CM_ SG_ 2564554531 SBICU03_Temp14 "NTC14-温度值";
CM_ SG_ 2564554531 SBICU03_Temp15 "NTC15-温度值";
CM_ SG_ 2564554531 SBICU03_Temp16 "NTC16-温度值";
CM_ BO_ 2564620067 "SBICU03 Tx and Cell Temp03";
CM_ SG_ 2564620067 SBICU03_Temp17 "NTC17-温度值";
CM_ SG_ 2564620067 SBICU03_Temp18 "NTC18-温度值";
CM_ SG_ 2564620067 SBICU03_Temp19 "NTC19-温度值";
CM_ SG_ 2564620067 SBICU03_Temp20 "NTC20-温度值";
CM_ SG_ 2564620067 SBICU03_Temp21 "NTC21-温度值";
CM_ SG_ 2564620067 SBICU03_Temp22 "NTC22-温度值";
CM_ SG_ 2564620067 SBICU03_Temp23 "NTC23-温度值";
CM_ SG_ 2564620067 SBICU03_Temp24 "NTC24-温度值";
CM_ BO_ 2564685603 "SBICU03 Tx and Cell Temp04";
CM_ SG_ 2564685603 SBICU03_Temp25 "NTC25-温度值";
CM_ SG_ 2564685603 SBICU03_Temp26 "NTC26-温度值";
CM_ SG_ 2564685603 SBICU03_Temp27 "NTC27-温度值";
CM_ SG_ 2564685603 SBICU03_Temp28 "NTC28-温度值";
CM_ SG_ 2564685603 SBICU03_Temp29 "NTC29-温度值";
CM_ SG_ 2564685603 SBICU03_Temp30 "NTC30-温度值";
CM_ SG_ 2564685603 SBICU03_Temp31 "NTC31-温度值";
CM_ SG_ 2564685603 SBICU03_Temp32 "NTC32-温度值";
CM_ BO_ 2564751139 "SBICU03 Tx and Cell Temp05";
CM_ SG_ 2564751139 SBICU03_Temp33 "NTC33-温度值";
CM_ SG_ 2564751139 SBICU03_Temp34 "NTC34-温度值";
CM_ SG_ 2564751139 SBICU03_Temp35 "NTC35-温度值";
CM_ SG_ 2564751139 SBICU03_Temp36 "NTC36-温度值";
CM_ BO_ 2564947747 "SBICU03 Tx and Software";
CM_ SG_ 2564947747 SBICU03_NBCMU_Addr_SW "SBICU03 SBCMU Address
SBICU03接收SBCMU地址";
CM_ SG_ 2564947747 SBICU03_SW01 "SBICU03 Software Byte 01
SBICU03软件版本第01字节";
CM_ SG_ 2564947747 SBICU03_SW02 "SBICU03 Software Byte 02
SBICU03软件版本第02字节";
CM_ SG_ 2564947747 SBICU03_SW03 "SBICU03 Software Byte 03
SBICU03软件版本第03字节";
CM_ SG_ 2564947747 SBICU03_SW04 "SBICU03 Software Byte 04
SBICU03软件版本第04字节";
CM_ SG_ 2564947747 SBICU03_SW05 "SBICU03 Software Byte 05
SBICU03软件版本第05字节";
CM_ SG_ 2564947747 SBICU03_SW06 "SBICU03 Software Byte 06
SBICU03软件版本第06字节";
CM_ SG_ 2564947747 SBICU03_SW07 "SBICU03 Software Byte 07
SBICU03软件版本第07字节";
CM_ BO_ 2565013283 "SBICU03 Tx and Hardware";
CM_ SG_ 2565013283 SBICU03_NBCMU_Addr_HW "SBICU03 SBCMU Address
SBICU03接收SBCMU地址";
CM_ SG_ 2565013283 SBICU03_HW01 "SBICU03 Hardware Byte 01
SBICU03硬件版本第01字节";
CM_ SG_ 2565013283 SBICU03_HW02 "SBICU03 Hardware Byte 02
SBICU03硬件版本第02字节";
CM_ SG_ 2565013283 SBICU03_HW03 "SBICU03 Hardware Byte 03
SBICU03硬件版本第03字节";
CM_ SG_ 2565013283 SBICU03_HW04 "SBICU03 Hardware Byte 04
SBICU03硬件版本第04字节";
CM_ SG_ 2565013283 SBICU03_HW05 "SBICU03 Hardware Byte 05
SBICU03硬件版本第05字节";
CM_ SG_ 2565013283 SBICU03_HW06 "SBICU03 Hardware Byte 06
SBICU03硬件版本第06字节";
CM_ SG_ 2565013283 SBICU03_HW07 "SBICU03 Hardware Byte 07
SBICU03硬件版本第07字节";
CM_ BO_ 2564677411 "SBICU03 Tx and DiaResponse";
CM_ BO_ 2562785060 "SBICU04 Tx and Run State";
CM_ SG_ 2562785060 SBICU04_Address "Address
SBICU04地址";
CM_ SG_ 2562785060 SBICU04_TempNum "TempNum
配置温度采集个数";
CM_ SG_ 2562785060 SBICU04_CellTemp_HighWarning "SBICU04高温报警";
CM_ SG_ 2562785060 SBICU04_AddrInput_State "Addr Input_State
检测地址状态";
CM_ SG_ 2562785060 SBICU04_AddrOutput_State "PWM Duty Input
输出地址状态";
CM_ SG_ 2562785060 SBICU04_SoftVer "SoftVer
软件版本";
CM_ SG_ 2562785060 SBICU04_HardVer "HardVer
硬件版本";
CM_ SG_ 2562785060 SBICU04_RunAlivCoun "AliveCounter
心跳指数";
CM_ BO_ 2562916132 "SBICU04 Tx and TempExtremeInfo";
CM_ SG_ 2562916132 SBICU04_CellTempMax "最高温度";
CM_ SG_ 2562916132 SBICU04_CellTempMin "最低温度";
CM_ SG_ 2562916132 SBICU04_CellTempAvg "平均温度";
CM_ SG_ 2562916132 SBICU04_CellTempMaxCode "最高温度序号";
CM_ SG_ 2562916132 SBICU04_CellTempMinCode "最低温度序号";
CM_ SG_ 2562916132 SBICU04_SupplyVolt "供电电压";
CM_ BO_ 2564488996 "SBICU04 Tx and Cell Temp01";
CM_ SG_ 2564488996 SBICU04_Temp01 "NTC01-温度值";
CM_ SG_ 2564488996 SBICU04_Temp02 "NTC02-温度值";
CM_ SG_ 2564488996 SBICU04_Temp03 "NTC03-温度值";
CM_ SG_ 2564488996 SBICU04_Temp04 "NTC04-温度值";
CM_ SG_ 2564488996 SBICU04_Temp05 "NTC05-温度值";
CM_ SG_ 2564488996 SBICU04_Temp06 "NTC06-温度值";
CM_ SG_ 2564488996 SBICU04_Temp07 "NTC07-温度值";
CM_ SG_ 2564488996 SBICU04_Temp08 "NTC08-温度值";
CM_ BO_ 2564554532 "SBICU04 Tx and Cell Temp02";
CM_ SG_ 2564554532 SBICU04_Temp09 "NTC09-温度值";
CM_ SG_ 2564554532 SBICU04_Temp10 "NTC10-温度值";
CM_ SG_ 2564554532 SBICU04_Temp11 "NTC11-温度值";
CM_ SG_ 2564554532 SBICU04_Temp12 "NTC12-温度值";
CM_ SG_ 2564554532 SBICU04_Temp13 "NTC13-温度值";
CM_ SG_ 2564554532 SBICU04_Temp14 "NTC14-温度值";
CM_ SG_ 2564554532 SBICU04_Temp15 "NTC15-温度值";
CM_ SG_ 2564554532 SBICU04_Temp16 "NTC16-温度值";
CM_ BO_ 2564620068 "SBICU04 Tx and Cell Temp03";
CM_ SG_ 2564620068 SBICU04_Temp17 "NTC17-温度值";
CM_ SG_ 2564620068 SBICU04_Temp18 "NTC18-温度值";
CM_ SG_ 2564620068 SBICU04_Temp19 "NTC19-温度值";
CM_ SG_ 2564620068 SBICU04_Temp20 "NTC20-温度值";
CM_ SG_ 2564620068 SBICU04_Temp21 "NTC21-温度值";
CM_ SG_ 2564620068 SBICU04_Temp22 "NTC22-温度值";
CM_ SG_ 2564620068 SBICU04_Temp23 "NTC23-温度值";
CM_ SG_ 2564620068 SBICU04_Temp24 "NTC24-温度值";
CM_ BO_ 2564685604 "SBICU04 Tx and Cell Temp04";
CM_ SG_ 2564685604 SBICU04_Temp25 "NTC25-温度值";
CM_ SG_ 2564685604 SBICU04_Temp26 "NTC26-温度值";
CM_ SG_ 2564685604 SBICU04_Temp27 "NTC27-温度值";
CM_ SG_ 2564685604 SBICU04_Temp28 "NTC28-温度值";
CM_ SG_ 2564685604 SBICU04_Temp29 "NTC29-温度值";
CM_ SG_ 2564685604 SBICU04_Temp30 "NTC30-温度值";
CM_ SG_ 2564685604 SBICU04_Temp31 "NTC31-温度值";
CM_ SG_ 2564685604 SBICU04_Temp32 "NTC32-温度值";
CM_ BO_ 2564751140 "SBICU04 Tx and Cell Temp05";
CM_ SG_ 2564751140 SBICU04_Temp33 "NTC33-温度值";
CM_ SG_ 2564751140 SBICU04_Temp34 "NTC34-温度值";
CM_ SG_ 2564751140 SBICU04_Temp35 "NTC35-温度值";
CM_ SG_ 2564751140 SBICU04_Temp36 "NTC36-温度值";
CM_ BO_ 2564947748 "SBICU04 Tx and Software";
CM_ SG_ 2564947748 SBICU04_NBCMU_Addr_SW "SBICU04 SBCMU Address
SBICU04接收SBCMU地址";
CM_ SG_ 2564947748 SBICU04_SW01 "SBICU04 Software Byte 01
SBICU04软件版本第01字节";
CM_ SG_ 2564947748 SBICU04_SW02 "SBICU04 Software Byte 02
SBICU04软件版本第02字节";
CM_ SG_ 2564947748 SBICU04_SW03 "SBICU04 Software Byte 03
SBICU04软件版本第03字节";
CM_ SG_ 2564947748 SBICU04_SW04 "SBICU04 Software Byte 04
SBICU04软件版本第04字节";
CM_ SG_ 2564947748 SBICU04_SW05 "SBICU04 Software Byte 05
SBICU04软件版本第05字节";
CM_ SG_ 2564947748 SBICU04_SW06 "SBICU04 Software Byte 06
SBICU04软件版本第06字节";
CM_ SG_ 2564947748 SBICU04_SW07 "SBICU04 Software Byte 07
SBICU04软件版本第07字节";
CM_ BO_ 2565013284 "SBICU04 Tx and Hardware";
CM_ SG_ 2565013284 SBICU04_NBCMU_Addr_HW "SBICU04 SBCMU Address
SBICU04接收SBCMU地址";
CM_ SG_ 2565013284 SBICU04_HW01 "SBICU04 Hardware Byte 01
SBICU04硬件版本第01字节";
CM_ SG_ 2565013284 SBICU04_HW02 "SBICU04 Hardware Byte 02
SBICU04硬件版本第02字节";
CM_ SG_ 2565013284 SBICU04_HW03 "SBICU04 Hardware Byte 03
SBICU04硬件版本第03字节";
CM_ SG_ 2565013284 SBICU04_HW04 "SBICU04 Hardware Byte 04
SBICU04硬件版本第04字节";
CM_ SG_ 2565013284 SBICU04_HW05 "SBICU04 Hardware Byte 05
SBICU04硬件版本第05字节";
CM_ SG_ 2565013284 SBICU04_HW06 "SBICU04 Hardware Byte 06
SBICU04硬件版本第06字节";
CM_ SG_ 2565013284 SBICU04_HW07 "SBICU04 Hardware Byte 07
SBICU04硬件版本第07字节";
CM_ BO_ 2564677412 "SBICU04 Tx and DiaResponse";
CM_ BO_ 2562785061 "SBICU05 Tx and Run State";
CM_ SG_ 2562785061 SBICU05_Address "Address
SBICU05地址";
CM_ SG_ 2562785061 SBICU05_TempNum "TempNum
配置温度采集个数";
CM_ SG_ 2562785061 SBICU05_CellTemp_HighWarning "SBICU05高温报警";
CM_ SG_ 2562785061 SBICU05_AddrInput_State "Addr Input_State
检测地址状态";
CM_ SG_ 2562785061 SBICU05_AddrOutput_State "PWM Duty Input
输出地址状态";
CM_ SG_ 2562785061 SBICU05_SoftVer "SoftVer
软件版本";
CM_ SG_ 2562785061 SBICU05_HardVer "HardVer
硬件版本";
CM_ SG_ 2562785061 SBICU05_RunAlivCoun "AliveCounter
心跳指数";
CM_ BO_ 2562916133 "SBICU05 Tx and TempExtremeInfo";
CM_ SG_ 2562916133 SBICU05_CellTempMax "最高温度";
CM_ SG_ 2562916133 SBICU05_CellTempMin "最低温度";
CM_ SG_ 2562916133 SBICU05_CellTempAvg "平均温度";
CM_ SG_ 2562916133 SBICU05_CellTempMaxCode "最高温度序号";
CM_ SG_ 2562916133 SBICU05_CellTempMinCode "最低温度序号";
CM_ SG_ 2562916133 SBICU05_SupplyVolt "供电电压";
CM_ BO_ 2564488997 "SBICU05 Tx and Cell Temp01";
CM_ SG_ 2564488997 SBICU05_Temp01 "NTC01-温度值";
CM_ SG_ 2564488997 SBICU05_Temp02 "NTC02-温度值";
CM_ SG_ 2564488997 SBICU05_Temp03 "NTC03-温度值";
CM_ SG_ 2564488997 SBICU05_Temp04 "NTC04-温度值";
CM_ SG_ 2564488997 SBICU05_Temp05 "NTC05-温度值";
CM_ SG_ 2564488997 SBICU05_Temp06 "NTC06-温度值";
CM_ SG_ 2564488997 SBICU05_Temp07 "NTC07-温度值";
CM_ SG_ 2564488997 SBICU05_Temp08 "NTC08-温度值";
CM_ BO_ 2564554533 "SBICU05 Tx and Cell Temp02";
CM_ SG_ 2564554533 SBICU05_Temp09 "NTC09-温度值";
CM_ SG_ 2564554533 SBICU05_Temp10 "NTC10-温度值";
CM_ SG_ 2564554533 SBICU05_Temp11 "NTC11-温度值";
CM_ SG_ 2564554533 SBICU05_Temp12 "NTC12-温度值";
CM_ SG_ 2564554533 SBICU05_Temp13 "NTC13-温度值";
CM_ SG_ 2564554533 SBICU05_Temp14 "NTC14-温度值";
CM_ SG_ 2564554533 SBICU05_Temp15 "NTC15-温度值";
CM_ SG_ 2564554533 SBICU05_Temp16 "NTC16-温度值";
CM_ BO_ 2564620069 "SBICU05 Tx and Cell Temp03";
CM_ SG_ 2564620069 SBICU05_Temp17 "NTC17-温度值";
CM_ SG_ 2564620069 SBICU05_Temp18 "NTC18-温度值";
CM_ SG_ 2564620069 SBICU05_Temp19 "NTC19-温度值";
CM_ SG_ 2564620069 SBICU05_Temp20 "NTC20-温度值";
CM_ SG_ 2564620069 SBICU05_Temp21 "NTC21-温度值";
CM_ SG_ 2564620069 SBICU05_Temp22 "NTC22-温度值";
CM_ SG_ 2564620069 SBICU05_Temp23 "NTC23-温度值";
CM_ SG_ 2564620069 SBICU05_Temp24 "NTC24-温度值";
CM_ BO_ 2564685605 "SBICU05 Tx and Cell Temp04";
CM_ SG_ 2564685605 SBICU05_Temp25 "NTC25-温度值";
CM_ SG_ 2564685605 SBICU05_Temp26 "NTC26-温度值";
CM_ SG_ 2564685605 SBICU05_Temp27 "NTC27-温度值";
CM_ SG_ 2564685605 SBICU05_Temp28 "NTC28-温度值";
CM_ SG_ 2564685605 SBICU05_Temp29 "NTC29-温度值";
CM_ SG_ 2564685605 SBICU05_Temp30 "NTC30-温度值";
CM_ SG_ 2564685605 SBICU05_Temp31 "NTC31-温度值";
CM_ SG_ 2564685605 SBICU05_Temp32 "NTC32-温度值";
CM_ BO_ 2564751141 "SBICU05 Tx and Cell Temp05";
CM_ SG_ 2564751141 SBICU05_Temp33 "NTC33-温度值";
CM_ SG_ 2564751141 SBICU05_Temp34 "NTC34-温度值";
CM_ SG_ 2564751141 SBICU05_Temp35 "NTC35-温度值";
CM_ SG_ 2564751141 SBICU05_Temp36 "NTC36-温度值";
CM_ BO_ 2564947749 "SBICU05 Tx and Software";
CM_ SG_ 2564947749 SBICU05_NBCMU_Addr_SW "SBICU05 SBCMU Address
SBICU05接收SBCMU地址";
CM_ SG_ 2564947749 SBICU05_SW01 "SBICU05 Software Byte 01
SBICU05软件版本第01字节";
CM_ SG_ 2564947749 SBICU05_SW02 "SBICU05 Software Byte 02
SBICU05软件版本第02字节";
CM_ SG_ 2564947749 SBICU05_SW03 "SBICU05 Software Byte 03
SBICU05软件版本第03字节";
CM_ SG_ 2564947749 SBICU05_SW04 "SBICU05 Software Byte 04
SBICU05软件版本第04字节";
CM_ SG_ 2564947749 SBICU05_SW05 "SBICU05 Software Byte 05
SBICU05软件版本第05字节";
CM_ SG_ 2564947749 SBICU05_SW06 "SBICU05 Software Byte 06
SBICU05软件版本第06字节";
CM_ SG_ 2564947749 SBICU05_SW07 "SBICU05 Software Byte 07
SBICU05软件版本第07字节";
CM_ BO_ 2565013285 "SBICU05 Tx and Hardware";
CM_ SG_ 2565013285 SBICU05_NBCMU_Addr_HW "SBICU05 SBCMU Address
SBICU05接收SBCMU地址";
CM_ SG_ 2565013285 SBICU05_HW01 "SBICU05 Hardware Byte 01
SBICU05硬件版本第01字节";
CM_ SG_ 2565013285 SBICU05_HW02 "SBICU05 Hardware Byte 02
SBICU05硬件版本第02字节";
CM_ SG_ 2565013285 SBICU05_HW03 "SBICU05 Hardware Byte 03
SBICU05硬件版本第03字节";
CM_ SG_ 2565013285 SBICU05_HW04 "SBICU05 Hardware Byte 04
SBICU05硬件版本第04字节";
CM_ SG_ 2565013285 SBICU05_HW05 "SBICU05 Hardware Byte 05
SBICU05硬件版本第05字节";
CM_ SG_ 2565013285 SBICU05_HW06 "SBICU05 Hardware Byte 06
SBICU05硬件版本第06字节";
CM_ SG_ 2565013285 SBICU05_HW07 "SBICU05 Hardware Byte 07
SBICU05硬件版本第07字节";
CM_ BO_ 2564677413 "SBICU05 Tx and DiaResponse";
CM_ BO_ 2562785062 "SBICU06 Tx and Run State";
CM_ SG_ 2562785062 SBICU06_Address "Address
SBICU06地址";
CM_ SG_ 2562785062 SBICU06_TempNum "TempNum
配置温度采集个数";
CM_ SG_ 2562785062 SBICU06_CellTemp_HighWarning "SBICU06高温报警";
CM_ SG_ 2562785062 SBICU06_AddrInput_State "Addr Input_State
检测地址状态";
CM_ SG_ 2562785062 SBICU06_AddrOutput_State "PWM Duty Input
输出地址状态";
CM_ SG_ 2562785062 SBICU06_SoftVer "SoftVer
软件版本";
CM_ SG_ 2562785062 SBICU06_HardVer "HardVer
硬件版本";
CM_ SG_ 2562785062 SBICU06_RunAlivCoun "AliveCounter
心跳指数";
CM_ BO_ 2562916134 "SBICU06 Tx and TempExtremeInfo";
CM_ SG_ 2562916134 SBICU06_CellTempMax "最高温度";
CM_ SG_ 2562916134 SBICU06_CellTempMin "最低温度";
CM_ SG_ 2562916134 SBICU06_CellTempAvg "平均温度";
CM_ SG_ 2562916134 SBICU06_CellTempMaxCode "最高温度序号";
CM_ SG_ 2562916134 SBICU06_CellTempMinCode "最低温度序号";
CM_ SG_ 2562916134 SBICU06_SupplyVolt "供电电压";
CM_ BO_ 2564488998 "SBICU06 Tx and Cell Temp01";
CM_ SG_ 2564488998 SBICU06_Temp01 "NTC01-温度值";
CM_ SG_ 2564488998 SBICU06_Temp02 "NTC02-温度值";
CM_ SG_ 2564488998 SBICU06_Temp03 "NTC03-温度值";
CM_ SG_ 2564488998 SBICU06_Temp04 "NTC04-温度值";
CM_ SG_ 2564488998 SBICU06_Temp05 "NTC05-温度值";
CM_ SG_ 2564488998 SBICU06_Temp06 "NTC06-温度值";
CM_ SG_ 2564488998 SBICU06_Temp07 "NTC07-温度值";
CM_ SG_ 2564488998 SBICU06_Temp08 "NTC08-温度值";
CM_ BO_ 2564554534 "SBICU06 Tx and Cell Temp02";
CM_ SG_ 2564554534 SBICU06_Temp09 "NTC09-温度值";
CM_ SG_ 2564554534 SBICU06_Temp10 "NTC10-温度值";
CM_ SG_ 2564554534 SBICU06_Temp11 "NTC11-温度值";
CM_ SG_ 2564554534 SBICU06_Temp12 "NTC12-温度值";
CM_ SG_ 2564554534 SBICU06_Temp13 "NTC13-温度值";
CM_ SG_ 2564554534 SBICU06_Temp14 "NTC14-温度值";
CM_ SG_ 2564554534 SBICU06_Temp15 "NTC15-温度值";
CM_ SG_ 2564554534 SBICU06_Temp16 "NTC16-温度值";
CM_ BO_ 2564620070 "SBICU06 Tx and Cell Temp03";
CM_ SG_ 2564620070 SBICU06_Temp17 "NTC17-温度值";
CM_ SG_ 2564620070 SBICU06_Temp18 "NTC18-温度值";
CM_ SG_ 2564620070 SBICU06_Temp19 "NTC19-温度值";
CM_ SG_ 2564620070 SBICU06_Temp20 "NTC20-温度值";
CM_ SG_ 2564620070 SBICU06_Temp21 "NTC21-温度值";
CM_ SG_ 2564620070 SBICU06_Temp22 "NTC22-温度值";
CM_ SG_ 2564620070 SBICU06_Temp23 "NTC23-温度值";
CM_ SG_ 2564620070 SBICU06_Temp24 "NTC24-温度值";
CM_ BO_ 2564685606 "SBICU06 Tx and Cell Temp04";
CM_ SG_ 2564685606 SBICU06_Temp25 "NTC25-温度值";
CM_ SG_ 2564685606 SBICU06_Temp26 "NTC26-温度值";
CM_ SG_ 2564685606 SBICU06_Temp27 "NTC27-温度值";
CM_ SG_ 2564685606 SBICU06_Temp28 "NTC28-温度值";
CM_ SG_ 2564685606 SBICU06_Temp29 "NTC29-温度值";
CM_ SG_ 2564685606 SBICU06_Temp30 "NTC30-温度值";
CM_ SG_ 2564685606 SBICU06_Temp31 "NTC31-温度值";
CM_ SG_ 2564685606 SBICU06_Temp32 "NTC32-温度值";
CM_ BO_ 2564751142 "SBICU06 Tx and Cell Temp05";
CM_ SG_ 2564751142 SBICU06_Temp33 "NTC33-温度值";
CM_ SG_ 2564751142 SBICU06_Temp34 "NTC34-温度值";
CM_ SG_ 2564751142 SBICU06_Temp35 "NTC35-温度值";
CM_ SG_ 2564751142 SBICU06_Temp36 "NTC36-温度值";
CM_ BO_ 2564947750 "SBICU06 Tx and Software";
CM_ SG_ 2564947750 SBICU06_NBCMU_Addr_SW "SBICU06 SBCMU Address
SBICU06接收SBCMU地址";
CM_ SG_ 2564947750 SBICU06_SW01 "SBICU06 Software Byte 01
SBICU06软件版本第01字节";
CM_ SG_ 2564947750 SBICU06_SW02 "SBICU06 Software Byte 02
SBICU06软件版本第02字节";
CM_ SG_ 2564947750 SBICU06_SW03 "SBICU06 Software Byte 03
SBICU06软件版本第03字节";
CM_ SG_ 2564947750 SBICU06_SW04 "SBICU06 Software Byte 04
SBICU06软件版本第04字节";
CM_ SG_ 2564947750 SBICU06_SW05 "SBICU06 Software Byte 05
SBICU06软件版本第05字节";
CM_ SG_ 2564947750 SBICU06_SW06 "SBICU06 Software Byte 06
SBICU06软件版本第06字节";
CM_ SG_ 2564947750 SBICU06_SW07 "SBICU06 Software Byte 07
SBICU06软件版本第07字节";
CM_ BO_ 2565013286 "SBICU06 Tx and Hardware";
CM_ SG_ 2565013286 SBICU06_NBCMU_Addr_HW "SBICU06 SBCMU Address
SBICU06接收SBCMU地址";
CM_ SG_ 2565013286 SBICU06_HW01 "SBICU06 Hardware Byte 01
SBICU06硬件版本第01字节";
CM_ SG_ 2565013286 SBICU06_HW02 "SBICU06 Hardware Byte 02
SBICU06硬件版本第02字节";
CM_ SG_ 2565013286 SBICU06_HW03 "SBICU06 Hardware Byte 03
SBICU06硬件版本第03字节";
CM_ SG_ 2565013286 SBICU06_HW04 "SBICU06 Hardware Byte 04
SBICU06硬件版本第04字节";
CM_ SG_ 2565013286 SBICU06_HW05 "SBICU06 Hardware Byte 05
SBICU06硬件版本第05字节";
CM_ SG_ 2565013286 SBICU06_HW06 "SBICU06 Hardware Byte 06
SBICU06硬件版本第06字节";
CM_ SG_ 2565013286 SBICU06_HW07 "SBICU06 Hardware Byte 07
SBICU06硬件版本第07字节";
CM_ BO_ 2564677414 "SBICU06 Tx and DiaResponse";
CM_ BO_ 2562785063 "SBICU07 Tx and Run State";
CM_ SG_ 2562785063 SBICU07_Address "Address
SBICU07地址";
CM_ SG_ 2562785063 SBICU07_TempNum "TempNum
配置温度采集个数";
CM_ SG_ 2562785063 SBICU07_CellTemp_HighWarning "SBICU07高温报警";
CM_ SG_ 2562785063 SBICU07_AddrInput_State "Addr Input_State
检测地址状态";
CM_ SG_ 2562785063 SBICU07_AddrOutput_State "PWM Duty Input
输出地址状态";
CM_ SG_ 2562785063 SBICU07_SoftVer "SoftVer
软件版本";
CM_ SG_ 2562785063 SBICU07_HardVer "HardVer
硬件版本";
CM_ SG_ 2562785063 SBICU07_RunAlivCoun "AliveCounter
心跳指数";
CM_ BO_ 2562916135 "SBICU07 Tx and TempExtremeInfo";
CM_ SG_ 2562916135 SBICU07_CellTempMax "最高温度";
CM_ SG_ 2562916135 SBICU07_CellTempMin "最低温度";
CM_ SG_ 2562916135 SBICU07_CellTempAvg "平均温度";
CM_ SG_ 2562916135 SBICU07_CellTempMaxCode "最高温度序号";
CM_ SG_ 2562916135 SBICU07_CellTempMinCode "最低温度序号";
CM_ SG_ 2562916135 SBICU07_SupplyVolt "供电电压";
CM_ BO_ 2564488999 "SBICU07 Tx and Cell Temp01";
CM_ SG_ 2564488999 SBICU07_Temp01 "NTC01-温度值";
CM_ SG_ 2564488999 SBICU07_Temp02 "NTC02-温度值";
CM_ SG_ 2564488999 SBICU07_Temp03 "NTC03-温度值";
CM_ SG_ 2564488999 SBICU07_Temp04 "NTC04-温度值";
CM_ SG_ 2564488999 SBICU07_Temp05 "NTC05-温度值";
CM_ SG_ 2564488999 SBICU07_Temp06 "NTC06-温度值";
CM_ SG_ 2564488999 SBICU07_Temp07 "NTC07-温度值";
CM_ SG_ 2564488999 SBICU07_Temp08 "NTC08-温度值";
CM_ BO_ 2564554535 "SBICU07 Tx and Cell Temp02";
CM_ SG_ 2564554535 SBICU07_Temp09 "NTC09-温度值";
CM_ SG_ 2564554535 SBICU07_Temp10 "NTC10-温度值";
CM_ SG_ 2564554535 SBICU07_Temp11 "NTC11-温度值";
CM_ SG_ 2564554535 SBICU07_Temp12 "NTC12-温度值";
CM_ SG_ 2564554535 SBICU07_Temp13 "NTC13-温度值";
CM_ SG_ 2564554535 SBICU07_Temp14 "NTC14-温度值";
CM_ SG_ 2564554535 SBICU07_Temp15 "NTC15-温度值";
CM_ SG_ 2564554535 SBICU07_Temp16 "NTC16-温度值";
CM_ BO_ 2564620071 "SBICU07 Tx and Cell Temp03";
CM_ SG_ 2564620071 SBICU07_Temp17 "NTC17-温度值";
CM_ SG_ 2564620071 SBICU07_Temp18 "NTC18-温度值";
CM_ SG_ 2564620071 SBICU07_Temp19 "NTC19-温度值";
CM_ SG_ 2564620071 SBICU07_Temp20 "NTC20-温度值";
CM_ SG_ 2564620071 SBICU07_Temp21 "NTC21-温度值";
CM_ SG_ 2564620071 SBICU07_Temp22 "NTC22-温度值";
CM_ SG_ 2564620071 SBICU07_Temp23 "NTC23-温度值";
CM_ SG_ 2564620071 SBICU07_Temp24 "NTC24-温度值";
CM_ BO_ 2564685607 "SBICU07 Tx and Cell Temp04";
CM_ SG_ 2564685607 SBICU07_Temp25 "NTC25-温度值";
CM_ SG_ 2564685607 SBICU07_Temp26 "NTC26-温度值";
CM_ SG_ 2564685607 SBICU07_Temp27 "NTC27-温度值";
CM_ SG_ 2564685607 SBICU07_Temp28 "NTC28-温度值";
CM_ SG_ 2564685607 SBICU07_Temp29 "NTC29-温度值";
CM_ SG_ 2564685607 SBICU07_Temp30 "NTC30-温度值";
CM_ SG_ 2564685607 SBICU07_Temp31 "NTC31-温度值";
CM_ SG_ 2564685607 SBICU07_Temp32 "NTC32-温度值";
CM_ BO_ 2564751143 "SBICU07 Tx and Cell Temp05";
CM_ SG_ 2564751143 SBICU07_Temp33 "NTC33-温度值";
CM_ SG_ 2564751143 SBICU07_Temp34 "NTC34-温度值";
CM_ SG_ 2564751143 SBICU07_Temp35 "NTC35-温度值";
CM_ SG_ 2564751143 SBICU07_Temp36 "NTC36-温度值";
CM_ BO_ 2564947751 "SBICU07 Tx and Software";
CM_ SG_ 2564947751 SBICU07_NBCMU_Addr_SW "SBICU07 SBCMU Address
SBICU07接收SBCMU地址";
CM_ SG_ 2564947751 SBICU07_SW01 "SBICU07 Software Byte 01
SBICU07软件版本第01字节";
CM_ SG_ 2564947751 SBICU07_SW02 "SBICU07 Software Byte 02
SBICU07软件版本第02字节";
CM_ SG_ 2564947751 SBICU07_SW03 "SBICU07 Software Byte 03
SBICU07软件版本第03字节";
CM_ SG_ 2564947751 SBICU07_SW04 "SBICU07 Software Byte 04
SBICU07软件版本第04字节";
CM_ SG_ 2564947751 SBICU07_SW05 "SBICU07 Software Byte 05
SBICU07软件版本第05字节";
CM_ SG_ 2564947751 SBICU07_SW06 "SBICU07 Software Byte 06
SBICU07软件版本第06字节";
CM_ SG_ 2564947751 SBICU07_SW07 "SBICU07 Software Byte 07
SBICU07软件版本第07字节";
CM_ BO_ 2565013287 "SBICU07 Tx and Hardware";
CM_ SG_ 2565013287 SBICU07_NBCMU_Addr_HW "SBICU07 SBCMU Address
SBICU07接收SBCMU地址";
CM_ SG_ 2565013287 SBICU07_HW01 "SBICU07 Hardware Byte 01
SBICU07硬件版本第01字节";
CM_ SG_ 2565013287 SBICU07_HW02 "SBICU07 Hardware Byte 02
SBICU07硬件版本第02字节";
CM_ SG_ 2565013287 SBICU07_HW03 "SBICU07 Hardware Byte 03
SBICU07硬件版本第03字节";
CM_ SG_ 2565013287 SBICU07_HW04 "SBICU07 Hardware Byte 04
SBICU07硬件版本第04字节";
CM_ SG_ 2565013287 SBICU07_HW05 "SBICU07 Hardware Byte 05
SBICU07硬件版本第05字节";
CM_ SG_ 2565013287 SBICU07_HW06 "SBICU07 Hardware Byte 06
SBICU07硬件版本第06字节";
CM_ SG_ 2565013287 SBICU07_HW07 "SBICU07 Hardware Byte 07
SBICU07硬件版本第07字节";
CM_ BO_ 2564677415 "SBICU07 Tx and DiaResponse";
CM_ BO_ 2562785064 "SBICU08 Tx and Run State";
CM_ SG_ 2562785064 SBICU08_Address "Address
SBICU08地址";
CM_ SG_ 2562785064 SBICU08_TempNum "TempNum
配置温度采集个数";
CM_ SG_ 2562785064 SBICU08_CellTemp_HighWarning "SBICU08高温报警";
CM_ SG_ 2562785064 SBICU08_AddrInput_State "Addr Input_State
检测地址状态";
CM_ SG_ 2562785064 SBICU08_AddrOutput_State "PWM Duty Input
输出地址状态";
CM_ SG_ 2562785064 SBICU08_SoftVer "SoftVer
软件版本";
CM_ SG_ 2562785064 SBICU08_HardVer "HardVer
硬件版本";
CM_ SG_ 2562785064 SBICU08_RunAlivCoun "AliveCounter
心跳指数";
CM_ BO_ 2562916136 "SBICU08 Tx and TempExtremeInfo";
CM_ SG_ 2562916136 SBICU08_CellTempMax "最高温度";
CM_ SG_ 2562916136 SBICU08_CellTempMin "最低温度";
CM_ SG_ 2562916136 SBICU08_CellTempAvg "平均温度";
CM_ SG_ 2562916136 SBICU08_CellTempMaxCode "最高温度序号";
CM_ SG_ 2562916136 SBICU08_CellTempMinCode "最低温度序号";
CM_ SG_ 2562916136 SBICU08_SupplyVolt "供电电压";
CM_ BO_ 2564489000 "SBICU08 Tx and Cell Temp01";
CM_ SG_ 2564489000 SBICU08_Temp01 "NTC01-温度值";
CM_ SG_ 2564489000 SBICU08_Temp02 "NTC02-温度值";
CM_ SG_ 2564489000 SBICU08_Temp03 "NTC03-温度值";
CM_ SG_ 2564489000 SBICU08_Temp04 "NTC04-温度值";
CM_ SG_ 2564489000 SBICU08_Temp05 "NTC05-温度值";
CM_ SG_ 2564489000 SBICU08_Temp06 "NTC06-温度值";
CM_ SG_ 2564489000 SBICU08_Temp07 "NTC07-温度值";
CM_ SG_ 2564489000 SBICU08_Temp08 "NTC08-温度值";
CM_ BO_ 2564554536 "SBICU08 Tx and Cell Temp02";
CM_ SG_ 2564554536 SBICU08_Temp09 "NTC09-温度值";
CM_ SG_ 2564554536 SBICU08_Temp10 "NTC10-温度值";
CM_ SG_ 2564554536 SBICU08_Temp11 "NTC11-温度值";
CM_ SG_ 2564554536 SBICU08_Temp12 "NTC12-温度值";
CM_ SG_ 2564554536 SBICU08_Temp13 "NTC13-温度值";
CM_ SG_ 2564554536 SBICU08_Temp14 "NTC14-温度值";
CM_ SG_ 2564554536 SBICU08_Temp15 "NTC15-温度值";
CM_ SG_ 2564554536 SBICU08_Temp16 "NTC16-温度值";
CM_ BO_ 2564620072 "SBICU08 Tx and Cell Temp03";
CM_ SG_ 2564620072 SBICU08_Temp17 "NTC17-温度值";
CM_ SG_ 2564620072 SBICU08_Temp18 "NTC18-温度值";
CM_ SG_ 2564620072 SBICU08_Temp19 "NTC19-温度值";
CM_ SG_ 2564620072 SBICU08_Temp20 "NTC20-温度值";
CM_ SG_ 2564620072 SBICU08_Temp21 "NTC21-温度值";
CM_ SG_ 2564620072 SBICU08_Temp22 "NTC22-温度值";
CM_ SG_ 2564620072 SBICU08_Temp23 "NTC23-温度值";
CM_ SG_ 2564620072 SBICU08_Temp24 "NTC24-温度值";
CM_ BO_ 2564685608 "SBICU08 Tx and Cell Temp04";
CM_ SG_ 2564685608 SBICU08_Temp25 "NTC25-温度值";
CM_ SG_ 2564685608 SBICU08_Temp26 "NTC26-温度值";
CM_ SG_ 2564685608 SBICU08_Temp27 "NTC27-温度值";
CM_ SG_ 2564685608 SBICU08_Temp28 "NTC28-温度值";
CM_ SG_ 2564685608 SBICU08_Temp29 "NTC29-温度值";
CM_ SG_ 2564685608 SBICU08_Temp30 "NTC30-温度值";
CM_ SG_ 2564685608 SBICU08_Temp31 "NTC31-温度值";
CM_ SG_ 2564685608 SBICU08_Temp32 "NTC32-温度值";
CM_ BO_ 2564751144 "SBICU08 Tx and Cell Temp05";
CM_ SG_ 2564751144 SBICU08_Temp33 "NTC33-温度值";
CM_ SG_ 2564751144 SBICU08_Temp34 "NTC34-温度值";
CM_ SG_ 2564751144 SBICU08_Temp35 "NTC35-温度值";
CM_ SG_ 2564751144 SBICU08_Temp36 "NTC36-温度值";
CM_ BO_ 2564947752 "SBICU08 Tx and Software";
CM_ SG_ 2564947752 SBICU08_NBCMU_Addr_SW "SBICU08 SBCMU Address
SBICU08接收SBCMU地址";
CM_ SG_ 2564947752 SBICU08_SW01 "SBICU08 Software Byte 01
SBICU08软件版本第01字节";
CM_ SG_ 2564947752 SBICU08_SW02 "SBICU08 Software Byte 02
SBICU08软件版本第02字节";
CM_ SG_ 2564947752 SBICU08_SW03 "SBICU08 Software Byte 03
SBICU08软件版本第03字节";
CM_ SG_ 2564947752 SBICU08_SW04 "SBICU08 Software Byte 04
SBICU08软件版本第04字节";
CM_ SG_ 2564947752 SBICU08_SW05 "SBICU08 Software Byte 05
SBICU08软件版本第05字节";
CM_ SG_ 2564947752 SBICU08_SW06 "SBICU08 Software Byte 06
SBICU08软件版本第06字节";
CM_ SG_ 2564947752 SBICU08_SW07 "SBICU08 Software Byte 07
SBICU08软件版本第07字节";
CM_ BO_ 2565013288 "SBICU08 Tx and Hardware";
CM_ SG_ 2565013288 SBICU08_NBCMU_Addr_HW "SBICU08 SBCMU Address
SBICU08接收SBCMU地址";
CM_ SG_ 2565013288 SBICU08_HW01 "SBICU08 Hardware Byte 01
SBICU08硬件版本第01字节";
CM_ SG_ 2565013288 SBICU08_HW02 "SBICU08 Hardware Byte 02
SBICU08硬件版本第02字节";
CM_ SG_ 2565013288 SBICU08_HW03 "SBICU08 Hardware Byte 03
SBICU08硬件版本第03字节";
CM_ SG_ 2565013288 SBICU08_HW04 "SBICU08 Hardware Byte 04
SBICU08硬件版本第04字节";
CM_ SG_ 2565013288 SBICU08_HW05 "SBICU08 Hardware Byte 05
SBICU08硬件版本第05字节";
CM_ SG_ 2565013288 SBICU08_HW06 "SBICU08 Hardware Byte 06
SBICU08硬件版本第06字节";
CM_ SG_ 2565013288 SBICU08_HW07 "SBICU08 Hardware Byte 07
SBICU08硬件版本第07字节";
CM_ BO_ 2564677416 "SBICU08 Tx and DiaResponse";
CM_ BO_ 2562785065 "SBICU09 Tx and Run State";
CM_ SG_ 2562785065 SBICU09_Address "Address
SBICU09地址";
CM_ SG_ 2562785065 SBICU09_TempNum "TempNum
配置温度采集个数";
CM_ SG_ 2562785065 SBICU09_CellTemp_HighWarning "SBICU09高温报警";
CM_ SG_ 2562785065 SBICU09_AddrInput_State "Addr Input_State
检测地址状态";
CM_ SG_ 2562785065 SBICU09_AddrOutput_State "PWM Duty Input
输出地址状态";
CM_ SG_ 2562785065 SBICU09_SoftVer "SoftVer
软件版本";
CM_ SG_ 2562785065 SBICU09_HardVer "HardVer
硬件版本";
CM_ SG_ 2562785065 SBICU09_RunAlivCoun "AliveCounter
心跳指数";
CM_ BO_ 2562916137 "SBICU09 Tx and TempExtremeInfo";
CM_ SG_ 2562916137 SBICU09_CellTempMax "最高温度";
CM_ SG_ 2562916137 SBICU09_CellTempMin "最低温度";
CM_ SG_ 2562916137 SBICU09_CellTempAvg "平均温度";
CM_ SG_ 2562916137 SBICU09_CellTempMaxCode "最高温度序号";
CM_ SG_ 2562916137 SBICU09_CellTempMinCode "最低温度序号";
CM_ SG_ 2562916137 SBICU09_SupplyVolt "供电电压";
CM_ BO_ 2564489001 "SBICU09 Tx and Cell Temp01";
CM_ SG_ 2564489001 SBICU09_Temp01 "NTC01-温度值";
CM_ SG_ 2564489001 SBICU09_Temp02 "NTC02-温度值";
CM_ SG_ 2564489001 SBICU09_Temp03 "NTC03-温度值";
CM_ SG_ 2564489001 SBICU09_Temp04 "NTC04-温度值";
CM_ SG_ 2564489001 SBICU09_Temp05 "NTC05-温度值";
CM_ SG_ 2564489001 SBICU09_Temp06 "NTC06-温度值";
CM_ SG_ 2564489001 SBICU09_Temp07 "NTC07-温度值";
CM_ SG_ 2564489001 SBICU09_Temp08 "NTC08-温度值";
CM_ BO_ 2564554537 "SBICU09 Tx and Cell Temp02";
CM_ SG_ 2564554537 SBICU09_Temp09 "NTC09-温度值";
CM_ SG_ 2564554537 SBICU09_Temp10 "NTC10-温度值";
CM_ SG_ 2564554537 SBICU09_Temp11 "NTC11-温度值";
CM_ SG_ 2564554537 SBICU09_Temp12 "NTC12-温度值";
CM_ SG_ 2564554537 SBICU09_Temp13 "NTC13-温度值";
CM_ SG_ 2564554537 SBICU09_Temp14 "NTC14-温度值";
CM_ SG_ 2564554537 SBICU09_Temp15 "NTC15-温度值";
CM_ SG_ 2564554537 SBICU09_Temp16 "NTC16-温度值";
CM_ BO_ 2564620073 "SBICU09 Tx and Cell Temp03";
CM_ SG_ 2564620073 SBICU09_Temp17 "NTC17-温度值";
CM_ SG_ 2564620073 SBICU09_Temp18 "NTC18-温度值";
CM_ SG_ 2564620073 SBICU09_Temp19 "NTC19-温度值";
CM_ SG_ 2564620073 SBICU09_Temp20 "NTC20-温度值";
CM_ SG_ 2564620073 SBICU09_Temp21 "NTC21-温度值";
CM_ SG_ 2564620073 SBICU09_Temp22 "NTC22-温度值";
CM_ SG_ 2564620073 SBICU09_Temp23 "NTC23-温度值";
CM_ SG_ 2564620073 SBICU09_Temp24 "NTC24-温度值";
CM_ BO_ 2564685609 "SBICU09 Tx and Cell Temp04";
CM_ SG_ 2564685609 SBICU09_Temp25 "NTC25-温度值";
CM_ SG_ 2564685609 SBICU09_Temp26 "NTC26-温度值";
CM_ SG_ 2564685609 SBICU09_Temp27 "NTC27-温度值";
CM_ SG_ 2564685609 SBICU09_Temp28 "NTC28-温度值";
CM_ SG_ 2564685609 SBICU09_Temp29 "NTC29-温度值";
CM_ SG_ 2564685609 SBICU09_Temp30 "NTC30-温度值";
CM_ SG_ 2564685609 SBICU09_Temp31 "NTC31-温度值";
CM_ SG_ 2564685609 SBICU09_Temp32 "NTC32-温度值";
CM_ BO_ 2564751145 "SBICU09 Tx and Cell Temp05";
CM_ SG_ 2564751145 SBICU09_Temp33 "NTC33-温度值";
CM_ SG_ 2564751145 SBICU09_Temp34 "NTC34-温度值";
CM_ SG_ 2564751145 SBICU09_Temp35 "NTC35-温度值";
CM_ SG_ 2564751145 SBICU09_Temp36 "NTC36-温度值";
CM_ BO_ 2564947753 "SBICU09 Tx and Software";
CM_ SG_ 2564947753 SBICU09_NBCMU_Addr_SW "SBICU09 SBCMU Address
SBICU09接收SBCMU地址";
CM_ SG_ 2564947753 SBICU09_SW01 "SBICU09 Software Byte 01
SBICU09软件版本第01字节";
CM_ SG_ 2564947753 SBICU09_SW02 "SBICU09 Software Byte 02
SBICU09软件版本第02字节";
CM_ SG_ 2564947753 SBICU09_SW03 "SBICU09 Software Byte 03
SBICU09软件版本第03字节";
CM_ SG_ 2564947753 SBICU09_SW04 "SBICU09 Software Byte 04
SBICU09软件版本第04字节";
CM_ SG_ 2564947753 SBICU09_SW05 "SBICU09 Software Byte 05
SBICU09软件版本第05字节";
CM_ SG_ 2564947753 SBICU09_SW06 "SBICU09 Software Byte 06
SBICU09软件版本第06字节";
CM_ SG_ 2564947753 SBICU09_SW07 "SBICU09 Software Byte 07
SBICU09软件版本第07字节";
CM_ BO_ 2565013289 "SBICU09 Tx and Hardware";
CM_ SG_ 2565013289 SBICU09_NBCMU_Addr_HW "SBICU09 SBCMU Address
SBICU09接收SBCMU地址";
CM_ SG_ 2565013289 SBICU09_HW01 "SBICU09 Hardware Byte 01
SBICU09硬件版本第01字节";
CM_ SG_ 2565013289 SBICU09_HW02 "SBICU09 Hardware Byte 02
SBICU09硬件版本第02字节";
CM_ SG_ 2565013289 SBICU09_HW03 "SBICU09 Hardware Byte 03
SBICU09硬件版本第03字节";
CM_ SG_ 2565013289 SBICU09_HW04 "SBICU09 Hardware Byte 04
SBICU09硬件版本第04字节";
CM_ SG_ 2565013289 SBICU09_HW05 "SBICU09 Hardware Byte 05
SBICU09硬件版本第05字节";
CM_ SG_ 2565013289 SBICU09_HW06 "SBICU09 Hardware Byte 06
SBICU09硬件版本第06字节";
CM_ SG_ 2565013289 SBICU09_HW07 "SBICU09 Hardware Byte 07
SBICU09硬件版本第07字节";
CM_ BO_ 2564677417 "SBICU09 Tx and DiaResponse";
CM_ BO_ 2562785066 "SBICU10 Tx and Run State";
CM_ SG_ 2562785066 SBICU10_Address "Address
SBICU10地址";
CM_ SG_ 2562785066 SBICU10_TempNum "TempNum
配置温度采集个数";
CM_ SG_ 2562785066 SBICU10_CellTemp_HighWarning "SBICU10高温报警";
CM_ SG_ 2562785066 SBICU10_AddrInput_State "Addr Input_State
检测地址状态";
CM_ SG_ 2562785066 SBICU10_AddrOutput_State "PWM Duty Input
输出地址状态";
CM_ SG_ 2562785066 SBICU10_SoftVer "SoftVer
软件版本";
CM_ SG_ 2562785066 SBICU10_HardVer "HardVer
硬件版本";
CM_ SG_ 2562785066 SBICU10_RunAlivCoun "AliveCounter
心跳指数";
CM_ BO_ 2562916138 "SBICU10 Tx and TempExtremeInfo";
CM_ SG_ 2562916138 SBICU10_CellTempMax "最高温度";
CM_ SG_ 2562916138 SBICU10_CellTempMin "最低温度";
CM_ SG_ 2562916138 SBICU10_CellTempAvg "平均温度";
CM_ SG_ 2562916138 SBICU10_CellTempMaxCode "最高温度序号";
CM_ SG_ 2562916138 SBICU10_CellTempMinCode "最低温度序号";
CM_ SG_ 2562916138 SBICU10_SupplyVolt "供电电压";
CM_ BO_ 2564489002 "SBICU10 Tx and Cell Temp01";
CM_ SG_ 2564489002 SBICU10_Temp01 "NTC01-温度值";
CM_ SG_ 2564489002 SBICU10_Temp02 "NTC02-温度值";
CM_ SG_ 2564489002 SBICU10_Temp03 "NTC03-温度值";
CM_ SG_ 2564489002 SBICU10_Temp04 "NTC04-温度值";
CM_ SG_ 2564489002 SBICU10_Temp05 "NTC05-温度值";
CM_ SG_ 2564489002 SBICU10_Temp06 "NTC06-温度值";
CM_ SG_ 2564489002 SBICU10_Temp07 "NTC07-温度值";
CM_ SG_ 2564489002 SBICU10_Temp08 "NTC08-温度值";
CM_ BO_ 2564554538 "SBICU10 Tx and Cell Temp02";
CM_ SG_ 2564554538 SBICU10_Temp09 "NTC09-温度值";
CM_ SG_ 2564554538 SBICU10_Temp10 "NTC10-温度值";
CM_ SG_ 2564554538 SBICU10_Temp11 "NTC11-温度值";
CM_ SG_ 2564554538 SBICU10_Temp12 "NTC12-温度值";
CM_ SG_ 2564554538 SBICU10_Temp13 "NTC13-温度值";
CM_ SG_ 2564554538 SBICU10_Temp14 "NTC14-温度值";
CM_ SG_ 2564554538 SBICU10_Temp15 "NTC15-温度值";
CM_ SG_ 2564554538 SBICU10_Temp16 "NTC16-温度值";
CM_ BO_ 2564620074 "SBICU10 Tx and Cell Temp03";
CM_ SG_ 2564620074 SBICU10_Temp17 "NTC17-温度值";
CM_ SG_ 2564620074 SBICU10_Temp18 "NTC18-温度值";
CM_ SG_ 2564620074 SBICU10_Temp19 "NTC19-温度值";
CM_ SG_ 2564620074 SBICU10_Temp20 "NTC20-温度值";
CM_ SG_ 2564620074 SBICU10_Temp21 "NTC21-温度值";
CM_ SG_ 2564620074 SBICU10_Temp22 "NTC22-温度值";
CM_ SG_ 2564620074 SBICU10_Temp23 "NTC23-温度值";
CM_ SG_ 2564620074 SBICU10_Temp24 "NTC24-温度值";
CM_ BO_ 2564685610 "SBICU10 Tx and Cell Temp04";
CM_ SG_ 2564685610 SBICU10_Temp25 "NTC25-温度值";
CM_ SG_ 2564685610 SBICU10_Temp26 "NTC26-温度值";
CM_ SG_ 2564685610 SBICU10_Temp27 "NTC27-温度值";
CM_ SG_ 2564685610 SBICU10_Temp28 "NTC28-温度值";
CM_ SG_ 2564685610 SBICU10_Temp29 "NTC29-温度值";
CM_ SG_ 2564685610 SBICU10_Temp30 "NTC30-温度值";
CM_ SG_ 2564685610 SBICU10_Temp31 "NTC31-温度值";
CM_ SG_ 2564685610 SBICU10_Temp32 "NTC32-温度值";
CM_ BO_ 2564751146 "SBICU10 Tx and Cell Temp05";
CM_ SG_ 2564751146 SBICU10_Temp33 "NTC33-温度值";
CM_ SG_ 2564751146 SBICU10_Temp34 "NTC34-温度值";
CM_ SG_ 2564751146 SBICU10_Temp35 "NTC35-温度值";
CM_ SG_ 2564751146 SBICU10_Temp36 "NTC36-温度值";
CM_ BO_ 2564947754 "SBICU10 Tx and Software";
CM_ SG_ 2564947754 SBICU10_NBCMU_Addr_SW "SBICU10 SBCMU Address
SBICU10接收SBCMU地址";
CM_ SG_ 2564947754 SBICU10_SW01 "SBICU10 Software Byte 01
SBICU10软件版本第01字节";
CM_ SG_ 2564947754 SBICU10_SW02 "SBICU10 Software Byte 02
SBICU10软件版本第02字节";
CM_ SG_ 2564947754 SBICU10_SW03 "SBICU10 Software Byte 03
SBICU10软件版本第03字节";
CM_ SG_ 2564947754 SBICU10_SW04 "SBICU10 Software Byte 04
SBICU10软件版本第04字节";
CM_ SG_ 2564947754 SBICU10_SW05 "SBICU10 Software Byte 05
SBICU10软件版本第05字节";
CM_ SG_ 2564947754 SBICU10_SW06 "SBICU10 Software Byte 06
SBICU10软件版本第06字节";
CM_ SG_ 2564947754 SBICU10_SW07 "SBICU10 Software Byte 07
SBICU10软件版本第07字节";
CM_ BO_ 2565013290 "SBICU10 Tx and Hardware";
CM_ SG_ 2565013290 SBICU10_NBCMU_Addr_HW "SBICU10 SBCMU Address
SBICU10接收SBCMU地址";
CM_ SG_ 2565013290 SBICU10_HW01 "SBICU10 Hardware Byte 01
SBICU10硬件版本第01字节";
CM_ SG_ 2565013290 SBICU10_HW02 "SBICU10 Hardware Byte 02
SBICU10硬件版本第02字节";
CM_ SG_ 2565013290 SBICU10_HW03 "SBICU10 Hardware Byte 03
SBICU10硬件版本第03字节";
CM_ SG_ 2565013290 SBICU10_HW04 "SBICU10 Hardware Byte 04
SBICU10硬件版本第04字节";
CM_ SG_ 2565013290 SBICU10_HW05 "SBICU10 Hardware Byte 05
SBICU10硬件版本第05字节";
CM_ SG_ 2565013290 SBICU10_HW06 "SBICU10 Hardware Byte 06
SBICU10硬件版本第06字节";
CM_ SG_ 2565013290 SBICU10_HW07 "SBICU10 Hardware Byte 07
SBICU10硬件版本第07字节";
CM_ BO_ 2564677418 "SBICU10 Tx and DiaResponse";
CM_ BO_ 2562785067 "SBICU11 Tx and Run State";
CM_ SG_ 2562785067 SBICU11_Address "Address
SBICU11地址";
CM_ SG_ 2562785067 SBICU11_TempNum "TempNum
配置温度采集个数";
CM_ SG_ 2562785067 SBICU11_CellTemp_HighWarning "SBICU11高温报警";
CM_ SG_ 2562785067 SBICU11_AddrInput_State "Addr Input_State
检测地址状态";
CM_ SG_ 2562785067 SBICU11_AddrOutput_State "PWM Duty Input
输出地址状态";
CM_ SG_ 2562785067 SBICU11_SoftVer "SoftVer
软件版本";
CM_ SG_ 2562785067 SBICU11_HardVer "HardVer
硬件版本";
CM_ SG_ 2562785067 SBICU11_RunAlivCoun "AliveCounter
心跳指数";
CM_ BO_ 2562916139 "SBICU11 Tx and TempExtremeInfo";
CM_ SG_ 2562916139 SBICU11_CellTempMax "最高温度";
CM_ SG_ 2562916139 SBICU11_CellTempMin "最低温度";
CM_ SG_ 2562916139 SBICU11_CellTempAvg "平均温度";
CM_ SG_ 2562916139 SBICU11_CellTempMaxCode "最高温度序号";
CM_ SG_ 2562916139 SBICU11_CellTempMinCode "最低温度序号";
CM_ SG_ 2562916139 SBICU11_SupplyVolt "供电电压";
CM_ BO_ 2564489003 "SBICU11 Tx and Cell Temp01";
CM_ SG_ 2564489003 SBICU11_Temp01 "NTC01-温度值";
CM_ SG_ 2564489003 SBICU11_Temp02 "NTC02-温度值";
CM_ SG_ 2564489003 SBICU11_Temp03 "NTC03-温度值";
CM_ SG_ 2564489003 SBICU11_Temp04 "NTC04-温度值";
CM_ SG_ 2564489003 SBICU11_Temp05 "NTC05-温度值";
CM_ SG_ 2564489003 SBICU11_Temp06 "NTC06-温度值";
CM_ SG_ 2564489003 SBICU11_Temp07 "NTC07-温度值";
CM_ SG_ 2564489003 SBICU11_Temp08 "NTC08-温度值";
CM_ BO_ 2564554539 "SBICU11 Tx and Cell Temp02";
CM_ SG_ 2564554539 SBICU11_Temp09 "NTC09-温度值";
CM_ SG_ 2564554539 SBICU11_Temp10 "NTC10-温度值";
CM_ SG_ 2564554539 SBICU11_Temp11 "NTC11-温度值";
CM_ SG_ 2564554539 SBICU11_Temp12 "NTC12-温度值";
CM_ SG_ 2564554539 SBICU11_Temp13 "NTC13-温度值";
CM_ SG_ 2564554539 SBICU11_Temp14 "NTC14-温度值";
CM_ SG_ 2564554539 SBICU11_Temp15 "NTC15-温度值";
CM_ SG_ 2564554539 SBICU11_Temp16 "NTC16-温度值";
CM_ BO_ 2564620075 "SBICU11 Tx and Cell Temp03";
CM_ SG_ 2564620075 SBICU11_Temp17 "NTC17-温度值";
CM_ SG_ 2564620075 SBICU11_Temp18 "NTC18-温度值";
CM_ SG_ 2564620075 SBICU11_Temp19 "NTC19-温度值";
CM_ SG_ 2564620075 SBICU11_Temp20 "NTC20-温度值";
CM_ SG_ 2564620075 SBICU11_Temp21 "NTC21-温度值";
CM_ SG_ 2564620075 SBICU11_Temp22 "NTC22-温度值";
CM_ SG_ 2564620075 SBICU11_Temp23 "NTC23-温度值";
CM_ SG_ 2564620075 SBICU11_Temp24 "NTC24-温度值";
CM_ BO_ 2564685611 "SBICU11 Tx and Cell Temp04";
CM_ SG_ 2564685611 SBICU11_Temp25 "NTC25-温度值";
CM_ SG_ 2564685611 SBICU11_Temp26 "NTC26-温度值";
CM_ SG_ 2564685611 SBICU11_Temp27 "NTC27-温度值";
CM_ SG_ 2564685611 SBICU11_Temp28 "NTC28-温度值";
CM_ SG_ 2564685611 SBICU11_Temp29 "NTC29-温度值";
CM_ SG_ 2564685611 SBICU11_Temp30 "NTC30-温度值";
CM_ SG_ 2564685611 SBICU11_Temp31 "NTC31-温度值";
CM_ SG_ 2564685611 SBICU11_Temp32 "NTC32-温度值";
CM_ BO_ 2564751147 "SBICU11 Tx and Cell Temp05";
CM_ SG_ 2564751147 SBICU11_Temp33 "NTC33-温度值";
CM_ SG_ 2564751147 SBICU11_Temp34 "NTC34-温度值";
CM_ SG_ 2564751147 SBICU11_Temp35 "NTC35-温度值";
CM_ SG_ 2564751147 SBICU11_Temp36 "NTC36-温度值";
CM_ BO_ 2564947755 "SBICU11 Tx and Software";
CM_ SG_ 2564947755 SBICU11_NBCMU_Addr_SW "SBICU11 SBCMU Address
SBICU11接收SBCMU地址";
CM_ SG_ 2564947755 SBICU11_SW01 "SBICU11 Software Byte 01
SBICU11软件版本第01字节";
CM_ SG_ 2564947755 SBICU11_SW02 "SBICU11 Software Byte 02
SBICU11软件版本第02字节";
CM_ SG_ 2564947755 SBICU11_SW03 "SBICU11 Software Byte 03
SBICU11软件版本第03字节";
CM_ SG_ 2564947755 SBICU11_SW04 "SBICU11 Software Byte 04
SBICU11软件版本第04字节";
CM_ SG_ 2564947755 SBICU11_SW05 "SBICU11 Software Byte 05
SBICU11软件版本第05字节";
CM_ SG_ 2564947755 SBICU11_SW06 "SBICU11 Software Byte 06
SBICU11软件版本第06字节";
CM_ SG_ 2564947755 SBICU11_SW07 "SBICU11 Software Byte 07
SBICU11软件版本第07字节";
CM_ BO_ 2565013291 "SBICU11 Tx and Hardware";
CM_ SG_ 2565013291 SBICU11_NBCMU_Addr_HW "SBICU11 SBCMU Address
SBICU11接收SBCMU地址";
CM_ SG_ 2565013291 SBICU11_HW01 "SBICU11 Hardware Byte 01
SBICU11硬件版本第01字节";
CM_ SG_ 2565013291 SBICU11_HW02 "SBICU11 Hardware Byte 02
SBICU11硬件版本第02字节";
CM_ SG_ 2565013291 SBICU11_HW03 "SBICU11 Hardware Byte 03
SBICU11硬件版本第03字节";
CM_ SG_ 2565013291 SBICU11_HW04 "SBICU11 Hardware Byte 04
SBICU11硬件版本第04字节";
CM_ SG_ 2565013291 SBICU11_HW05 "SBICU11 Hardware Byte 05
SBICU11硬件版本第05字节";
CM_ SG_ 2565013291 SBICU11_HW06 "SBICU11 Hardware Byte 06
SBICU11硬件版本第06字节";
CM_ SG_ 2565013291 SBICU11_HW07 "SBICU11 Hardware Byte 07
SBICU11硬件版本第07字节";
CM_ BO_ 2564677419 "SBICU11 Tx and DiaResponse";
CM_ BO_ 2562785068 "SBICU12 Tx and Run State";
CM_ SG_ 2562785068 SBICU12_Address "Address
SBICU12地址";
CM_ SG_ 2562785068 SBICU12_TempNum "TempNum
配置温度采集个数";
CM_ SG_ 2562785068 SBICU12_CellTemp_HighWarning "SBICU12高温报警";
CM_ SG_ 2562785068 SBICU12_AddrInput_State "Addr Input_State
检测地址状态";
CM_ SG_ 2562785068 SBICU12_AddrOutput_State "PWM Duty Input
输出地址状态";
CM_ SG_ 2562785068 SBICU12_SoftVer "SoftVer
软件版本";
CM_ SG_ 2562785068 SBICU12_HardVer "HardVer
硬件版本";
CM_ SG_ 2562785068 SBICU12_RunAlivCoun "AliveCounter
心跳指数";
CM_ BO_ 2562916140 "SBICU12 Tx and TempExtremeInfo";
CM_ SG_ 2562916140 SBICU12_CellTempMax "最高温度";
CM_ SG_ 2562916140 SBICU12_CellTempMin "最低温度";
CM_ SG_ 2562916140 SBICU12_CellTempAvg "平均温度";
CM_ SG_ 2562916140 SBICU12_CellTempMaxCode "最高温度序号";
CM_ SG_ 2562916140 SBICU12_CellTempMinCode "最低温度序号";
CM_ SG_ 2562916140 SBICU12_SupplyVolt "供电电压";
CM_ BO_ 2564489004 "SBICU12 Tx and Cell Temp01";
CM_ SG_ 2564489004 SBICU12_Temp01 "NTC01-温度值";
CM_ SG_ 2564489004 SBICU12_Temp02 "NTC02-温度值";
CM_ SG_ 2564489004 SBICU12_Temp03 "NTC03-温度值";
CM_ SG_ 2564489004 SBICU12_Temp04 "NTC04-温度值";
CM_ SG_ 2564489004 SBICU12_Temp05 "NTC05-温度值";
CM_ SG_ 2564489004 SBICU12_Temp06 "NTC06-温度值";
CM_ SG_ 2564489004 SBICU12_Temp07 "NTC07-温度值";
CM_ SG_ 2564489004 SBICU12_Temp08 "NTC08-温度值";
CM_ BO_ 2564554540 "SBICU12 Tx and Cell Temp02";
CM_ SG_ 2564554540 SBICU12_Temp09 "NTC09-温度值";
CM_ SG_ 2564554540 SBICU12_Temp10 "NTC10-温度值";
CM_ SG_ 2564554540 SBICU12_Temp11 "NTC11-温度值";
CM_ SG_ 2564554540 SBICU12_Temp12 "NTC12-温度值";
CM_ SG_ 2564554540 SBICU12_Temp13 "NTC13-温度值";
CM_ SG_ 2564554540 SBICU12_Temp14 "NTC14-温度值";
CM_ SG_ 2564554540 SBICU12_Temp15 "NTC15-温度值";
CM_ SG_ 2564554540 SBICU12_Temp16 "NTC16-温度值";
CM_ BO_ 2564620076 "SBICU12 Tx and Cell Temp03";
CM_ SG_ 2564620076 SBICU12_Temp17 "NTC17-温度值";
CM_ SG_ 2564620076 SBICU12_Temp18 "NTC18-温度值";
CM_ SG_ 2564620076 SBICU12_Temp19 "NTC19-温度值";
CM_ SG_ 2564620076 SBICU12_Temp20 "NTC20-温度值";
CM_ SG_ 2564620076 SBICU12_Temp21 "NTC21-温度值";
CM_ SG_ 2564620076 SBICU12_Temp22 "NTC22-温度值";
CM_ SG_ 2564620076 SBICU12_Temp23 "NTC23-温度值";
CM_ SG_ 2564620076 SBICU12_Temp24 "NTC24-温度值";
CM_ BO_ 2564685612 "SBICU12 Tx and Cell Temp04";
CM_ SG_ 2564685612 SBICU12_Temp25 "NTC25-温度值";
CM_ SG_ 2564685612 SBICU12_Temp26 "NTC26-温度值";
CM_ SG_ 2564685612 SBICU12_Temp27 "NTC27-温度值";
CM_ SG_ 2564685612 SBICU12_Temp28 "NTC28-温度值";
CM_ SG_ 2564685612 SBICU12_Temp29 "NTC29-温度值";
CM_ SG_ 2564685612 SBICU12_Temp30 "NTC30-温度值";
CM_ SG_ 2564685612 SBICU12_Temp31 "NTC31-温度值";
CM_ SG_ 2564685612 SBICU12_Temp32 "NTC32-温度值";
CM_ BO_ 2564751148 "SBICU12 Tx and Cell Temp05";
CM_ SG_ 2564751148 SBICU12_Temp33 "NTC33-温度值";
CM_ SG_ 2564751148 SBICU12_Temp34 "NTC34-温度值";
CM_ SG_ 2564751148 SBICU12_Temp35 "NTC35-温度值";
CM_ SG_ 2564751148 SBICU12_Temp36 "NTC36-温度值";
CM_ BO_ 2564947756 "SBICU12 Tx and Software";
CM_ SG_ 2564947756 SBICU12_NBCMU_Addr_SW "SBICU12 SBCMU Address
SBICU12接收SBCMU地址";
CM_ SG_ 2564947756 SBICU12_SW01 "SBICU12 Software Byte 01
SBICU12软件版本第01字节";
CM_ SG_ 2564947756 SBICU12_SW02 "SBICU12 Software Byte 02
SBICU12软件版本第02字节";
CM_ SG_ 2564947756 SBICU12_SW03 "SBICU12 Software Byte 03
SBICU12软件版本第03字节";
CM_ SG_ 2564947756 SBICU12_SW04 "SBICU12 Software Byte 04
SBICU12软件版本第04字节";
CM_ SG_ 2564947756 SBICU12_SW05 "SBICU12 Software Byte 05
SBICU12软件版本第05字节";
CM_ SG_ 2564947756 SBICU12_SW06 "SBICU12 Software Byte 06
SBICU12软件版本第06字节";
CM_ SG_ 2564947756 SBICU12_SW07 "SBICU12 Software Byte 07
SBICU12软件版本第07字节";
CM_ BO_ 2565013292 "SBICU12 Tx and Hardware";
CM_ SG_ 2565013292 SBICU12_NBCMU_Addr_HW "SBICU12 SBCMU Address
SBICU12接收SBCMU地址";
CM_ SG_ 2565013292 SBICU12_HW01 "SBICU12 Hardware Byte 01
SBICU12硬件版本第01字节";
CM_ SG_ 2565013292 SBICU12_HW02 "SBICU12 Hardware Byte 02
SBICU12硬件版本第02字节";
CM_ SG_ 2565013292 SBICU12_HW03 "SBICU12 Hardware Byte 03
SBICU12硬件版本第03字节";
CM_ SG_ 2565013292 SBICU12_HW04 "SBICU12 Hardware Byte 04
SBICU12硬件版本第04字节";
CM_ SG_ 2565013292 SBICU12_HW05 "SBICU12 Hardware Byte 05
SBICU12硬件版本第05字节";
CM_ SG_ 2565013292 SBICU12_HW06 "SBICU12 Hardware Byte 06
SBICU12硬件版本第06字节";
CM_ SG_ 2565013292 SBICU12_HW07 "SBICU12 Hardware Byte 07
SBICU12硬件版本第07字节";
CM_ BO_ 2564677420 "SBICU12 Tx and DiaResponse";
CM_ BO_ 2562129824 "NBCMU Tx and NBICUControl";
CM_ SG_ 2562129824 NBCMU_NBICUSysCurr "SysCurr
系统电流值";
CM_ SG_ 2562129824 NBCMU_SysCellVoltMin "SysCellVoltMin
系统最低单体电压";
CM_ SG_ 2562129824 NBCMU_OnlineNBICUnum "OnlineNBICUnum
识别在线从NBICU总数";
CM_ SG_ 2562129824 NBCMU_NBICU_Address "NBCMU NBICU Address
NBCMU发给NBICU地址";
CM_ BO_ 2561736609 "NBCMU Tx and Run State";
CM_ SG_ 2561736609 NBCMU01_Address "NBCMU_Address有效地址";
CM_ SG_ 2561736609 NBCMU01_NBICUnum "NBICUnum
配置电池包管理单元总数";
CM_ SG_ 2561736609 NBCMU01_SysCurr "SysCurr
系统电流值";
CM_ SG_ 2561736609 NBCMU01_Contactor_state_Negative "Negative contactor state
主负继电器状态";
CM_ SG_ 2561736609 NBCMU01_Contactor_state_Positive "Positive contactor state
主正继电器状态";
CM_ SG_ 2561736609 NBCMU01_Contactor_state_PreChrg "Precharge contactor state
预充继电器状态";
CM_ SG_ 2561736609 NBCMU01_Contactor_state_Heat "Heat contactor state
加热继电器状态";
CM_ SG_ 2561736609 NBCMU01_WorkState "Work State
工作状态";
CM_ SG_ 2561736609 NBCMU01_SoftVer "SoftVer
软件版本";
CM_ SG_ 2561736609 NBCMU01_HardVer "HardVer
硬件版本";
CM_ SG_ 2561736609 NBCMU01_AliveCounter "Alive Counter";
BA_DEF_ SG_  "GenSigSendType" ENUM  "Cycle","OnChangeWithRepetition","OnChange","OnWriteWithRepetition","OnWrite","IfActiveWithRepetition","IfActive";
BA_DEF_ BO_  "GenMsgSendType" ENUM  "Cycle","Event","CycleEvent","IfActive";
BA_DEF_ BO_  "GenMsgCycleTime" INT 0 65536;
BA_DEF_ SG_  "SystemSignalLongSymbol" STRING ;
BA_DEF_DEF_  "GenSigSendType" "Cycle";
BA_DEF_DEF_  "GenMsgSendType" "Cycle";
BA_DEF_DEF_  "GenMsgCycleTime" 0;
BA_DEF_DEF_  "SystemSignalLongSymbol" "";
BA_ "GenMsgCycleTime" BO_ 2564357898 200;
BA_ "GenMsgCycleTime" BO_ 2564423434 200;
BA_ "GenMsgCycleTime" BO_ 2564488970 1000;
BA_ "GenMsgCycleTime" BO_ 2564554506 1000;
BA_ "GenMsgCycleTime" BO_ 2564620042 1000;
BA_ "GenMsgCycleTime" BO_ 2564685578 1000;
BA_ "GenMsgCycleTime" BO_ 2564751114 1000;
BA_ "GenMsgCycleTime" BO_ 2564947722 5000;
BA_ "GenMsgCycleTime" BO_ 2565013258 5000;
BA_ "GenMsgSendType" BO_ 2564677386 1;
BA_ "GenMsgCycleTime" BO_ 2562785035 100;
BA_ "GenMsgCycleTime" BO_ 2562850571 50;
BA_ "GenMsgCycleTime" BO_ 2562916107 500;
BA_ "GenMsgCycleTime" BO_ 2562981643 100;
BA_ "GenMsgCycleTime" BO_ 2563899147 200;
BA_ "GenMsgCycleTime" BO_ 2563964683 200;
BA_ "GenMsgCycleTime" BO_ 2564030219 200;
BA_ "GenMsgCycleTime" BO_ 2564095755 200;
BA_ "GenMsgCycleTime" BO_ 2564161291 200;
BA_ "GenMsgCycleTime" BO_ 2564226827 200;
BA_ "GenMsgCycleTime" BO_ 2564292363 200;
BA_ "GenMsgCycleTime" BO_ 2564357899 200;
BA_ "GenMsgCycleTime" BO_ 2564423435 200;
BA_ "GenMsgCycleTime" BO_ 2564488971 1000;
BA_ "GenMsgCycleTime" BO_ 2564554507 1000;
BA_ "GenMsgCycleTime" BO_ 2564620043 1000;
BA_ "GenMsgCycleTime" BO_ 2564685579 1000;
BA_ "GenMsgCycleTime" BO_ 2564751115 1000;
BA_ "GenMsgCycleTime" BO_ 2564947723 5000;
BA_ "GenMsgCycleTime" BO_ 2565013259 5000;
BA_ "GenMsgSendType" BO_ 2564677387 1;
BA_ "GenMsgCycleTime" BO_ 2562785036 100;
BA_ "GenMsgCycleTime" BO_ 2562850572 50;
BA_ "GenMsgCycleTime" BO_ 2562916108 500;
BA_ "GenMsgCycleTime" BO_ 2562981644 100;
BA_ "GenMsgCycleTime" BO_ 2563899148 200;
BA_ "GenMsgCycleTime" BO_ 2563964684 200;
BA_ "GenMsgCycleTime" BO_ 2564030220 200;
BA_ "GenMsgCycleTime" BO_ 2564095756 200;
BA_ "GenMsgCycleTime" BO_ 2564161292 200;
BA_ "GenMsgCycleTime" BO_ 2564226828 200;
BA_ "GenMsgCycleTime" BO_ 2564292364 200;
BA_ "GenMsgCycleTime" BO_ 2564357900 200;
BA_ "GenMsgCycleTime" BO_ 2564423436 200;
BA_ "GenMsgCycleTime" BO_ 2564488972 1000;
BA_ "GenMsgCycleTime" BO_ 2564554508 1000;
BA_ "GenMsgCycleTime" BO_ 2564620044 1000;
BA_ "GenMsgCycleTime" BO_ 2564685580 1000;
BA_ "GenMsgCycleTime" BO_ 2564751116 1000;
BA_ "GenMsgCycleTime" BO_ 2564947724 5000;
BA_ "GenMsgCycleTime" BO_ 2565013260 5000;
BA_ "GenMsgSendType" BO_ 2564677388 1;
BA_ "GenMsgCycleTime" BO_ 2562785057 100;
BA_ "GenMsgCycleTime" BO_ 2562916129 1000;
BA_ "GenMsgCycleTime" BO_ 2564488993 1000;
BA_ "GenMsgCycleTime" BO_ 2564554529 1000;
BA_ "GenMsgCycleTime" BO_ 2564620065 1000;
BA_ "GenMsgCycleTime" BO_ 2564685601 1000;
BA_ "GenMsgCycleTime" BO_ 2564751137 1000;
BA_ "GenMsgCycleTime" BO_ 2564947745 5000;
BA_ "GenMsgCycleTime" BO_ 2565013281 5000;
BA_ "GenMsgSendType" BO_ 2564677409 1;
BA_ "GenMsgCycleTime" BO_ 2562785058 100;
BA_ "GenMsgCycleTime" BO_ 2562916130 1000;
BA_ "GenMsgCycleTime" BO_ 2564488994 1000;
BA_ "GenMsgCycleTime" BO_ 2564554530 1000;
BA_ "GenMsgCycleTime" BO_ 2564620066 1000;
BA_ "GenMsgCycleTime" BO_ 2564685602 1000;
BA_ "GenMsgCycleTime" BO_ 2564751138 1000;
BA_ "GenMsgCycleTime" BO_ 2564947746 5000;
BA_ "GenMsgCycleTime" BO_ 2565013282 5000;
BA_ "GenMsgSendType" BO_ 2564677410 1;
BA_ "GenMsgCycleTime" BO_ 2562785059 100;
BA_ "GenMsgCycleTime" BO_ 2562916131 1000;
BA_ "GenMsgCycleTime" BO_ 2564488995 1000;
BA_ "GenMsgCycleTime" BO_ 2564554531 1000;
BA_ "GenMsgCycleTime" BO_ 2564620067 1000;
BA_ "GenMsgCycleTime" BO_ 2564685603 1000;
BA_ "GenMsgCycleTime" BO_ 2564751139 1000;
BA_ "GenMsgCycleTime" BO_ 2564947747 5000;
BA_ "GenMsgCycleTime" BO_ 2565013283 5000;
BA_ "GenMsgSendType" BO_ 2564677411 1;
BA_ "GenMsgCycleTime" BO_ 2562785060 100;
BA_ "GenMsgCycleTime" BO_ 2562916132 1000;
BA_ "GenMsgCycleTime" BO_ 2564488996 1000;
BA_ "GenMsgCycleTime" BO_ 2564554532 1000;
BA_ "GenMsgCycleTime" BO_ 2564620068 1000;
BA_ "GenMsgCycleTime" BO_ 2564685604 1000;
BA_ "GenMsgCycleTime" BO_ 2564751140 1000;
BA_ "GenMsgCycleTime" BO_ 2564947748 5000;
BA_ "GenMsgCycleTime" BO_ 2565013284 5000;
BA_ "GenMsgSendType" BO_ 2564677412 1;
BA_ "GenMsgCycleTime" BO_ 2562785061 100;
BA_ "GenMsgCycleTime" BO_ 2562916133 1000;
BA_ "GenMsgCycleTime" BO_ 2564488997 1000;
BA_ "GenMsgCycleTime" BO_ 2564554533 1000;
BA_ "GenMsgCycleTime" BO_ 2564620069 1000;
BA_ "GenMsgCycleTime" BO_ 2564685605 1000;
BA_ "GenMsgCycleTime" BO_ 2564751141 1000;
BA_ "GenMsgCycleTime" BO_ 2564947749 5000;
BA_ "GenMsgCycleTime" BO_ 2565013285 5000;
BA_ "GenMsgSendType" BO_ 2564677413 1;
BA_ "GenMsgCycleTime" BO_ 2562785062 100;
BA_ "GenMsgCycleTime" BO_ 2562916134 1000;
BA_ "GenMsgCycleTime" BO_ 2564488998 1000;
BA_ "GenMsgCycleTime" BO_ 2564554534 1000;
BA_ "GenMsgCycleTime" BO_ 2564620070 1000;
BA_ "GenMsgCycleTime" BO_ 2564685606 1000;
BA_ "GenMsgCycleTime" BO_ 2564751142 1000;
BA_ "GenMsgCycleTime" BO_ 2564947750 5000;
BA_ "GenMsgCycleTime" BO_ 2565013286 5000;
BA_ "GenMsgSendType" BO_ 2564677414 1;
BA_ "GenMsgCycleTime" BO_ 2562785063 100;
BA_ "GenMsgCycleTime" BO_ 2562916135 1000;
BA_ "GenMsgCycleTime" BO_ 2564488999 1000;
BA_ "GenMsgCycleTime" BO_ 2564554535 1000;
BA_ "GenMsgCycleTime" BO_ 2564620071 1000;
BA_ "GenMsgCycleTime" BO_ 2564685607 1000;
BA_ "GenMsgCycleTime" BO_ 2564751143 1000;
BA_ "GenMsgCycleTime" BO_ 2564947751 5000;
BA_ "GenMsgCycleTime" BO_ 2565013287 5000;
BA_ "GenMsgSendType" BO_ 2564677415 1;
BA_ "GenMsgCycleTime" BO_ 2562785064 100;
BA_ "GenMsgCycleTime" BO_ 2562916136 1000;
BA_ "GenMsgCycleTime" BO_ 2564489000 1000;
BA_ "GenMsgCycleTime" BO_ 2564554536 1000;
BA_ "GenMsgCycleTime" BO_ 2564620072 1000;
BA_ "GenMsgCycleTime" BO_ 2564685608 1000;
BA_ "GenMsgCycleTime" BO_ 2564751144 1000;
BA_ "GenMsgCycleTime" BO_ 2564947752 5000;
BA_ "GenMsgCycleTime" BO_ 2565013288 5000;
BA_ "GenMsgSendType" BO_ 2564677416 1;
BA_ "GenMsgCycleTime" BO_ 2562785065 100;
BA_ "GenMsgCycleTime" BO_ 2562916137 1000;
BA_ "GenMsgCycleTime" BO_ 2564489001 1000;
BA_ "GenMsgCycleTime" BO_ 2564554537 1000;
BA_ "GenMsgCycleTime" BO_ 2564620073 1000;
BA_ "GenMsgCycleTime" BO_ 2564685609 1000;
BA_ "GenMsgCycleTime" BO_ 2564751145 1000;
BA_ "GenMsgCycleTime" BO_ 2564947753 5000;
BA_ "GenMsgCycleTime" BO_ 2565013289 5000;
BA_ "GenMsgSendType" BO_ 2564677417 1;
BA_ "GenMsgCycleTime" BO_ 2562785066 100;
BA_ "GenMsgCycleTime" BO_ 2562916138 1000;
BA_ "GenMsgCycleTime" BO_ 2564489002 1000;
BA_ "GenMsgCycleTime" BO_ 2564554538 1000;
BA_ "GenMsgCycleTime" BO_ 2564620074 1000;
BA_ "GenMsgCycleTime" BO_ 2564685610 1000;
BA_ "GenMsgCycleTime" BO_ 2564751146 1000;
BA_ "GenMsgCycleTime" BO_ 2564947754 5000;
BA_ "GenMsgCycleTime" BO_ 2565013290 5000;
BA_ "GenMsgSendType" BO_ 2564677418 1;
BA_ "GenMsgCycleTime" BO_ 2562785067 100;
BA_ "GenMsgCycleTime" BO_ 2562916139 1000;
BA_ "GenMsgCycleTime" BO_ 2564489003 1000;
BA_ "GenMsgCycleTime" BO_ 2564554539 1000;
BA_ "GenMsgCycleTime" BO_ 2564620075 1000;
BA_ "GenMsgCycleTime" BO_ 2564685611 1000;
BA_ "GenMsgCycleTime" BO_ 2564751147 1000;
BA_ "GenMsgCycleTime" BO_ 2564947755 5000;
BA_ "GenMsgCycleTime" BO_ 2565013291 5000;
BA_ "GenMsgSendType" BO_ 2564677419 1;
BA_ "GenMsgCycleTime" BO_ 2562785068 100;
BA_ "GenMsgCycleTime" BO_ 2562916140 1000;
BA_ "GenMsgCycleTime" BO_ 2564489004 1000;
BA_ "GenMsgCycleTime" BO_ 2564554540 1000;
BA_ "GenMsgCycleTime" BO_ 2564620076 1000;
BA_ "GenMsgCycleTime" BO_ 2564685612 1000;
BA_ "GenMsgCycleTime" BO_ 2564751148 1000;
BA_ "GenMsgCycleTime" BO_ 2564947756 5000;
BA_ "GenMsgCycleTime" BO_ 2565013292 5000;
BA_ "GenMsgSendType" BO_ 2564677420 1;
BA_ "GenMsgCycleTime" BO_ 2562129824 10;
BA_ "GenMsgCycleTime" BO_ 2561736609 100;
VAL_ 2562785035 NBICU11_AddrInput_State 0 " Disable " 1 " Enable " ;
VAL_ 2562785035 NBICU11_AddrOutput_State 0 " Disable " 1 " Enable " ;
VAL_ 2562785036 NBICU12_AddrInput_State 0 " Disable " 1 " Enable " ;
VAL_ 2562785036 NBICU12_AddrOutput_State 0 " Disable " 1 " Enable " ;
VAL_ 2562785057 SBICU01_CellTemp_HighWarning 0 " Normal " 1 " Level 1 Warning " 2 " Level 2 Warning " 3 " Level 3 Warning " ;
VAL_ 2562785057 SBICU01_AddrInput_State 0 " Disable " 1 " Enable " ;
VAL_ 2562785057 SBICU01_AddrOutput_State 0 " Disable " 1 " Enable " ;
VAL_ 2562785058 SBICU02_CellTemp_HighWarning 0 " Normal " 1 " Level 1 Warning " 2 " Level 2 Warning " 3 " Level 3 Warning " ;
VAL_ 2562785058 SBICU02_AddrInput_State 0 " Disable " 1 " Enable " ;
VAL_ 2562785058 SBICU02_AddrOutput_State 0 " Disable " 1 " Enable " ;
VAL_ 2562785059 SBICU03_CellTemp_HighWarning 0 " Normal " 1 " Level 1 Warning " 2 " Level 2 Warning " 3 " Level 3 Warning " ;
VAL_ 2562785059 SBICU03_AddrInput_State 0 " Disable " 1 " Enable " ;
VAL_ 2562785059 SBICU03_AddrOutput_State 0 " Disable " 1 " Enable " ;
VAL_ 2562785060 SBICU04_CellTemp_HighWarning 0 " Normal " 1 " Level 1 Warning " 2 " Level 2 Warning " 3 " Level 3 Warning " ;
VAL_ 2562785060 SBICU04_AddrInput_State 0 " Disable " 1 " Enable " ;
VAL_ 2562785060 SBICU04_AddrOutput_State 0 " Disable " 1 " Enable " ;
VAL_ 2562785061 SBICU05_CellTemp_HighWarning 0 " Normal " 1 " Level 1 Warning " 2 " Level 2 Warning " 3 " Level 3 Warning " ;
VAL_ 2562785061 SBICU05_AddrInput_State 0 " Disable " 1 " Enable " ;
VAL_ 2562785061 SBICU05_AddrOutput_State 0 " Disable " 1 " Enable " ;
VAL_ 2562785062 SBICU06_CellTemp_HighWarning 0 " Normal " 1 " Level 1 Warning " 2 " Level 2 Warning " 3 " Level 3 Warning " ;
VAL_ 2562785062 SBICU06_AddrInput_State 0 " Disable " 1 " Enable " ;
VAL_ 2562785062 SBICU06_AddrOutput_State 0 " Disable " 1 " Enable " ;
VAL_ 2562785063 SBICU07_CellTemp_HighWarning 0 " Normal " 1 " Level 1 Warning " 2 " Level 2 Warning " 3 " Level 3 Warning " ;
VAL_ 2562785063 SBICU07_AddrInput_State 0 " Disable " 1 " Enable " ;
VAL_ 2562785063 SBICU07_AddrOutput_State 0 " Disable " 1 " Enable " ;
VAL_ 2562785064 SBICU08_CellTemp_HighWarning 0 " Normal " 1 " Level 1 Warning " 2 " Level 2 Warning " 3 " Level 3 Warning " ;
VAL_ 2562785064 SBICU08_AddrInput_State 0 " Disable " 1 " Enable " ;
VAL_ 2562785064 SBICU08_AddrOutput_State 0 " Disable " 1 " Enable " ;
VAL_ 2562785065 SBICU09_CellTemp_HighWarning 0 " Normal " 1 " Level 1 Warning " 2 " Level 2 Warning " 3 " Level 3 Warning " ;
VAL_ 2562785065 SBICU09_AddrInput_State 0 " Disable " 1 " Enable " ;
VAL_ 2562785065 SBICU09_AddrOutput_State 0 " Disable " 1 " Enable " ;
VAL_ 2562785066 SBICU10_CellTemp_HighWarning 0 " Normal " 1 " Level 1 Warning " 2 " Level 2 Warning " 3 " Level 3 Warning " ;
VAL_ 2562785066 SBICU10_AddrInput_State 0 " Disable " 1 " Enable " ;
VAL_ 2562785066 SBICU10_AddrOutput_State 0 " Disable " 1 " Enable " ;
VAL_ 2562785067 SBICU11_CellTemp_HighWarning 0 " Normal " 1 " Level 1 Warning " 2 " Level 2 Warning " 3 " Level 3 Warning " ;
VAL_ 2562785067 SBICU11_AddrInput_State 0 " Disable " 1 " Enable " ;
VAL_ 2562785067 SBICU11_AddrOutput_State 0 " Disable " 1 " Enable " ;
VAL_ 2562785068 SBICU12_CellTemp_HighWarning 0 " Normal " 1 " Level 1 Warning " 2 " Level 2 Warning " 3 " Level 3 Warning " ;
VAL_ 2562785068 SBICU12_AddrInput_State 0 " Disable " 1 " Enable " ;
VAL_ 2562785068 SBICU12_AddrOutput_State 0 " Disable " 1 " Enable " ;
VAL_ 2561736609 NBCMU01_Contactor_state_Negative 0 " open " 1 " close " ;
VAL_ 2561736609 NBCMU01_Contactor_state_Positive 0 " open " 1 " close " ;
VAL_ 2561736609 NBCMU01_Contactor_state_PreChrg 0 " open " 1 " close " ;
VAL_ 2561736609 NBCMU01_Contactor_state_Heat 0 " open " 1 " close " ;
VAL_ 2561736609 NBCMU01_WorkState 0 " Invalid " 1 " Standby " 2 " Discharging " 3 " Charging " 4 " Warning " 5 " Fault " 6 " reserved " 7 " reserved " ;
